VERSION ""

NS_ :

BS_:

BU_: ETH

BO_ 1480 EPBL_alertLog: 8 Vector__XXX
 SG_ EPBL_alertID M : 0|9@1+ (1,0) [0|0] "" Vector__XXX
 SG_ EPBL_alertState : 15|1@1+ (1,0) [0|0] "" Vector__XXX
 SG_ EPBL_a000_alertDataW0 m0 : 16|16@1+ (1,0) [0|0] "" Vector__XXX
 SG_ EPBL_a001_InternalWatchdog m1 : 16|1@1+ (1,0) [0|0] "" Vector__XXX
 SG_ EPBL_a002_CPUUndervoltage m2 : 16|1@1+ (1,0) [0|0] "" Vector__XXX
 SG_ EPBL_a003_AssertID m3 : 16|16@1+ (1,0) [0|0] "" Vector__XXX
 SG_ EPBL_a005_busID0 m5 : 16|4@1+ (1,0) [0|0] "" Vector__XXX
 SG_ EPBL_a006_busID m6 : 16|4@1+ (1,0) [0|0] "" Vector__XXX
 SG_ EPBL_a012_ClockError m12 : 16|1@1+ (1,0) [0|0] "" Vector__XXX
 SG_ EPBL_a013_LogQueueFull m13 : 16|1@1+ (1,0) [0|0] "" Vector__XXX
 SG_ EPBL_a015_NVMMMemOverflow m15 : 16|1@1+ (1,0) [0|0] "" Vector__XXX
 SG_ EPBL_a016_NVMMRecordID m16 : 16|16@1+ (1,0) [0|0] "" Vector__XXX
 SG_ EPBL_a021_Task1msLate m21 : 16|1@1+ (1,0) [0|0] "" Vector__XXX
 SG_ EPBL_a022_TaskInitErrorCount m22 : 16|8@1+ (1,0) [0|0] "" Vector__XXX
 SG_ EPBL_a030_logId m30 : 16|4@1+ (1,0) [0|0] "" Vector__XXX
 SG_ EPBL_a031_uds_bytes_0 m31 : 16|8@1+ (1,0) [0|0] "" Vector__XXX
 SG_ EPBL_a041_CPULoadTotal m41 : 16|8@1+ (1,0) [0|0] "" Vector__XXX
 SG_ EPBL_a042_Usage1msTask m42 : 16|8@1+ (1,0) [0|0] "" Vector__XXX
 SG_ EPBL_a043_CallTrace0 m43 : 16|24@1+ (1,0) [0|0] "" Vector__XXX
 SG_ EPBL_a044_CallTrace0 m44 : 16|24@1+ (1,0) [0|0] "" Vector__XXX
 SG_ EPBL_a045_CallTrace0 m45 : 16|24@1+ (1,0) [0|0] "" Vector__XXX
 SG_ EPBL_a046_CallTrace0 m46 : 16|24@1+ (1,0) [0|0] "" Vector__XXX
 SG_ EPBL_a057_VEH_cpControl m57 : 16|1@1+ (1,0) [0|0] "" Vector__XXX
 SG_ EPBL_a058_voltageDrop m58 : 16|12@1+ (0.005443676098,0) [0|0] "" Vector__XXX
 SG_ EPBL_a059_voltageDrop m59 : 16|12@1+ (0.005443676098,0) [0|0] "" Vector__XXX
 SG_ EPBL_a060_lockoutDisabled m60 : 16|1@1+ (1,0) [0|0] "" Vector__XXX
 SG_ EPBL_a063_switchChannel m63 : 16|8@1+ (1,0) [0|0] "" Vector__XXX
 SG_ EPBL_a064_busBitField m64 : 16|8@1+ (1,0) [0|0] "" Vector__XXX
 SG_ EPBL_a081_VEH_defogInfoMessage m81 : 16|1@1+ (1,0) [0|0] "" Vector__XXX
 SG_ EPBL_a082_RIPC_epbPrivateState m82 : 16|1@1+ (1,0) [0|0] "" Vector__XXX
 SG_ EPBL_a083_LIPC_epbPrivateState m83 : 16|1@1+ (1,0) [0|0] "" Vector__XXX
 SG_ EPBL_a084_CH_StatusC m84 : 16|1@1+ (1,0) [0|0] "" Vector__XXX
 SG_ EPBL_a085_PARTY_buttonStatus m85 : 16|1@1+ (1,0) [0|0] "" Vector__XXX
 SG_ EPBL_a086_VEH_LVBMS_statusHigh m86 : 16|1@1+ (1,0) [0|0] "" Vector__XXX
 SG_ EPBL_a087_VEH_temperature m87 : 16|1@1+ (1,0) [0|0] "" Vector__XXX
 SG_ EPBL_a088_VEH_temperature m88 : 16|1@1+ (1,0) [0|0] "" Vector__XXX
 SG_ EPBL_a089_PARTY_party1 m89 : 16|1@1+ (1,0) [0|0] "" Vector__XXX
 SG_ EPBL_a090_VEH_chNm m90 : 16|1@1+ (1,0) [0|0] "" Vector__XXX
 SG_ EPBL_a091_VEH_faultsAndExtras m91 : 16|1@1+ (1,0) [0|0] "" Vector__XXX
 SG_ EPBL_a092_VEH_restraintStatus m92 : 16|1@1+ (1,0) [0|0] "" Vector__XXX
 SG_ EPBL_a093_VEH_restraintStatus m93 : 16|1@1+ (1,0) [0|0] "" Vector__XXX
 SG_ EPBL_a094_VEH_sysStatus m94 : 16|1@1+ (1,0) [0|0] "" Vector__XXX
 SG_ EPBL_a095_PT_ptNm m95 : 16|1@1+ (1,0) [0|0] "" Vector__XXX
 SG_ EPBL_a096_VEH_status m96 : 16|1@1+ (1,0) [0|0] "" Vector__XXX
 SG_ EPBL_a097_VEH_HVStatus m97 : 16|1@1+ (1,0) [0|0] "" Vector__XXX
 SG_ EPBL_a098_CH_torque m98 : 16|1@1+ (1,0) [0|0] "" Vector__XXX
 SG_ EPBL_a099_VEH_oocStatus m99 : 16|1@1+ (1,0) [0|0] "" Vector__XXX
 SG_ EPBL_a100_VEH m100 : 16|1@1+ (1,0) [0|0] "" Vector__XXX
 SG_ EPBL_a101_VEH_state m101 : 16|1@1+ (1,0) [0|0] "" Vector__XXX
 SG_ EPBL_a102_VEH_faultsAndExtras m102 : 16|1@1+ (1,0) [0|0] "" Vector__XXX
 SG_ EPBL_a103_VEH_hvsNm m103 : 16|1@1+ (1,0) [0|0] "" Vector__XXX
 SG_ EPBL_a104_PARTY_redundantBrakingControl m104 : 16|1@1+ (1,0) [0|0] "" Vector__XXX
 SG_ EPBL_a105_VEH_states m105 : 16|1@1+ (1,0) [0|0] "" Vector__XXX
 SG_ EPBL_a106_VEH_dcdcStatus m106 : 16|1@1+ (1,0) [0|0] "" Vector__XXX
 SG_ EPBL_a107_VEH_hvsNm m107 : 16|1@1+ (1,0) [0|0] "" Vector__XXX
 SG_ EPBL_a108_VEH_hvStatus m108 : 16|1@1+ (1,0) [0|0] "" Vector__XXX
 SG_ EPBL_a109_PARTY_status m109 : 16|1@1+ (1,0) [0|0] "" Vector__XXX
 SG_ EPBL_a110_VEH_powerRequests m110 : 16|1@1+ (1,0) [0|0] "" Vector__XXX
 SG_ EPBL_a111_VEH_internalStatus m111 : 16|1@1+ (1,0) [0|0] "" Vector__XXX
 SG_ EPBL_a112_VEH_internalStatus m112 : 16|1@1+ (1,0) [0|0] "" Vector__XXX
 SG_ EPBL_a113_VEH_ethNm m113 : 16|1@1+ (1,0) [0|0] "" Vector__XXX
 SG_ EPBL_a114_PARTY_status m114 : 16|1@1+ (1,0) [0|0] "" Vector__XXX
 SG_ EPBL_a115_VEH_vehNm m115 : 16|1@1+ (1,0) [0|0] "" Vector__XXX
 SG_ EPBL_a116_LIPC_doorStatus m116 : 16|1@1+ (1,0) [0|0] "" Vector__XXX
 SG_ EPBL_a117_LIPC_doorStatus m117 : 16|1@1+ (1,0) [0|0] "" Vector__XXX
 SG_ EPBL_a118_VEH_vehNm m118 : 16|1@1+ (1,0) [0|0] "" Vector__XXX
 SG_ EPBL_a119_VEH_steerAngle m119 : 16|1@1+ (1,0) [0|0] "" Vector__XXX
 SG_ EPBL_a120_PARTY_chassisCntl m120 : 16|1@1+ (1,0) [0|0] "" Vector__XXX
 SG_ EPBL_a121_caliperState m121 : 16|4@1+ (1,0) [0|0] "" Vector__XXX
 SG_ EPBL_a122_filteredCurrentCal m122 : 16|12@1+ (0.01,0) [0|0] "" Vector__XXX
 SG_ EPBL_a123_filteredCurrentCal m123 : 16|12@1+ (0.01,0) [0|0] "" Vector__XXX
 SG_ EPBL_a124_calOutOfBoundsData m124 : 16|1@1+ (1,0) [0|0] "" Vector__XXX
 SG_ EPBL_a125_pvFilt m125 : 16|12@1+ (0.005443676098,0) [0|0] "" Vector__XXX
 SG_ EPBL_a126_pvFilt m126 : 16|12@1+ (0.005443676098,0) [0|0] "" Vector__XXX
 SG_ EPBL_a127_pvFilt m127 : 16|12@1+ (0.005443676098,0) [0|0] "" Vector__XXX
 SG_ EPBL_a128_pvFilt m128 : 16|12@1+ (0.005443676098,0) [0|0] "" Vector__XXX
 SG_ EPBL_a129_VEH_occupancy m129 : 16|1@1+ (1,0) [0|0] "" Vector__XXX
 SG_ EPBL_a134_pvFilt m134 : 16|12@1+ (0.005443676098,0) [0|0] "" Vector__XXX
 SG_ EPBL_a135_pvFilt m135 : 16|12@1+ (0.005443676098,0) [0|0] "" Vector__XXX
 SG_ EPBL_a136_pvFilt m136 : 16|12@1+ (0.005443676098,0) [0|0] "" Vector__XXX
 SG_ EPBL_a137_pvFilt m137 : 16|12@1+ (0.005443676098,0) [0|0] "" Vector__XXX
 SG_ EPBL_a138_localState m138 : 16|3@1+ (1,0) [0|0] "" Vector__XXX
 SG_ EPBL_a139_localState m139 : 16|3@1+ (1,0) [0|0] "" Vector__XXX
 SG_ EPBL_a140_stateTime m140 : 16|32@1+ (1,0) [0|0] "" Vector__XXX
 SG_ EPBL_a141_fromState m141 : 16|5@1+ (1,0) [0|0] "" Vector__XXX
 SG_ EPBL_a170_pvFilt m170 : 16|12@1+ (0.005443676098,0) [0|0] "" Vector__XXX
 SG_ EPBL_a171_pvFilt m171 : 16|12@1+ (0.005443676098,0) [0|0] "" Vector__XXX
 SG_ EPBL_a173_esmState m173 : 16|5@1+ (1,0) [0|0] "" Vector__XXX
 SG_ EPBL_a174_esmState m174 : 16|5@1+ (1,0) [0|0] "" Vector__XXX
 SG_ EPBL_a175_esmState m175 : 16|5@1+ (1,0) [0|0] "" Vector__XXX
 SG_ EPBL_a176_esmState m176 : 16|5@1+ (1,0) [0|0] "" Vector__XXX
 SG_ EPBL_a177_esmState m177 : 16|5@1+ (1,0) [0|0] "" Vector__XXX
 SG_ EPBL_a178_localCaliperState m178 : 16|3@1+ (1,0) [0|0] "" Vector__XXX
 SG_ EPBL_a179_esmState m179 : 16|5@1+ (1,0) [0|0] "" Vector__XXX
 SG_ EPBL_a180_esmOpTrigger m180 : 16|6@1+ (1,0) [0|0] "" Vector__XXX
 SG_ EPBL_a181_grade m181 : 16|7@1- (1,0) [0|0] "" Vector__XXX
 SG_ EPBL_a182_epbSystemStatus m182 : 16|4@1+ (1,0) [0|0] "" Vector__XXX
 SG_ EPBL_a183_isRetransmit m183 : 16|1@1+ (1,0) [0|0] "" Vector__XXX
 SG_ EPBL_a184_esmOpTrigger m184 : 16|6@1+ (1,0) [0|0] "" Vector__XXX
 SG_ EPBL_a185_summonFaultReason m185 : 16|5@1+ (1,0) [0|0] "" Vector__XXX
 SG_ EPBL_a186_esmOpTrigger m186 : 16|6@1+ (1,0) [0|0] "" Vector__XXX
 SG_ EPBL_a187_esmOpTrigger m187 : 16|6@1+ (1,0) [0|0] "" Vector__XXX
 SG_ EPBL_a188_esmOpTrigger m188 : 16|6@1+ (1,0) [0|0] "" Vector__XXX
 SG_ EPBL_a189_esmOpTrigger m189 : 16|6@1+ (1,0) [0|0] "" Vector__XXX
 SG_ EPBL_a190_esmState m190 : 16|5@1+ (1,0) [0|0] "" Vector__XXX
 SG_ EPBL_a191_esmState m191 : 16|5@1+ (1,0) [0|0] "" Vector__XXX
 SG_ EPBL_a198_voltageAvgDelta m198 : 16|9@1+ (0.043549408784,0) [0|0] "" Vector__XXX
 SG_ EPBL_a202_localEpbConfig m202 : 16|4@1+ (1,0) [0|0] "" Vector__XXX
 SG_ EPBL_a203_gtwConfig m203 : 16|4@1+ (1,0) [0|0] "" Vector__XXX
 SG_ EPBL_a210_driverLeftForScore m210 : 16|1@1+ (1,0) [0|0] "" Vector__XXX
 SG_ EPBL_a216_noData m216 : 16|1@1+ (1,0) [0|0] "" Vector__XXX
 SG_ EPBL_a217_byte4 m217 : 16|8@1+ (1,0) [0|0] "" Vector__XXX
 SG_ EPBL_a225_esmOpTrigger m225 : 16|6@1+ (1,0) [0|0] "" Vector__XXX
 SG_ EPBL_a241_desiredState m241 : 16|1@1+ (1,0) [0|0] "" Vector__XXX
 SG_ EPBL_a242_hvcDesiredState m242 : 16|1@1+ (1,0) [0|0] "" Vector__XXX
 SG_ EPBL_a243_brakeMasterCylPress m243 : 16|1@1+ (1,0) [0|0] "" Vector__XXX
 SG_ EPBL_a244_permissiveMode m244 : 16|1@1+ (1,0) [0|0] "" Vector__XXX
 SG_ EPBL_a246_previousState m246 : 16|5@1+ (1,0) [0|0] "" Vector__XXX
 SG_ EPBL_a247_esmState m247 : 16|5@1+ (1,0) [0|0] "" Vector__XXX
 SG_ EPBL_a248_esmState m248 : 16|5@1+ (1,0) [0|0] "" Vector__XXX
 SG_ EPBL_a249_previousState m249 : 16|5@1+ (1,0) [0|0] "" Vector__XXX
 SG_ EPBL_a250_esmSpeedClass m250 : 16|3@1+ (1,0) [0|0] "" Vector__XXX
 SG_ EPBL_a251_currentVariance m251 : 16|12@1+ (0.01,0) [0|0] "" Vector__XXX
 SG_ EPBL_a253_esmState m253 : 16|5@1+ (1,0) [0|0] "" Vector__XXX
 SG_ EPBL_a256_esmState m256 : 16|5@1+ (1,0) [0|0] "" Vector__XXX
 SG_ EPBL_a262_inputVoltageTooLow m262 : 16|1@1+ (1,0) [0|0] "" Vector__XXX
 SG_ EPBL_a263_esmState m263 : 16|5@1+ (1,0) [0|0] "" Vector__XXX
 SG_ EPBL_a264_uiWinchModeRequestExit m264 : 16|1@1+ (1,0) [0|0] "" Vector__XXX
 SG_ EPBL_a272_expectedState m272 : 16|2@1+ (1,0) [0|0] "" Vector__XXX
 SG_ EPBL_a300_harnessId m300 : 16|8@1+ (1,0) [0|0] "" Vector__XXX
 SG_ EPBL_a301_setSpeed m301 : 16|16@1+ (0.05,0) [0|0] "" Vector__XXX
 SG_ EPBL_a302_pistonPosition m302 : 16|13@1- (9.768009768009769,0) [0|0] "" Vector__XXX
 SG_ EPBL_a303_currentVariance m303 : 16|12@1+ (0.01,0) [0|0] "" Vector__XXX
 SG_ EPBL_a350_ensPeriod m350 : 16|16@1+ (0.0001,0) [0|0] "" Vector__XXX
 SG_ EPBL_a352_pointsAboveThreshold m352 : 16|10@1+ (1,0) [0|0] "" Vector__XXX
 SG_ EPBL_a353_alertPath m353 : 16|2@1+ (1,0) [0|0] "" Vector__XXX
 SG_ EPBL_a355_brakeHwConfig m355 : 16|4@1+ (1,0) [0|0] "" Vector__XXX
 SG_ EPBL_a357_epbSystemStatus m357 : 16|4@1+ (1,0) [0|0] "" Vector__XXX
 SG_ EPBL_a358_epbSystemStatus m358 : 16|4@1+ (1,0) [0|0] "" Vector__XXX
 SG_ EPBL_a362_brakeMasterCylPress m362 : 16|12@1- (0.1,130) [0|0] "" Vector__XXX
 SG_ EPBL_a363_brakeMasterCylPress m363 : 16|12@1- (0.1,130) [0|0] "" Vector__XXX
 SG_ EPBL_a364_masterCylOffsetComp m364 : 16|12@1- (0.05,0) [0|0] "" Vector__XXX
 SG_ EPBL_a365_epbSystemStatus m365 : 16|4@1+ (1,0) [0|0] "" Vector__XXX
 SG_ EPBL_a366_epbSystemStatus m366 : 16|4@1+ (1,0) [0|0] "" Vector__XXX
 SG_ EPBL_a370_messageID m370 : 16|11@1+ (1,0) [0|0] "" Vector__XXX
 SG_ EPBL_a002_PowerOnReset m2 : 17|1@1+ (1,0) [0|0] "" Vector__XXX
 SG_ EPBL_a012_FlashError m12 : 17|1@1+ (1,0) [0|0] "" Vector__XXX
 SG_ EPBL_a013_ClearQueueFull m13 : 17|1@1+ (1,0) [0|0] "" Vector__XXX
 SG_ EPBL_a015_NVMMFilesystemError m15 : 17|1@1+ (1,0) [0|0] "" Vector__XXX
 SG_ EPBL_a021_Task1msStarved m21 : 17|1@1+ (1,0) [0|0] "" Vector__XXX
 SG_ EPBL_a060_resetUnlocked m60 : 17|1@1+ (1,0) [0|0] "" Vector__XXX
 SG_ EPBL_a082_RIPC_remoteHSD m82 : 17|1@1+ (1,0) [0|0] "" Vector__XXX
 SG_ EPBL_a083_LIPC_remoteHSD m83 : 17|1@1+ (1,0) [0|0] "" Vector__XXX
 SG_ EPBL_a086_VEH_LVBMS_statusLow m86 : 17|1@1+ (1,0) [0|0] "" Vector__XXX
 SG_ EPBL_a087_VEH_thermalControl m87 : 17|1@1+ (1,0) [0|0] "" Vector__XXX
 SG_ EPBL_a088_VEH_thermalControl m88 : 17|1@1+ (1,0) [0|0] "" Vector__XXX
 SG_ EPBL_a089_PARTY_status m89 : 17|1@1+ (1,0) [0|0] "" Vector__XXX
 SG_ EPBL_a090_VEH_state m90 : 17|1@1+ (1,0) [0|0] "" Vector__XXX
 SG_ EPBL_a091_VEH_info m91 : 17|1@1+ (1,0) [0|0] "" Vector__XXX
 SG_ EPBL_a092_VEH_switchStatus m92 : 17|1@1+ (1,0) [0|0] "" Vector__XXX
 SG_ EPBL_a093_VEH_switchStatus m93 : 17|1@1+ (1,0) [0|0] "" Vector__XXX
 SG_ EPBL_a094_PARTY_sysStatus m94 : 17|1@1+ (1,0) [0|0] "" Vector__XXX
 SG_ EPBL_a095_PT_status m95 : 17|1@1+ (1,0) [0|0] "" Vector__XXX
 SG_ EPBL_a096_CH_status m96 : 17|1@1+ (1,0) [0|0] "" Vector__XXX
 SG_ EPBL_a097_VEH_state m97 : 17|1@1+ (1,0) [0|0] "" Vector__XXX
 SG_ EPBL_a098_VEH_hvStatus m98 : 17|1@1+ (1,0) [0|0] "" Vector__XXX
 SG_ EPBL_a100_PARTY m100 : 17|1@1+ (1,0) [0|0] "" Vector__XXX
 SG_ EPBL_a101_PARTY_locState m101 : 17|1@1+ (1,0) [0|0] "" Vector__XXX
 SG_ EPBL_a102_VEH_feedbackStatus m102 : 17|1@1+ (1,0) [0|0] "" Vector__XXX
 SG_ EPBL_a103_VEH_vehNm m103 : 17|1@1+ (1,0) [0|0] "" Vector__XXX
 SG_ EPBL_a104_CH_redundantBrakingControl m104 : 17|1@1+ (1,0) [0|0] "" Vector__XXX
 SG_ EPBL_a105_VEH_chNm m105 : 17|1@1+ (1,0) [0|0] "" Vector__XXX
 SG_ EPBL_a106_VEH_thermalControl m106 : 17|1@1+ (1,0) [0|0] "" Vector__XXX
 SG_ EPBL_a107_VEH_vehNm m107 : 17|1@1+ (1,0) [0|0] "" Vector__XXX
 SG_ EPBL_a108_VEH_temperature m108 : 17|1@1+ (1,0) [0|0] "" Vector__XXX
 SG_ EPBL_a109_PARTY_inertial2 m109 : 17|1@1+ (1,0) [0|0] "" Vector__XXX
 SG_ EPBL_a110_VEH_carState m110 : 17|1@1+ (1,0) [0|0] "" Vector__XXX
 SG_ EPBL_a111_VEH_status m111 : 17|1@1+ (1,0) [0|0] "" Vector__XXX
 SG_ EPBL_a112_VEH_status m112 : 17|1@1+ (1,0) [0|0] "" Vector__XXX
 SG_ EPBL_a113_VEH_hvacRequest m113 : 17|1@1+ (1,0) [0|0] "" Vector__XXX
 SG_ EPBL_a114_PARTY_wheelSpeeds m114 : 17|1@1+ (1,0) [0|0] "" Vector__XXX
 SG_ EPBL_a115_VEH_authentication m115 : 17|1@1+ (1,0) [0|0] "" Vector__XXX
 SG_ EPBL_a116_RIPC_doorStatus m116 : 17|1@1+ (1,0) [0|0] "" Vector__XXX
 SG_ EPBL_a117_RIPC_doorStatus m117 : 17|1@1+ (1,0) [0|0] "" Vector__XXX
 SG_ EPBL_a118_VEH_lighting m118 : 17|1@1+ (1,0) [0|0] "" Vector__XXX
 SG_ EPBL_a119_VEH_leftStalk m119 : 17|1@1+ (1,0) [0|0] "" Vector__XXX
 SG_ EPBL_a120_VEH_systemStatus m120 : 17|1@1+ (1,0) [0|0] "" Vector__XXX
 SG_ EPBL_a183_localCdpState m183 : 17|2@1+ (1,0) [0|0] "" Vector__XXX
 SG_ EPBL_a210_driverLeftForAllSensors m210 : 17|1@1+ (1,0) [0|0] "" Vector__XXX
 SG_ EPBL_a216_spiFault m216 : 17|1@1+ (1,0) [0|0] "" Vector__XXX
 SG_ EPBL_a241_currentState m241 : 17|1@1+ (1,0) [0|0] "" Vector__XXX
 SG_ EPBL_a242_hvcCurrentState m242 : 17|1@1+ (1,0) [0|0] "" Vector__XXX
 SG_ EPBL_a243_brakeMasterCylPressQF m243 : 17|1@1+ (1,0) [0|0] "" Vector__XXX
 SG_ EPBL_a262_notStopped m262 : 17|1@1+ (1,0) [0|0] "" Vector__XXX
 SG_ EPBL_a264_uiGearStripParkPressed m264 : 17|1@1+ (1,0) [0|0] "" Vector__XXX
 SG_ EPBL_a012_SoftwareReset m12 : 18|1@1+ (1,0) [0|0] "" Vector__XXX
 SG_ EPBL_a015_NVMMRecordIDError m15 : 18|1@1+ (1,0) [0|0] "" Vector__XXX
 SG_ EPBL_a021_Task1msMissed m21 : 18|1@1+ (1,0) [0|0] "" Vector__XXX
 SG_ EPBL_a082_RIPC_railStatus m82 : 18|1@1+ (1,0) [0|0] "" Vector__XXX
 SG_ EPBL_a083_LIPC_railStatus m83 : 18|1@1+ (1,0) [0|0] "" Vector__XXX
 SG_ EPBL_a086_VEH_status m86 : 18|1@1+ (1,0) [0|0] "" Vector__XXX
 SG_ EPBL_a087_VEH_torque m87 : 18|1@1+ (1,0) [0|0] "" Vector__XXX
 SG_ EPBL_a088_VEH_torque m88 : 18|1@1+ (1,0) [0|0] "" Vector__XXX
 SG_ EPBL_a089_VEH_status m89 : 18|1@1+ (1,0) [0|0] "" Vector__XXX
 SG_ EPBL_a090_PARTY_eacMonitor m90 : 18|1@1+ (1,0) [0|0] "" Vector__XXX
 SG_ EPBL_a091_VEH_state m91 : 18|1@1+ (1,0) [0|0] "" Vector__XXX
 SG_ EPBL_a092_VEH_seatStatus2 m92 : 18|1@1+ (1,0) [0|0] "" Vector__XXX
 SG_ EPBL_a093_VEH_seatStatus2 m93 : 18|1@1+ (1,0) [0|0] "" Vector__XXX
 SG_ EPBL_a098_VEH_status m98 : 18|1@1+ (1,0) [0|0] "" Vector__XXX
 SG_ EPBL_a100_PT m100 : 18|1@1+ (1,0) [0|0] "" Vector__XXX
 SG_ EPBL_a101_LIPC_externalWatchdogHeartBeat m101 : 18|1@1+ (1,0) [0|0] "" Vector__XXX
 SG_ EPBL_a102_VEH_sensorStatus m102 : 18|1@1+ (1,0) [0|0] "" Vector__XXX
 SG_ EPBL_a103_VEH_status m103 : 18|1@1+ (1,0) [0|0] "" Vector__XXX
 SG_ EPBL_a104_LIPC_status m104 : 18|1@1+ (1,0) [0|0] "" Vector__XXX
 SG_ EPBL_a105_VEH_dampingStates m105 : 18|1@1+ (1,0) [0|0] "" Vector__XXX
 SG_ EPBL_a106_VEH_dcdcRailStatus m106 : 18|1@1+ (1,0) [0|0] "" Vector__XXX
 SG_ EPBL_a107_VEH_status m107 : 18|1@1+ (1,0) [0|0] "" Vector__XXX
 SG_ EPBL_a108_VEH_thermalControl m108 : 18|1@1+ (1,0) [0|0] "" Vector__XXX
 SG_ EPBL_a109_PARTY_nearDeploy m109 : 18|1@1+ (1,0) [0|0] "" Vector__XXX
 SG_ EPBL_a110_VEH_carConfig m110 : 18|1@1+ (1,0) [0|0] "" Vector__XXX
 SG_ EPBL_a111_VEH_vehNm m111 : 18|1@1+ (1,0) [0|0] "" Vector__XXX
 SG_ EPBL_a112_VEH_vehNm m112 : 18|1@1+ (1,0) [0|0] "" Vector__XXX
 SG_ EPBL_a113_VEH_chargeRequest m113 : 18|1@1+ (1,0) [0|0] "" Vector__XXX
 SG_ EPBL_a114_VEH_wheelSpeeds m114 : 18|1@1+ (1,0) [0|0] "" Vector__XXX
 SG_ EPBL_a115_VEH_BLEResetRequest m115 : 18|1@1+ (1,0) [0|0] "" Vector__XXX
 SG_ EPBL_a116_RIPC_epbManagement m116 : 18|1@1+ (1,0) [0|0] "" Vector__XXX
 SG_ EPBL_a117_BDY_epbmStatus m117 : 18|1@1+ (1,0) [0|0] "" Vector__XXX
 SG_ EPBL_a118_VEH_sensors m118 : 18|1@1+ (1,0) [0|0] "" Vector__XXX
 SG_ EPBL_a119_VEH_rightStalk m119 : 18|1@1+ (1,0) [0|0] "" Vector__XXX
 SG_ EPBL_a120_CH_chassisCntl m120 : 18|1@1+ (1,0) [0|0] "" Vector__XXX
 SG_ EPBL_a210_driverLeftForDoorOpen m210 : 18|1@1+ (1,0) [0|0] "" Vector__XXX
 SG_ EPBL_a216_CRC_error m216 : 18|1@1+ (1,0) [0|0] "" Vector__XXX
 SG_ EPBL_a241_diKeepAlive m241 : 18|1@1+ (1,0) [0|0] "" Vector__XXX
 SG_ EPBL_a242_contDesiredState m242 : 18|1@1+ (1,0) [0|0] "" Vector__XXX
 SG_ EPBL_a243_drivetrainType m243 : 18|1@1+ (1,0) [0|0] "" Vector__XXX
 SG_ EPBL_a262_notSecure m262 : 18|1@1+ (1,0) [0|0] "" Vector__XXX
 SG_ EPBL_a264_uiControlsParkingBrakeRequest m264 : 18|1@1+ (1,0) [0|0] "" Vector__XXX
 SG_ EPBL_a272_actualState m272 : 18|2@1+ (1,0) [0|0] "" Vector__XXX
 SG_ EPBL_a353_gtwMia m353 : 18|1@1+ (1,0) [0|0] "" Vector__XXX
 SG_ EPBL_a012_CheckstopReset m12 : 19|1@1+ (1,0) [0|0] "" Vector__XXX
 SG_ EPBL_a021_Task10msLate m21 : 19|1@1+ (1,0) [0|0] "" Vector__XXX
 SG_ EPBL_a082_RIPC_remoteMux m82 : 19|1@1+ (1,0) [0|0] "" Vector__XXX
 SG_ EPBL_a083_LIPC_HSDFaults m83 : 19|1@1+ (1,0) [0|0] "" Vector__XXX
 SG_ EPBL_a086_VEH_12VBatteryStatus m86 : 19|1@1+ (1,0) [0|0] "" Vector__XXX
 SG_ EPBL_a087_VEH_status m87 : 19|1@1+ (1,0) [0|0] "" Vector__XXX
 SG_ EPBL_a088_VEH_status m88 : 19|1@1+ (1,0) [0|0] "" Vector__XXX
 SG_ EPBL_a089_BDY_party1 m89 : 19|1@1+ (1,0) [0|0] "" Vector__XXX
 SG_ EPBL_a090_CH_eacMonitor m90 : 19|1@1+ (1,0) [0|0] "" Vector__XXX
 SG_ EPBL_a092_VEH_vehNm m92 : 19|1@1+ (1,0) [0|0] "" Vector__XXX
 SG_ EPBL_a093_VEH_vehNm m93 : 19|1@1+ (1,0) [0|0] "" Vector__XXX
 SG_ EPBL_a098_VEH_thermalControl m98 : 19|1@1+ (1,0) [0|0] "" Vector__XXX
 SG_ EPBL_a100_CH m100 : 19|1@1+ (1,0) [0|0] "" Vector__XXX
 SG_ EPBL_a101_VEH_locState m101 : 19|1@1+ (1,0) [0|0] "" Vector__XXX
 SG_ EPBL_a102_VEH_rods m102 : 19|1@1+ (1,0) [0|0] "" Vector__XXX
 SG_ EPBL_a103_PT_ptNm m103 : 19|1@1+ (1,0) [0|0] "" Vector__XXX
 SG_ EPBL_a104_VEH_chNm m104 : 19|1@1+ (1,0) [0|0] "" Vector__XXX
 SG_ EPBL_a106_CH_dcdcRailStatus m106 : 19|1@1+ (1,0) [0|0] "" Vector__XXX
 SG_ EPBL_a107_VEH_thermalStatus m107 : 19|1@1+ (1,0) [0|0] "" Vector__XXX
 SG_ EPBL_a108_VEH_torque m108 : 19|1@1+ (1,0) [0|0] "" Vector__XXX
 SG_ EPBL_a109_PARTY_collision m109 : 19|1@1+ (1,0) [0|0] "" Vector__XXX
 SG_ EPBL_a110_VEH_time m110 : 19|1@1+ (1,0) [0|0] "" Vector__XXX
 SG_ EPBL_a111_RIPC_LVPowerState m111 : 19|1@1+ (1,0) [0|0] "" Vector__XXX
 SG_ EPBL_a112_LIPC_LVPowerState m112 : 19|1@1+ (1,0) [0|0] "" Vector__XXX
 SG_ EPBL_a113_VEH_vehicleControl m113 : 19|1@1+ (1,0) [0|0] "" Vector__XXX
 SG_ EPBL_a114_CH_wheelSpeeds m114 : 19|1@1+ (1,0) [0|0] "" Vector__XXX
 SG_ EPBL_a115_VEH_requests m115 : 19|1@1+ (1,0) [0|0] "" Vector__XXX
 SG_ EPBL_a116_PARTY_epbmStatus m116 : 19|1@1+ (1,0) [0|0] "" Vector__XXX
 SG_ EPBL_a117_BDY_restraintStatus m117 : 19|1@1+ (1,0) [0|0] "" Vector__XXX
 SG_ EPBL_a118_VEH_status m118 : 19|1@1+ (1,0) [0|0] "" Vector__XXX
 SG_ EPBL_a119_PARTY_rightStalk m119 : 19|1@1+ (1,0) [0|0] "" Vector__XXX
 SG_ EPBL_a120_PARTY_systemStatus m120 : 19|1@1+ (1,0) [0|0] "" Vector__XXX
 SG_ EPBL_a138_monitorState m138 : 19|3@1+ (1,0) [0|0] "" Vector__XXX
 SG_ EPBL_a139_monitorState m139 : 19|3@1+ (1,0) [0|0] "" Vector__XXX
 SG_ EPBL_a178_monitorCaliperState m178 : 19|3@1+ (1,0) [0|0] "" Vector__XXX
 SG_ EPBL_a183_remoteCdpState m183 : 19|2@1+ (1,0) [0|0] "" Vector__XXX
 SG_ EPBL_a210_driverLeftForUnbuckled m210 : 19|1@1+ (1,0) [0|0] "" Vector__XXX
 SG_ EPBL_a216_monitor_MIA m216 : 19|1@1+ (1,0) [0|0] "" Vector__XXX
 SG_ EPBL_a241_epbSysStatus m241 : 19|4@1+ (1,0) [0|0] "" Vector__XXX
 SG_ EPBL_a242_contCurrentState m242 : 19|1@1+ (1,0) [0|0] "" Vector__XXX
 SG_ EPBL_a243_DIR1torqueActual m243 : 19|1@1+ (1,0) [0|0] "" Vector__XXX
 SG_ EPBL_a262_chargeCableDefinitelyAttached m262 : 19|1@1+ (1,0) [0|0] "" Vector__XXX
 SG_ EPBL_a264_stalkParkPressed m264 : 19|1@1+ (1,0) [0|0] "" Vector__XXX
 SG_ EPBL_a353_uiMia m353 : 19|1@1+ (1,0) [0|0] "" Vector__XXX
 SG_ EPBL_a005_faults0 m5 : 20|12@1+ (1,0) [0|0] "" Vector__XXX
 SG_ EPBL_a006_fault m6 : 20|4@1+ (1,0) [0|0] "" Vector__XXX
 SG_ EPBL_a012_DebugReset m12 : 20|1@1+ (1,0) [0|0] "" Vector__XXX
 SG_ EPBL_a021_Task10msStarved m21 : 20|1@1+ (1,0) [0|0] "" Vector__XXX
 SG_ EPBL_a086_VEH_LVPowerState m86 : 20|1@1+ (1,0) [0|0] "" Vector__XXX
 SG_ EPBL_a087_PARTY_torque m87 : 20|1@1+ (1,0) [0|0] "" Vector__XXX
 SG_ EPBL_a088_PARTY_torque m88 : 20|1@1+ (1,0) [0|0] "" Vector__XXX
 SG_ EPBL_a089_BDY_status m89 : 20|1@1+ (1,0) [0|0] "" Vector__XXX
 SG_ EPBL_a098_VEH_temperature m98 : 20|1@1+ (1,0) [0|0] "" Vector__XXX
 SG_ EPBL_a100_OBD m100 : 20|1@1+ (1,0) [0|0] "" Vector__XXX
 SG_ EPBL_a101_BDY_locState m101 : 20|1@1+ (1,0) [0|0] "" Vector__XXX
 SG_ EPBL_a103_PT_status m103 : 20|1@1+ (1,0) [0|0] "" Vector__XXX
 SG_ EPBL_a104_VEH_bodyControls m104 : 20|1@1+ (1,0) [0|0] "" Vector__XXX
 SG_ EPBL_a106_CH_alertMatrix m106 : 20|1@1+ (1,0) [0|0] "" Vector__XXX
 SG_ EPBL_a107_VEH_bmbMinMax m107 : 20|1@1+ (1,0) [0|0] "" Vector__XXX
 SG_ EPBL_a108_VEH_status m108 : 20|1@1+ (1,0) [0|0] "" Vector__XXX
 SG_ EPBL_a109_VEH_status m109 : 20|1@1+ (1,0) [0|0] "" Vector__XXX
 SG_ EPBL_a110_VEH_updateStatus m110 : 20|1@1+ (1,0) [0|0] "" Vector__XXX
 SG_ EPBL_a111_RIPC_epbPrivateState m111 : 20|1@1+ (1,0) [0|0] "" Vector__XXX
 SG_ EPBL_a112_LIPC_epbPrivateState m112 : 20|1@1+ (1,0) [0|0] "" Vector__XXX
 SG_ EPBL_a113_VEH_vehicleControl2 m113 : 20|1@1+ (1,0) [0|0] "" Vector__XXX
 SG_ EPBL_a114_PARTY_party3 m114 : 20|1@1+ (1,0) [0|0] "" Vector__XXX
 SG_ EPBL_a115_VEH_requests2 m115 : 20|1@1+ (1,0) [0|0] "" Vector__XXX
 SG_ EPBL_a116_VEH_vehNm m116 : 20|1@1+ (1,0) [0|0] "" Vector__XXX
 SG_ EPBL_a117_VEH_prndStatus m117 : 20|1@1+ (1,0) [0|0] "" Vector__XXX
 SG_ EPBL_a118_VEH_okToUseHighPwr m118 : 20|1@1+ (1,0) [0|0] "" Vector__XXX
 SG_ EPBL_a119_CH_steerAngle m119 : 20|1@1+ (1,0) [0|0] "" Vector__XXX
 SG_ EPBL_a120_PARTY_torque m120 : 20|1@1+ (1,0) [0|0] "" Vector__XXX
 SG_ EPBL_a202_remoteEpbConfig m202 : 20|4@1+ (1,0) [0|0] "" Vector__XXX
 SG_ EPBL_a203_epbConfig m203 : 20|4@1+ (1,0) [0|0] "" Vector__XXX
 SG_ EPBL_a210_driverLeftForInactivity m210 : 20|1@1+ (1,0) [0|0] "" Vector__XXX
 SG_ EPBL_a242_hvState m242 : 20|3@1+ (1,0) [0|0] "" Vector__XXX
 SG_ EPBL_a243_DIR2torqueActual m243 : 20|1@1+ (1,0) [0|0] "" Vector__XXX
 SG_ EPBL_a262_chargeCablePotentiallyAttached m262 : 20|1@1+ (1,0) [0|0] "" Vector__XXX
 SG_ EPBL_a264_backupPrndParkPressed m264 : 20|1@1+ (1,0) [0|0] "" Vector__XXX
 SG_ EPBL_a355_epbHwConfig m355 : 20|4@1+ (1,0) [0|0] "" Vector__XXX
 SG_ EPBL_a012_ExternalReset m12 : 21|1@1+ (1,0) [0|0] "" Vector__XXX
 SG_ EPBL_a021_Task10msMissed m21 : 21|1@1+ (1,0) [0|0] "" Vector__XXX
 SG_ EPBL_a086_VEH_lightStatus m86 : 21|1@1+ (1,0) [0|0] "" Vector__XXX
 SG_ EPBL_a087_PARTY_status m87 : 21|1@1+ (1,0) [0|0] "" Vector__XXX
 SG_ EPBL_a088_PARTY_status m88 : 21|1@1+ (1,0) [0|0] "" Vector__XXX
 SG_ EPBL_a089_CH_status m89 : 21|1@1+ (1,0) [0|0] "" Vector__XXX
 SG_ EPBL_a098_VEH_torque m98 : 21|1@1+ (1,0) [0|0] "" Vector__XXX
 SG_ EPBL_a103_VEH_evseStatus m103 : 21|1@1+ (1,0) [0|0] "" Vector__XXX
 SG_ EPBL_a104_VEH_bodyControls3 m104 : 21|1@1+ (1,0) [0|0] "" Vector__XXX
 SG_ EPBL_a107_VEH_powerAvailable m107 : 21|1@1+ (1,0) [0|0] "" Vector__XXX
 SG_ EPBL_a108_PARTY_torque m108 : 21|1@1+ (1,0) [0|0] "" Vector__XXX
 SG_ EPBL_a109_VEH_imuOffsets m109 : 21|1@1+ (1,0) [0|0] "" Vector__XXX
 SG_ EPBL_a110_VEH_vehNm m110 : 21|1@1+ (1,0) [0|0] "" Vector__XXX
 SG_ EPBL_a111_RIPC_railStatus m111 : 21|1@1+ (1,0) [0|0] "" Vector__XXX
 SG_ EPBL_a112_LIPC_railStatus m112 : 21|1@1+ (1,0) [0|0] "" Vector__XXX
 SG_ EPBL_a113_VEH_peripheralPowerRequests m113 : 21|1@1+ (1,0) [0|0] "" Vector__XXX
 SG_ EPBL_a114_VEH_party3 m114 : 21|1@1+ (1,0) [0|0] "" Vector__XXX
 SG_ EPBL_a115_REM_authentication m115 : 21|1@1+ (1,0) [0|0] "" Vector__XXX
 SG_ EPBL_a116_VEH_hvacRequest m116 : 21|1@1+ (1,0) [0|0] "" Vector__XXX
 SG_ EPBL_a117_PARTY_epbmStatus m117 : 21|1@1+ (1,0) [0|0] "" Vector__XXX
 SG_ EPBL_a118_VEH_LVPowerState m118 : 21|1@1+ (1,0) [0|0] "" Vector__XXX
 SG_ EPBL_a119_PARTY_steerAngle m119 : 21|1@1+ (1,0) [0|0] "" Vector__XXX
 SG_ EPBL_a120_VEH_torque m120 : 21|1@1+ (1,0) [0|0] "" Vector__XXX
 SG_ EPBL_a183_espCdpStatus m183 : 21|2@1+ (1,0) [0|0] "" Vector__XXX
 SG_ EPBL_a210_driverIsLeavingSpeedClass m210 : 21|3@1+ (1,0) [0|0] "" Vector__XXX
 SG_ EPBL_a243_DIFtorqueActual m243 : 21|1@1+ (1,0) [0|0] "" Vector__XXX
 SG_ EPBL_a262_userConfirmedChargeCableNotAttached m262 : 21|1@1+ (1,0) [0|0] "" Vector__XXX
 SG_ EPBL_a264_inputVoltageTooLow m264 : 21|1@1+ (1,0) [0|0] "" Vector__XXX
 SG_ EPBL_a021_Task100msLate m21 : 22|1@1+ (1,0) [0|0] "" Vector__XXX
 SG_ EPBL_a086_VEH_systemStatus m86 : 22|1@1+ (1,0) [0|0] "" Vector__XXX
 SG_ EPBL_a087_PARTY_temperature m87 : 22|1@1+ (1,0) [0|0] "" Vector__XXX
 SG_ EPBL_a088_PARTY_temperature m88 : 22|1@1+ (1,0) [0|0] "" Vector__XXX
 SG_ EPBL_a089_CH_party1 m89 : 22|1@1+ (1,0) [0|0] "" Vector__XXX
 SG_ EPBL_a098_PARTY_status m98 : 22|1@1+ (1,0) [0|0] "" Vector__XXX
 SG_ EPBL_a104_BDY_bodyControls3 m104 : 22|1@1+ (1,0) [0|0] "" Vector__XXX
 SG_ EPBL_a107_PT_ptNm m107 : 22|1@1+ (1,0) [0|0] "" Vector__XXX
 SG_ EPBL_a108_PARTY_status m108 : 22|1@1+ (1,0) [0|0] "" Vector__XXX
 SG_ EPBL_a109_PARTY_inertial1 m109 : 22|1@1+ (1,0) [0|0] "" Vector__XXX
 SG_ EPBL_a110_VEH_mismatchFault m110 : 22|1@1+ (1,0) [0|0] "" Vector__XXX
 SG_ EPBL_a111_RIPC_remoteADC m111 : 22|1@1+ (1,0) [0|0] "" Vector__XXX
 SG_ EPBL_a112_LIPC_remoteADC m112 : 22|1@1+ (1,0) [0|0] "" Vector__XXX
 SG_ EPBL_a113_VEH_corianderVehicleControl m113 : 22|1@1+ (1,0) [0|0] "" Vector__XXX
 SG_ EPBL_a114_VEH_status m114 : 22|1@1+ (1,0) [0|0] "" Vector__XXX
 SG_ EPBL_a115_UI_corianderVehicleControl m115 : 22|1@1+ (1,0) [0|0] "" Vector__XXX
 SG_ EPBL_a116_VEH_hvacStatus m116 : 22|1@1+ (1,0) [0|0] "" Vector__XXX
 SG_ EPBL_a117_VEH_vehNm m117 : 22|1@1+ (1,0) [0|0] "" Vector__XXX
 SG_ EPBL_a118_VEH_coolant m118 : 22|1@1+ (1,0) [0|0] "" Vector__XXX
 SG_ EPBL_a120_PARTY_locStatus m120 : 22|1@1+ (1,0) [0|0] "" Vector__XXX
 SG_ EPBL_a243_vehicleSpeed m243 : 22|1@1+ (1,0) [0|0] "" Vector__XXX
 SG_ EPBL_a262_brakeNotConfirmedPressed m262 : 22|1@1+ (1,0) [0|0] "" Vector__XXX
 SG_ EPBL_a264_chargeCablePotentiallyAttached m264 : 22|1@1+ (1,0) [0|0] "" Vector__XXX
 SG_ EPBL_a021_Task100msStarved m21 : 23|1@1+ (1,0) [0|0] "" Vector__XXX
 SG_ EPBL_a086_VEH_thermalStatus m86 : 23|1@1+ (1,0) [0|0] "" Vector__XXX
 SG_ EPBL_a087_PARTY_thermalControl m87 : 23|1@1+ (1,0) [0|0] "" Vector__XXX
 SG_ EPBL_a088_PARTY_thermalControl m88 : 23|1@1+ (1,0) [0|0] "" Vector__XXX
 SG_ EPBL_a089_CH_party3 m89 : 23|1@1+ (1,0) [0|0] "" Vector__XXX
 SG_ EPBL_a098_PARTY_temperature m98 : 23|1@1+ (1,0) [0|0] "" Vector__XXX
 SG_ EPBL_a104_VEH_thermalStatus m104 : 23|1@1+ (1,0) [0|0] "" Vector__XXX
 SG_ EPBL_a107_PT_status m107 : 23|1@1+ (1,0) [0|0] "" Vector__XXX
 SG_ EPBL_a108_PARTY_temperature m108 : 23|1@1+ (1,0) [0|0] "" Vector__XXX
 SG_ EPBL_a109_BDY_imuOffsets m109 : 23|1@1+ (1,0) [0|0] "" Vector__XXX
 SG_ EPBL_a110_VEH_vin m110 : 23|1@1+ (1,0) [0|0] "" Vector__XXX
 SG_ EPBL_a111_RIPC_switchStatus m111 : 23|1@1+ (1,0) [0|0] "" Vector__XXX
 SG_ EPBL_a112_LIPC_switchStatus m112 : 23|1@1+ (1,0) [0|0] "" Vector__XXX
 SG_ EPBL_a113_VEH_solarData m113 : 23|1@1+ (1,0) [0|0] "" Vector__XXX
 SG_ EPBL_a114_PARTY_wheelRotation m114 : 23|1@1+ (1,0) [0|0] "" Vector__XXX
 SG_ EPBL_a115_CH_TPMSDisplay m115 : 23|1@1+ (1,0) [0|0] "" Vector__XXX
 SG_ EPBL_a116_VEH_LVPowerState m116 : 23|1@1+ (1,0) [0|0] "" Vector__XXX
 SG_ EPBL_a117_VEH_hvacBlowerFdb m117 : 23|1@1+ (1,0) [0|0] "" Vector__XXX
 SG_ EPBL_a118_VEH_vehicleStatus m118 : 23|1@1+ (1,0) [0|0] "" Vector__XXX
 SG_ EPBL_a120_PARTY_speed m120 : 23|1@1+ (1,0) [0|0] "" Vector__XXX
 SG_ EPBL_a181_vcTrailerDetected m181 : 23|1@1+ (1,0) [0|0] "" Vector__XXX
 SG_ EPBL_a243_tempAmbient m243 : 23|1@1+ (1,0) [0|0] "" Vector__XXX
 SG_ EPBL_a262_vcfrontMIA m262 : 23|1@1+ (1,0) [0|0] "" Vector__XXX
 SG_ EPBL_a264_userConfirmedChargeCableNotAttached m264 : 23|1@1+ (1,0) [0|0] "" Vector__XXX
 SG_ EPBL_a006_mailboxID m6 : 24|8@1+ (1,0) [0|0] "" Vector__XXX
 SG_ EPBL_a021_Task100msMissed m21 : 24|1@1+ (1,0) [0|0] "" Vector__XXX
 SG_ EPBL_a022_TaskInitError0 m22 : 24|8@1+ (1,0) [0|0] "" Vector__XXX
 SG_ EPBL_a031_uds_bytes_1 m31 : 24|8@1+ (1,0) [0|0] "" Vector__XXX
 SG_ EPBL_a041_CPULoad1msTask m41 : 24|8@1+ (1,0) [0|0] "" Vector__XXX
 SG_ EPBL_a042_Usage10msTask m42 : 24|8@1+ (1,0) [0|0] "" Vector__XXX
 SG_ EPBL_a063_switchType m63 : 24|8@1+ (1,0) [0|0] "" Vector__XXX
 SG_ EPBL_a086_VEH_vehNm m86 : 24|1@1+ (1,0) [0|0] "" Vector__XXX
 SG_ EPBL_a087_VEH_motorStatus m87 : 24|1@1+ (1,0) [0|0] "" Vector__XXX
 SG_ EPBL_a088_VEH_motorStatus m88 : 24|1@1+ (1,0) [0|0] "" Vector__XXX
 SG_ EPBL_a089_VEH_party1 m89 : 24|1@1+ (1,0) [0|0] "" Vector__XXX
 SG_ EPBL_a098_PARTY_thermalControl m98 : 24|1@1+ (1,0) [0|0] "" Vector__XXX
 SG_ EPBL_a104_CH_control m104 : 24|1@1+ (1,0) [0|0] "" Vector__XXX
 SG_ EPBL_a107_PT_thermalStatus m107 : 24|1@1+ (1,0) [0|0] "" Vector__XXX
 SG_ EPBL_a108_PARTY_thermalControl m108 : 24|1@1+ (1,0) [0|0] "" Vector__XXX
 SG_ EPBL_a109_BDY_inertial1 m109 : 24|1@1+ (1,0) [0|0] "" Vector__XXX
 SG_ EPBL_a110_VEH_bmpDebug m110 : 24|1@1+ (1,0) [0|0] "" Vector__XXX
 SG_ EPBL_a111_VEH_LVPowerState m111 : 24|1@1+ (1,0) [0|0] "" Vector__XXX
 SG_ EPBL_a112_VEH_LVPowerState m112 : 24|1@1+ (1,0) [0|0] "" Vector__XXX
 SG_ EPBL_a113_VEH_ventCntlReq m113 : 24|1@1+ (1,0) [0|0] "" Vector__XXX
 SG_ EPBL_a114_CH_wheelRotation m114 : 24|1@1+ (1,0) [0|0] "" Vector__XXX
 SG_ EPBL_a116_VEH_lightStatus m116 : 24|1@1+ (1,0) [0|0] "" Vector__XXX
 SG_ EPBL_a117_VEH_LVPowerState m117 : 24|1@1+ (1,0) [0|0] "" Vector__XXX
 SG_ EPBL_a118_VEH_12VBatteryStatus m118 : 24|1@1+ (1,0) [0|0] "" Vector__XXX
 SG_ EPBL_a120_VEH_speed m120 : 24|1@1+ (1,0) [0|0] "" Vector__XXX
 SG_ EPBL_a141_toState m141 : 24|5@1+ (1,0) [0|0] "" Vector__XXX
 SG_ EPBL_a173_esmStateRequest m173 : 24|5@1+ (1,0) [0|0] "" Vector__XXX
 SG_ EPBL_a174_esmStateRequest m174 : 24|5@1+ (1,0) [0|0] "" Vector__XXX
 SG_ EPBL_a175_esmStateRequest m175 : 24|5@1+ (1,0) [0|0] "" Vector__XXX
 SG_ EPBL_a176_esmStateRequest m176 : 24|5@1+ (1,0) [0|0] "" Vector__XXX
 SG_ EPBL_a177_esmStateRequest m177 : 24|5@1+ (1,0) [0|0] "" Vector__XXX
 SG_ EPBL_a179_esmStateRequest m179 : 24|5@1+ (1,0) [0|0] "" Vector__XXX
 SG_ EPBL_a180_previousState m180 : 24|5@1+ (1,0) [0|0] "" Vector__XXX
 SG_ EPBL_a181_uiTrailerDetected m181 : 24|1@1+ (1,0) [0|0] "" Vector__XXX
 SG_ EPBL_a182_grade m182 : 24|7@1- (1,0) [0|0] "" Vector__XXX
 SG_ EPBL_a183_esmState m183 : 24|5@1+ (1,0) [0|0] "" Vector__XXX
 SG_ EPBL_a184_previousState m184 : 24|5@1+ (1,0) [0|0] "" Vector__XXX
 SG_ EPBL_a186_previousState m186 : 24|5@1+ (1,0) [0|0] "" Vector__XXX
 SG_ EPBL_a187_previousState m187 : 24|5@1+ (1,0) [0|0] "" Vector__XXX
 SG_ EPBL_a188_previousState m188 : 24|5@1+ (1,0) [0|0] "" Vector__XXX
 SG_ EPBL_a189_previousState m189 : 24|5@1+ (1,0) [0|0] "" Vector__XXX
 SG_ EPBL_a190_esmStateRequest m190 : 24|5@1+ (1,0) [0|0] "" Vector__XXX
 SG_ EPBL_a191_esmStateRequest m191 : 24|5@1+ (1,0) [0|0] "" Vector__XXX
 SG_ EPBL_a210_localDriverIsLeaving m210 : 24|1@1+ (1,0) [0|0] "" Vector__XXX
 SG_ EPBL_a216_byte0 m216 : 24|8@1+ (1,0) [0|0] "" Vector__XXX
 SG_ EPBL_a217_byte5 m217 : 24|8@1+ (1,0) [0|0] "" Vector__XXX
 SG_ EPBL_a225_previousState m225 : 24|5@1+ (1,0) [0|0] "" Vector__XXX
 SG_ EPBL_a241_vehiclePowerState m241 : 24|2@1+ (1,0) [0|0] "" Vector__XXX
 SG_ EPBL_a242_vehiclePowerState m242 : 24|2@1+ (1,0) [0|0] "" Vector__XXX
 SG_ EPBL_a243_thermistorTMin m243 : 24|1@1+ (1,0) [0|0] "" Vector__XXX
 SG_ EPBL_a246_nextState m246 : 24|5@1+ (1,0) [0|0] "" Vector__XXX
 SG_ EPBL_a247_esmStateRequest m247 : 24|5@1+ (1,0) [0|0] "" Vector__XXX
 SG_ EPBL_a248_esmStateRequest m248 : 24|5@1+ (1,0) [0|0] "" Vector__XXX
 SG_ EPBL_a249_nextState m249 : 24|5@1+ (1,0) [0|0] "" Vector__XXX
 SG_ EPBL_a250_esmOperationTrigger m250 : 24|6@1+ (1,0) [0|0] "" Vector__XXX
 SG_ EPBL_a253_esmStateRequest m253 : 24|5@1+ (1,0) [0|0] "" Vector__XXX
 SG_ EPBL_a256_esmStateRequest m256 : 24|5@1+ (1,0) [0|0] "" Vector__XXX
 SG_ EPBL_a262_showroomModeActive m262 : 24|1@1+ (1,0) [0|0] "" Vector__XXX
 SG_ EPBL_a263_esmStateRequest m263 : 24|5@1+ (1,0) [0|0] "" Vector__XXX
 SG_ EPBL_a264_chargeCableDefinitelyAttached m264 : 24|1@1+ (1,0) [0|0] "" Vector__XXX
 SG_ EPBL_a300_subUsageId m300 : 24|8@1+ (1,0) [0|0] "" Vector__XXX
 SG_ EPBL_a357_grade m357 : 24|7@1- (1,0) [0|0] "" Vector__XXX
 SG_ EPBL_a358_grade m358 : 24|7@1- (1,0) [0|0] "" Vector__XXX
 SG_ EPBL_a365_grade m365 : 24|7@1- (1,0) [0|0] "" Vector__XXX
 SG_ EPBL_a366_grade m366 : 24|7@1- (1,0) [0|0] "" Vector__XXX
 SG_ EPBL_a021_Task1000msLate m21 : 25|1@1+ (1,0) [0|0] "" Vector__XXX
 SG_ EPBL_a089_VEH_party3 m89 : 25|1@1+ (1,0) [0|0] "" Vector__XXX
 SG_ EPBL_a098_PARTY_torque m98 : 25|1@1+ (1,0) [0|0] "" Vector__XXX
 SG_ EPBL_a104_PARTY_control m104 : 25|1@1+ (1,0) [0|0] "" Vector__XXX
 SG_ EPBL_a107_PT_socStatus m107 : 25|1@1+ (1,0) [0|0] "" Vector__XXX
 SG_ EPBL_a108_PT_temperature m108 : 25|1@1+ (1,0) [0|0] "" Vector__XXX
 SG_ EPBL_a109_BDY_inertial2 m109 : 25|1@1+ (1,0) [0|0] "" Vector__XXX
 SG_ EPBL_a110_VEH_gearControl m110 : 25|1@1+ (1,0) [0|0] "" Vector__XXX
 SG_ EPBL_a111_VEH_seatStatus m111 : 25|1@1+ (1,0) [0|0] "" Vector__XXX
 SG_ EPBL_a112_PARTY_status m112 : 25|1@1+ (1,0) [0|0] "" Vector__XXX
 SG_ EPBL_a113_VEH_chassisControl m113 : 25|1@1+ (1,0) [0|0] "" Vector__XXX
 SG_ EPBL_a114_VEH_wheelRotation m114 : 25|1@1+ (1,0) [0|0] "" Vector__XXX
 SG_ EPBL_a116_VEH_seatStatus m116 : 25|1@1+ (1,0) [0|0] "" Vector__XXX
 SG_ EPBL_a117_VEH_restraintStatus m117 : 25|1@1+ (1,0) [0|0] "" Vector__XXX
 SG_ EPBL_a118_VEH_systemStatus m118 : 25|1@1+ (1,0) [0|0] "" Vector__XXX
 SG_ EPBL_a120_PARTY_status m120 : 25|1@1+ (1,0) [0|0] "" Vector__XXX
 SG_ EPBL_a181_trailerDetected m181 : 25|1@1+ (1,0) [0|0] "" Vector__XXX
 SG_ EPBL_a198_currentAvg m198 : 25|12@1+ (0.01,0) [0|0] "" Vector__XXX
 SG_ EPBL_a210_localDriverIsLeavingAnySpeed m210 : 25|1@1+ (1,0) [0|0] "" Vector__XXX
 SG_ EPBL_a243_wiperSpeed m243 : 25|1@1+ (1,0) [0|0] "" Vector__XXX
 SG_ EPBL_a262_lvBatteryBlocking m262 : 25|1@1+ (1,0) [0|0] "" Vector__XXX
 SG_ EPBL_a264_lvBatteryBlocking m264 : 25|1@1+ (1,0) [0|0] "" Vector__XXX
 SG_ EPBL_a021_Task1000msStarved m21 : 26|1@1+ (1,0) [0|0] "" Vector__XXX
 SG_ EPBL_a098_PT_thermalControl m98 : 26|1@1+ (1,0) [0|0] "" Vector__XXX
 SG_ EPBL_a104_PARTY_bodyControls m104 : 26|1@1+ (1,0) [0|0] "" Vector__XXX
 SG_ EPBL_a107_VEH_socStatus m107 : 26|1@1+ (1,0) [0|0] "" Vector__XXX
 SG_ EPBL_a108_PT_thermalControl m108 : 26|1@1+ (1,0) [0|0] "" Vector__XXX
 SG_ EPBL_a109_BDY_status m109 : 26|1@1+ (1,0) [0|0] "" Vector__XXX
 SG_ EPBL_a110_VEH_canLogAvailability m110 : 26|1@1+ (1,0) [0|0] "" Vector__XXX
 SG_ EPBL_a111_PARTY_status m111 : 26|1@1+ (1,0) [0|0] "" Vector__XXX
 SG_ EPBL_a112_CH_status m112 : 26|1@1+ (1,0) [0|0] "" Vector__XXX
 SG_ EPBL_a113_VEH_trackModeSettings m113 : 26|1@1+ (1,0) [0|0] "" Vector__XXX
 SG_ EPBL_a114_PARTY_brakeTorque m114 : 26|1@1+ (1,0) [0|0] "" Vector__XXX
 SG_ EPBL_a116_VEH_thsStatus m116 : 26|1@1+ (1,0) [0|0] "" Vector__XXX
 SG_ EPBL_a117_VEH_lightStatus m117 : 26|1@1+ (1,0) [0|0] "" Vector__XXX
 SG_ EPBL_a118_PARTY_LVPowerState m118 : 26|1@1+ (1,0) [0|0] "" Vector__XXX
 SG_ EPBL_a120_PT_speed m120 : 26|1@1+ (1,0) [0|0] "" Vector__XXX
 SG_ EPBL_a210_remoteDriverIsLeaving m210 : 26|1@1+ (1,0) [0|0] "" Vector__XXX
 SG_ EPBL_a241_highCurrent m241 : 26|1@1+ (1,0) [0|0] "" Vector__XXX
 SG_ EPBL_a242_highCurrent m242 : 26|1@1+ (1,0) [0|0] "" Vector__XXX
 SG_ EPBL_a243_vehiclePowerState m243 : 26|1@1+ (1,0) [0|0] "" Vector__XXX
 SG_ EPBL_a262_chargeCableStateUnknown m262 : 26|1@1+ (1,0) [0|0] "" Vector__XXX
 SG_ EPBL_a264_vehicleSpeedTooFast m264 : 26|1@1+ (1,0) [0|0] "" Vector__XXX
 SG_ EPBL_a352_maxCurrent m352 : 26|8@1+ (0.1,0) [0|0] "" Vector__XXX
 SG_ EPBL_a021_Task1000msMissed m21 : 27|1@1+ (1,0) [0|0] "" Vector__XXX
 SG_ EPBL_a098_PT_temperature m98 : 27|1@1+ (1,0) [0|0] "" Vector__XXX
 SG_ EPBL_a104_PARTY_gpsAccuracies m104 : 27|1@1+ (1,0) [0|0] "" Vector__XXX
 SG_ EPBL_a107_VEH_packConfig m107 : 27|1@1+ (1,0) [0|0] "" Vector__XXX
 SG_ EPBL_a108_PARTY_motorStatus m108 : 27|1@1+ (1,0) [0|0] "" Vector__XXX
 SG_ EPBL_a109_VEH_inertial1 m109 : 27|1@1+ (1,0) [0|0] "" Vector__XXX
 SG_ EPBL_a110_CH_airbagCutoffStatus m110 : 27|1@1+ (1,0) [0|0] "" Vector__XXX
 SG_ EPBL_a111_CH_status m111 : 27|1@1+ (1,0) [0|0] "" Vector__XXX
 SG_ EPBL_a113_VEH_powertrainControl m113 : 27|1@1+ (1,0) [0|0] "" Vector__XXX
 SG_ EPBL_a114_PARTY_offsets m114 : 27|1@1+ (1,0) [0|0] "" Vector__XXX
 SG_ EPBL_a116_VEH_doorStatus m116 : 27|1@1+ (1,0) [0|0] "" Vector__XXX
 SG_ EPBL_a117_VEH_seatStatus m117 : 27|1@1+ (1,0) [0|0] "" Vector__XXX
 SG_ EPBL_a118_PARTY_outputPowerStatus m118 : 27|1@1+ (1,0) [0|0] "" Vector__XXX
 SG_ EPBL_a120_PT_systemStatus m120 : 27|1@1+ (1,0) [0|0] "" Vector__XXX
 SG_ EPBL_a210_remoteDriverIsLeavingAnySpeed m210 : 27|1@1+ (1,0) [0|0] "" Vector__XXX
 SG_ EPBL_a241_monitorDataGood m241 : 27|1@1+ (1,0) [0|0] "" Vector__XXX
 SG_ EPBL_a242_monitorDataGood m242 : 27|1@1+ (1,0) [0|0] "" Vector__XXX
 SG_ EPBL_a243_brakeDiscWipingActive m243 : 27|1@1+ (1,0) [0|0] "" Vector__XXX
 SG_ EPBL_a262_lvBatteryCanSupportVehicle m262 : 27|1@1+ (1,0) [0|0] "" Vector__XXX
 SG_ EPBL_a264_vehicleSpeedUnknown m264 : 27|1@1+ (1,0) [0|0] "" Vector__XXX
 SG_ EPBL_a058_current m58 : 28|11@1+ (0.1,0) [0|0] "" Vector__XXX
 SG_ EPBL_a059_resistanceEstimate m59 : 28|12@1+ (0.00244,0) [0|0] "" Vector__XXX
 SG_ EPBL_a098_PARTY_motorStatus m98 : 28|1@1+ (1,0) [0|0] "" Vector__XXX
 SG_ EPBL_a104_CH_status m104 : 28|1@1+ (1,0) [0|0] "" Vector__XXX
 SG_ EPBL_a107_VEH_energyStatus m107 : 28|1@1+ (1,0) [0|0] "" Vector__XXX
 SG_ EPBL_a108_VEH_motorStatus m108 : 28|1@1+ (1,0) [0|0] "" Vector__XXX
 SG_ EPBL_a109_VEH_inertial2 m109 : 28|1@1+ (1,0) [0|0] "" Vector__XXX
 SG_ EPBL_a110_CH_carConfig m110 : 28|1@1+ (1,0) [0|0] "" Vector__XXX
 SG_ EPBL_a113_VEH_vehicleModes m113 : 28|1@1+ (1,0) [0|0] "" Vector__XXX
 SG_ EPBL_a114_BDY_offsets m114 : 28|1@1+ (1,0) [0|0] "" Vector__XXX
 SG_ EPBL_a116_VEH_seatHeatStatus m116 : 28|1@1+ (1,0) [0|0] "" Vector__XXX
 SG_ EPBL_a117_BDY_falconSwitchStatus m117 : 28|1@1+ (1,0) [0|0] "" Vector__XXX
 SG_ EPBL_a118_PARTY_vehicleTime m118 : 28|1@1+ (1,0) [0|0] "" Vector__XXX
 SG_ EPBL_a120_PARTY_vehicleEstimates m120 : 28|1@1+ (1,0) [0|0] "" Vector__XXX
 SG_ EPBL_a125_nvFilt m125 : 28|12@1+ (0.005443676098,0) [0|0] "" Vector__XXX
 SG_ EPBL_a126_nvFilt m126 : 28|12@1+ (0.005443676098,0) [0|0] "" Vector__XXX
 SG_ EPBL_a127_nvFilt m127 : 28|12@1+ (0.005443676098,0) [0|0] "" Vector__XXX
 SG_ EPBL_a128_nvFilt m128 : 28|12@1+ (0.005443676098,0) [0|0] "" Vector__XXX
 SG_ EPBL_a134_nvFilt m134 : 28|12@1+ (0.005443676098,0) [0|0] "" Vector__XXX
 SG_ EPBL_a135_nvFilt m135 : 28|12@1+ (0.005443676098,0) [0|0] "" Vector__XXX
 SG_ EPBL_a136_nvFilt m136 : 28|12@1+ (0.005443676098,0) [0|0] "" Vector__XXX
 SG_ EPBL_a137_nvFilt m137 : 28|12@1+ (0.005443676098,0) [0|0] "" Vector__XXX
 SG_ EPBL_a170_nvFilt m170 : 28|12@1+ (0.005443676098,0) [0|0] "" Vector__XXX
 SG_ EPBL_a171_nvFilt m171 : 28|12@1+ (0.005443676098,0) [0|0] "" Vector__XXX
 SG_ EPBL_a210_primaryDriverDoorClosed m210 : 28|2@1+ (1,0) [0|0] "" Vector__XXX
 SG_ EPBL_a241_hasLockoutRequest m241 : 28|1@1+ (1,0) [0|0] "" Vector__XXX
 SG_ EPBL_a242_hasLockoutRequest m242 : 28|1@1+ (1,0) [0|0] "" Vector__XXX
 SG_ EPBL_a262_ignoreLvBatteryCanSupportVehicle m262 : 28|1@1+ (1,0) [0|0] "" Vector__XXX
 SG_ EPBL_a264_jumpPostConfirmedTripped m264 : 28|1@1+ (1,0) [0|0] "" Vector__XXX
 SG_ EPBL_a362_outputRodDriver m362 : 28|10@1+ (0.1,-10) [0|0] "" Vector__XXX
 SG_ EPBL_a363_outputRodDriver m363 : 28|10@1+ (0.1,-10) [0|0] "" Vector__XXX
 SG_ EPBL_a098_VEH_motorStatus m98 : 29|1@1+ (1,0) [0|0] "" Vector__XXX
 SG_ EPBL_a104_PARTY_status m104 : 29|1@1+ (1,0) [0|0] "" Vector__XXX
 SG_ EPBL_a107_VEH_chargeInfo m107 : 29|1@1+ (1,0) [0|0] "" Vector__XXX
 SG_ EPBL_a108_CH_torque m108 : 29|1@1+ (1,0) [0|0] "" Vector__XXX
 SG_ EPBL_a109_CH_inertial1 m109 : 29|1@1+ (1,0) [0|0] "" Vector__XXX
 SG_ EPBL_a110_CH_carState m110 : 29|1@1+ (1,0) [0|0] "" Vector__XXX
 SG_ EPBL_a113_VEH_driverProfileRecall m113 : 29|1@1+ (1,0) [0|0] "" Vector__XXX
 SG_ EPBL_a114_BDY_party3 m114 : 29|1@1+ (1,0) [0|0] "" Vector__XXX
 SG_ EPBL_a116_VEH_restraintStatus m116 : 29|1@1+ (1,0) [0|0] "" Vector__XXX
 SG_ EPBL_a117_VEH_doorStatus m117 : 29|1@1+ (1,0) [0|0] "" Vector__XXX
 SG_ EPBL_a118_VEH_thermalCommand m118 : 29|1@1+ (1,0) [0|0] "" Vector__XXX
 SG_ EPBL_a120_VEH_aggregatedAxleSpeed m120 : 29|1@1+ (1,0) [0|0] "" Vector__XXX
 SG_ EPBL_a174_faultStatus m174 : 29|2@1+ (1,0) [0|0] "" Vector__XXX
 SG_ EPBL_a175_faultStatus m175 : 29|2@1+ (1,0) [0|0] "" Vector__XXX
 SG_ EPBL_a176_faultStatus m176 : 29|2@1+ (1,0) [0|0] "" Vector__XXX
 SG_ EPBL_a177_faultStatus m177 : 29|2@1+ (1,0) [0|0] "" Vector__XXX
 SG_ EPBL_a179_faultStatus m179 : 29|2@1+ (1,0) [0|0] "" Vector__XXX
 SG_ EPBL_a190_faultStatus m190 : 29|2@1+ (1,0) [0|0] "" Vector__XXX
 SG_ EPBL_a191_faultStatus m191 : 29|2@1+ (1,0) [0|0] "" Vector__XXX
 SG_ EPBL_a247_faultStatus m247 : 29|2@1+ (1,0) [0|0] "" Vector__XXX
 SG_ EPBL_a248_faultStatus m248 : 29|2@1+ (1,0) [0|0] "" Vector__XXX
 SG_ EPBL_a253_lvStatusReadyforDrive m253 : 29|2@1+ (1,0) [0|0] "" Vector__XXX
 SG_ EPBL_a256_lvStatusReadyforDrive m256 : 29|2@1+ (1,0) [0|0] "" Vector__XXX
 SG_ EPBL_a262_uiServiceMode m262 : 29|1@1+ (1,0) [0|0] "" Vector__XXX
 SG_ EPBL_a263_esmSpeedClass m263 : 29|3@1+ (1,0) [0|0] "" Vector__XXX
 SG_ EPBL_a264_vehiclePowerStateDrive m264 : 29|1@1+ (1,0) [0|0] "" Vector__XXX
 SG_ EPBL_a104_PARTY_steeringControl m104 : 30|1@1+ (1,0) [0|0] "" Vector__XXX
 SG_ EPBL_a109_CH_inertial2 m109 : 30|1@1+ (1,0) [0|0] "" Vector__XXX
 SG_ EPBL_a110_CH_vin m110 : 30|1@1+ (1,0) [0|0] "" Vector__XXX
 SG_ EPBL_a113_VEH_driverProfileRecall2 m113 : 30|1@1+ (1,0) [0|0] "" Vector__XXX
 SG_ EPBL_a114_BDY_status m114 : 30|1@1+ (1,0) [0|0] "" Vector__XXX
 SG_ EPBL_a116_VEH_switchStatus m116 : 30|1@1+ (1,0) [0|0] "" Vector__XXX
 SG_ EPBL_a117_VEH_doorStatus2 m117 : 30|1@1+ (1,0) [0|0] "" Vector__XXX
 SG_ EPBL_a118_CH_LVPowerState m118 : 30|1@1+ (1,0) [0|0] "" Vector__XXX
 SG_ EPBL_a120_PARTY_aggregatedAxleSpeed m120 : 30|1@1+ (1,0) [0|0] "" Vector__XXX
 SG_ EPBL_a210_secondaryDriverDoorClosed m210 : 30|2@1+ (1,0) [0|0] "" Vector__XXX
 SG_ EPBL_a250_isJumpPostTripped m250 : 30|1@1+ (1,0) [0|0] "" Vector__XXX
 SG_ EPBL_a262_uiServiceModePlus m262 : 30|1@1+ (1,0) [0|0] "" Vector__XXX
 SG_ EPBL_a264_diDriveMode m264 : 30|1@1+ (1,0) [0|0] "" Vector__XXX
 SG_ EPBL_a104_CH_steeringControl m104 : 31|1@1+ (1,0) [0|0] "" Vector__XXX
 SG_ EPBL_a109_CH_status m109 : 31|1@1+ (1,0) [0|0] "" Vector__XXX
 SG_ EPBL_a110_CH_chNm m110 : 31|1@1+ (1,0) [0|0] "" Vector__XXX
 SG_ EPBL_a113_VEH_ventCntlReg m113 : 31|1@1+ (1,0) [0|0] "" Vector__XXX
 SG_ EPBL_a114_BDY_wheelRotation m114 : 31|1@1+ (1,0) [0|0] "" Vector__XXX
 SG_ EPBL_a116_VEH_logging1Hz m116 : 31|1@1+ (1,0) [0|0] "" Vector__XXX
 SG_ EPBL_a117_VEH_windowStatus m117 : 31|1@1+ (1,0) [0|0] "" Vector__XXX
 SG_ EPBL_a118_PARTY_sensors m118 : 31|1@1+ (1,0) [0|0] "" Vector__XXX
 SG_ EPBL_a120_VEH_systemPower m120 : 31|1@1+ (1,0) [0|0] "" Vector__XXX
 SG_ EPBL_a253_passiveApplyRequested m253 : 31|1@1+ (1,0) [0|0] "" Vector__XXX
 SG_ EPBL_a256_vehiclePowerState m256 : 31|1@1+ (1,0) [0|0] "" Vector__XXX
 SG_ EPBL_a262_hvUp m262 : 31|1@1+ (1,0) [0|0] "" Vector__XXX
 SG_ EPBL_a264_chargeCableStateUnknown m264 : 31|1@1+ (1,0) [0|0] "" Vector__XXX
 SG_ EPBL_a000_alertDataW1 m0 : 32|16@1+ (1,0) [0|0] "" Vector__XXX
 SG_ EPBL_a003_LineNumber m3 : 32|16@1+ (1,0) [0|0] "" Vector__XXX
 SG_ EPBL_a005_busID1 m5 : 32|4@1+ (1,0) [0|0] "" Vector__XXX
 SG_ EPBL_a006_messageID m6 : 32|29@1+ (1,0) [0|0] "" Vector__XXX
 SG_ EPBL_a016_NVMMRecordNotFound m16 : 32|1@1+ (1,0) [0|0] "" Vector__XXX
 SG_ EPBL_a022_TaskInitError1 m22 : 32|8@1+ (1,0) [0|0] "" Vector__XXX
 SG_ EPBL_a031_uds_bytes_2 m31 : 32|8@1+ (1,0) [0|0] "" Vector__XXX
 SG_ EPBL_a041_CPULoad10msTask m41 : 32|8@1+ (1,0) [0|0] "" Vector__XXX
 SG_ EPBL_a042_Usage100msTask m42 : 32|8@1+ (1,0) [0|0] "" Vector__XXX
 SG_ EPBL_a063_ADCVoltage m63 : 32|8@1+ (0.025,0) [0|0] "" Vector__XXX
 SG_ EPBL_a104_VEH_steeringControl m104 : 32|1@1+ (1,0) [0|0] "" Vector__XXX
 SG_ EPBL_a110_CH_epochTimeGtw m110 : 32|1@1+ (1,0) [0|0] "" Vector__XXX
 SG_ EPBL_a113_VEH_debugECU m113 : 32|1@1+ (1,0) [0|0] "" Vector__XXX
 SG_ EPBL_a114_BDY_wheelSpeeds m114 : 32|1@1+ (1,0) [0|0] "" Vector__XXX
 SG_ EPBL_a116_VEH_seatStatus2 m116 : 32|1@1+ (1,0) [0|0] "" Vector__XXX
 SG_ EPBL_a117_VEH_switchStatus m117 : 32|1@1+ (1,0) [0|0] "" Vector__XXX
 SG_ EPBL_a118_CH_sensors m118 : 32|1@1+ (1,0) [0|0] "" Vector__XXX
 SG_ EPBL_a120_PARTY_autonomyHealth m120 : 32|1@1+ (1,0) [0|0] "" Vector__XXX
 SG_ EPBL_a173_csmState m173 : 32|4@1+ (1,0) [0|0] "" Vector__XXX
 SG_ EPBL_a174_monitorUnitStatus m174 : 32|5@1+ (1,0) [0|0] "" Vector__XXX
 SG_ EPBL_a175_monitorUnitStatus m175 : 32|5@1+ (1,0) [0|0] "" Vector__XXX
 SG_ EPBL_a176_monitorUnitStatus m176 : 32|5@1+ (1,0) [0|0] "" Vector__XXX
 SG_ EPBL_a177_monitorUnitStatus m177 : 32|5@1+ (1,0) [0|0] "" Vector__XXX
 SG_ EPBL_a179_monitorUnitStatus m179 : 32|5@1+ (1,0) [0|0] "" Vector__XXX
 SG_ EPBL_a180_nextState m180 : 32|5@1+ (1,0) [0|0] "" Vector__XXX
 SG_ EPBL_a182_temperature m182 : 32|8@1+ (0.5,-40) [0|0] "" Vector__XXX
 SG_ EPBL_a183_esmStateRequest m183 : 32|5@1+ (1,0) [0|0] "" Vector__XXX
 SG_ EPBL_a184_nextState m184 : 32|5@1+ (1,0) [0|0] "" Vector__XXX
 SG_ EPBL_a186_nextState m186 : 32|5@1+ (1,0) [0|0] "" Vector__XXX
 SG_ EPBL_a187_nextState m187 : 32|5@1+ (1,0) [0|0] "" Vector__XXX
 SG_ EPBL_a188_nextState m188 : 32|5@1+ (1,0) [0|0] "" Vector__XXX
 SG_ EPBL_a189_nextState m189 : 32|5@1+ (1,0) [0|0] "" Vector__XXX
 SG_ EPBL_a190_monitorUnitStatus m190 : 32|5@1+ (1,0) [0|0] "" Vector__XXX
 SG_ EPBL_a191_monitorUnitStatus m191 : 32|5@1+ (1,0) [0|0] "" Vector__XXX
 SG_ EPBL_a210_driverBuckled m210 : 32|2@1+ (1,0) [0|0] "" Vector__XXX
 SG_ EPBL_a216_byte1 m216 : 32|8@1+ (1,0) [0|0] "" Vector__XXX
 SG_ EPBL_a217_byte6 m217 : 32|8@1+ (1,0) [0|0] "" Vector__XXX
 SG_ EPBL_a225_nextState m225 : 32|5@1+ (1,0) [0|0] "" Vector__XXX
 SG_ EPBL_a246_esmStateRequest m246 : 32|5@1+ (1,0) [0|0] "" Vector__XXX
 SG_ EPBL_a247_monitorUnitStatus m247 : 32|5@1+ (1,0) [0|0] "" Vector__XXX
 SG_ EPBL_a248_monitorUnitStatus m248 : 32|5@1+ (1,0) [0|0] "" Vector__XXX
 SG_ EPBL_a249_esmStateRequest m249 : 32|5@1+ (1,0) [0|0] "" Vector__XXX
 SG_ EPBL_a251_pistonPosition m251 : 32|13@1- (9.768009768009769,0) [0|0] "" Vector__XXX
 SG_ EPBL_a253_diStandStillApply m253 : 32|1@1+ (1,0) [0|0] "" Vector__XXX
 SG_ EPBL_a256_passiveApplyRequested m256 : 32|1@1+ (1,0) [0|0] "" Vector__XXX
 SG_ EPBL_a262_wasHVUpSinceLastWake m262 : 32|1@1+ (1,0) [0|0] "" Vector__XXX
 SG_ EPBL_a263_isPowerStateParkRequested m263 : 32|1@1+ (1,0) [0|0] "" Vector__XXX
 SG_ EPBL_a264_lvBatteryCanSupportVehicle m264 : 32|1@1+ (1,0) [0|0] "" Vector__XXX
 SG_ EPBL_a301_oocConfidence m301 : 32|12@1+ (1,0) [0|0] "" Vector__XXX
 SG_ EPBL_a302_deltaCurrent m302 : 32|15@1+ (0.01,0) [0|0] "" Vector__XXX
 SG_ EPBL_a303_pistonPosition m303 : 32|13@1- (9.768009768009769,0) [0|0] "" Vector__XXX
 SG_ EPBL_a350_ensDuty m350 : 32|10@1+ (0.00098,0) [0|0] "" Vector__XXX
 SG_ EPBL_a357_ambientTemp m357 : 32|8@1+ (0.5,-40) [0|0] "" Vector__XXX
 SG_ EPBL_a358_ambientTemp m358 : 32|8@1+ (0.5,-40) [0|0] "" Vector__XXX
 SG_ EPBL_a365_ambientTemp m365 : 32|8@1+ (0.5,-40) [0|0] "" Vector__XXX
 SG_ EPBL_a366_ambientTemp m366 : 32|8@1+ (0.5,-40) [0|0] "" Vector__XXX
 SG_ EPBL_a370_count m370 : 32|16@1+ (1,0) [0|0] "" Vector__XXX
 SG_ EPBL_a016_NVMMCRCMismatch m16 : 33|1@1+ (1,0) [0|0] "" Vector__XXX
 SG_ EPBL_a104_PARTY_integratedSafetyFront m104 : 33|1@1+ (1,0) [0|0] "" Vector__XXX
 SG_ EPBL_a110_PARTY_carConfig m110 : 33|1@1+ (1,0) [0|0] "" Vector__XXX
 SG_ EPBL_a113_VEH_status m113 : 33|1@1+ (1,0) [0|0] "" Vector__XXX
 SG_ EPBL_a114_CH_party1 m114 : 33|1@1+ (1,0) [0|0] "" Vector__XXX
 SG_ EPBL_a116_VEH_status m116 : 33|1@1+ (1,0) [0|0] "" Vector__XXX
 SG_ EPBL_a117_VEH_intrusionSensorStatus m117 : 33|1@1+ (1,0) [0|0] "" Vector__XXX
 SG_ EPBL_a118_VEH_interNodeResistance m118 : 33|1@1+ (1,0) [0|0] "" Vector__XXX
 SG_ EPBL_a120_VEH_autonomyHealth m120 : 33|1@1+ (1,0) [0|0] "" Vector__XXX
 SG_ EPBL_a253_isDriverLeaving m253 : 33|1@1+ (1,0) [0|0] "" Vector__XXX
 SG_ EPBL_a256_diStandStillApply m256 : 33|1@1+ (1,0) [0|0] "" Vector__XXX
 SG_ EPBL_a262_hvDownForMoreThanTwoMinutes m262 : 33|1@1+ (1,0) [0|0] "" Vector__XXX
 SG_ EPBL_a263_isJumpPostTripped m263 : 33|1@1+ (1,0) [0|0] "" Vector__XXX
 SG_ EPBL_a264_ignoreLvBatteryCanSupportVehicle m264 : 33|1@1+ (1,0) [0|0] "" Vector__XXX
 SG_ EPBL_a016_NVMMVersionMismatch m16 : 34|1@1+ (1,0) [0|0] "" Vector__XXX
 SG_ EPBL_a104_PARTY_matrixBendAngleRequest m104 : 34|1@1+ (1,0) [0|0] "" Vector__XXX
 SG_ EPBL_a113_VEH_elevationStatus m113 : 34|1@1+ (1,0) [0|0] "" Vector__XXX
 SG_ EPBL_a114_CH_party3 m114 : 34|1@1+ (1,0) [0|0] "" Vector__XXX
 SG_ EPBL_a116_VEH_thermalCommand m116 : 34|1@1+ (1,0) [0|0] "" Vector__XXX
 SG_ EPBL_a117_VEH_liftgateStatus m117 : 34|1@1+ (1,0) [0|0] "" Vector__XXX
 SG_ EPBL_a118_CH_lighting m118 : 34|1@1+ (1,0) [0|0] "" Vector__XXX
 SG_ EPBL_a120_PT_systemPower m120 : 34|1@1+ (1,0) [0|0] "" Vector__XXX
 SG_ EPBL_a210_driverSeated m210 : 34|2@1+ (1,0) [0|0] "" Vector__XXX
 SG_ EPBL_a253_driverParkRequest m253 : 34|1@1+ (1,0) [0|0] "" Vector__XXX
 SG_ EPBL_a256_activeDecelRequest m256 : 34|1@1+ (1,0) [0|0] "" Vector__XXX
 SG_ EPBL_a262_dirLVOn m262 : 34|1@1+ (1,0) [0|0] "" Vector__XXX
 SG_ EPBL_a264_hvDownForMoreThanTwoMinutes m264 : 34|1@1+ (1,0) [0|0] "" Vector__XXX
 SG_ EPBL_a352_prevFilteredCurrent m352 : 34|8@1+ (0.1,0) [0|0] "" Vector__XXX
 SG_ EPBL_a016_NVMMRecordUpgraded m16 : 35|1@1+ (1,0) [0|0] "" Vector__XXX
 SG_ EPBL_a104_VEH_matrixHighBeamRequest m104 : 35|1@1+ (1,0) [0|0] "" Vector__XXX
 SG_ EPBL_a113_VEH_LVControl m113 : 35|1@1+ (1,0) [0|0] "" Vector__XXX
 SG_ EPBL_a114_CH_status m114 : 35|1@1+ (1,0) [0|0] "" Vector__XXX
 SG_ EPBL_a116_VEH_windowStatus m116 : 35|1@1+ (1,0) [0|0] "" Vector__XXX
 SG_ EPBL_a117_VEH_seatStatus2 m117 : 35|1@1+ (1,0) [0|0] "" Vector__XXX
 SG_ EPBL_a118_VEH_lightStatus m118 : 35|1@1+ (1,0) [0|0] "" Vector__XXX
 SG_ EPBL_a120_PARTY_stalklessInterfaces m120 : 35|1@1+ (1,0) [0|0] "" Vector__XXX
 SG_ EPBL_a253_driverDynamicRequest m253 : 35|1@1+ (1,0) [0|0] "" Vector__XXX
 SG_ EPBL_a256_lvDriveStatusBlock m256 : 35|1@1+ (1,0) [0|0] "" Vector__XXX
 SG_ EPBL_a264_uiServiceMode m264 : 35|1@1+ (1,0) [0|0] "" Vector__XXX
 SG_ EPBL_a005_faults1 m5 : 36|12@1+ (1,0) [0|0] "" Vector__XXX
 SG_ EPBL_a016_NVMMMemOverflow m16 : 36|1@1+ (1,0) [0|0] "" Vector__XXX
 SG_ EPBL_a104_VEH_summonCommand m104 : 36|1@1+ (1,0) [0|0] "" Vector__XXX
 SG_ EPBL_a113_CH_chassisControl m113 : 36|1@1+ (1,0) [0|0] "" Vector__XXX
 SG_ EPBL_a116_PARTY_restraintStatus m116 : 36|1@1+ (1,0) [0|0] "" Vector__XXX
 SG_ EPBL_a117_PARTY_restraintStatus m117 : 36|1@1+ (1,0) [0|0] "" Vector__XXX
 SG_ EPBL_a118_PARTY_vehNm m118 : 36|1@1+ (1,0) [0|0] "" Vector__XXX
 SG_ EPBL_a120_CH_speed m120 : 36|1@1+ (1,0) [0|0] "" Vector__XXX
 SG_ EPBL_a253_summonState m253 : 36|3@1+ (1,0) [0|0] "" Vector__XXX
 SG_ EPBL_a256_steeringDriveStatusBlock m256 : 36|1@1+ (1,0) [0|0] "" Vector__XXX
 SG_ EPBL_a264_uiServiceModePlus m264 : 36|1@1+ (1,0) [0|0] "" Vector__XXX
 SG_ EPBL_a016_NVMMWriteFailed m16 : 37|1@1+ (1,0) [0|0] "" Vector__XXX
 SG_ EPBL_a104_VEH_status m104 : 37|1@1+ (1,0) [0|0] "" Vector__XXX
 SG_ EPBL_a113_CH_powertrainControl m113 : 37|1@1+ (1,0) [0|0] "" Vector__XXX
 SG_ EPBL_a116_PARTY_doorStatus m116 : 37|1@1+ (1,0) [0|0] "" Vector__XXX
 SG_ EPBL_a117_VEH_thermalStatus m117 : 37|1@1+ (1,0) [0|0] "" Vector__XXX
 SG_ EPBL_a118_CH_12VBatteryStatus m118 : 37|1@1+ (1,0) [0|0] "" Vector__XXX
 SG_ EPBL_a120_VEH_estimatedBrakeTemp m120 : 37|1@1+ (1,0) [0|0] "" Vector__XXX
 SG_ EPBL_a174_monitorFaultStatus m174 : 37|2@1+ (1,0) [0|0] "" Vector__XXX
 SG_ EPBL_a175_monitorFaultStatus m175 : 37|2@1+ (1,0) [0|0] "" Vector__XXX
 SG_ EPBL_a176_monitorFaultStatus m176 : 37|2@1+ (1,0) [0|0] "" Vector__XXX
 SG_ EPBL_a177_monitorFaultStatus m177 : 37|2@1+ (1,0) [0|0] "" Vector__XXX
 SG_ EPBL_a179_monitorFaultStatus m179 : 37|2@1+ (1,0) [0|0] "" Vector__XXX
 SG_ EPBL_a180_panicModeLatched m180 : 37|1@1+ (1,0) [0|0] "" Vector__XXX
 SG_ EPBL_a184_panicModeLatched m184 : 37|1@1+ (1,0) [0|0] "" Vector__XXX
 SG_ EPBL_a186_panicModeLatched m186 : 37|1@1+ (1,0) [0|0] "" Vector__XXX
 SG_ EPBL_a187_panicModeLatched m187 : 37|1@1+ (1,0) [0|0] "" Vector__XXX
 SG_ EPBL_a188_panicModeLatched m188 : 37|1@1+ (1,0) [0|0] "" Vector__XXX
 SG_ EPBL_a189_panicModeLatched m189 : 37|1@1+ (1,0) [0|0] "" Vector__XXX
 SG_ EPBL_a190_monitorFaultStatus m190 : 37|2@1+ (1,0) [0|0] "" Vector__XXX
 SG_ EPBL_a191_monitorFaultStatus m191 : 37|2@1+ (1,0) [0|0] "" Vector__XXX
 SG_ EPBL_a198_resistanceCalc m198 : 37|12@1+ (0.005,0) [0|0] "" Vector__XXX
 SG_ EPBL_a225_panicModeLatched m225 : 37|1@1+ (1,0) [0|0] "" Vector__XXX
 SG_ EPBL_a246_faultStatus m246 : 37|2@1+ (1,0) [0|0] "" Vector__XXX
 SG_ EPBL_a247_monitorFaultStatus m247 : 37|2@1+ (1,0) [0|0] "" Vector__XXX
 SG_ EPBL_a248_monitorFaultStatus m248 : 37|2@1+ (1,0) [0|0] "" Vector__XXX
 SG_ EPBL_a249_faultStatus m249 : 37|2@1+ (1,0) [0|0] "" Vector__XXX
 SG_ EPBL_a264_frunkOpen m264 : 37|1@1+ (1,0) [0|0] "" Vector__XXX
 SG_ EPBL_a104_CH_pscControl m104 : 38|1@1+ (1,0) [0|0] "" Vector__XXX
 SG_ EPBL_a113_VEH_tripPlanning m113 : 38|1@1+ (1,0) [0|0] "" Vector__XXX
 SG_ EPBL_a116_BDY_epbmStatus m116 : 38|1@1+ (1,0) [0|0] "" Vector__XXX
 SG_ EPBL_a117_PARTY_doorStatus m117 : 38|1@1+ (1,0) [0|0] "" Vector__XXX
 SG_ EPBL_a118_CH_LVBMS_statusHigh m118 : 38|1@1+ (1,0) [0|0] "" Vector__XXX
 SG_ EPBL_a120_PARTY_prndControl m120 : 38|1@1+ (1,0) [0|0] "" Vector__XXX
 SG_ EPBL_a180_activeDecelRequest m180 : 38|1@1+ (1,0) [0|0] "" Vector__XXX
 SG_ EPBL_a184_activeDecelRequest m184 : 38|1@1+ (1,0) [0|0] "" Vector__XXX
 SG_ EPBL_a186_activeDecelRequest m186 : 38|1@1+ (1,0) [0|0] "" Vector__XXX
 SG_ EPBL_a187_activeDecelRequest m187 : 38|1@1+ (1,0) [0|0] "" Vector__XXX
 SG_ EPBL_a188_activeDecelRequest m188 : 38|1@1+ (1,0) [0|0] "" Vector__XXX
 SG_ EPBL_a189_activeDecelRequest m189 : 38|1@1+ (1,0) [0|0] "" Vector__XXX
 SG_ EPBL_a225_activeDecelRequest m225 : 38|1@1+ (1,0) [0|0] "" Vector__XXX
 SG_ EPBL_a362_inputRodDriver m362 : 38|10@1+ (0.1,-10) [0|0] "" Vector__XXX
 SG_ EPBL_a363_inputRodDriver m363 : 38|10@1+ (0.1,-10) [0|0] "" Vector__XXX
 SG_ EPBL_a058_prevREstimate m58 : 39|12@1+ (0.00061,0) [0|0] "" Vector__XXX
 SG_ EPBL_a104_BDY_gpsAccuracies m104 : 39|1@1+ (1,0) [0|0] "" Vector__XXX
 SG_ EPBL_a113_VEH_vehicleControl3 m113 : 39|1@1+ (1,0) [0|0] "" Vector__XXX
 SG_ EPBL_a116_BDY_restraintStatus m116 : 39|1@1+ (1,0) [0|0] "" Vector__XXX
 SG_ EPBL_a117_VEH_status m117 : 39|1@1+ (1,0) [0|0] "" Vector__XXX
 SG_ EPBL_a118_CH_alertMatrix m118 : 39|1@1+ (1,0) [0|0] "" Vector__XXX
 SG_ EPBL_a120_PARTY_locStatus2 m120 : 39|1@1+ (1,0) [0|0] "" Vector__XXX
 SG_ EPBL_a253_lvDriveStatusBlock m253 : 39|1@1+ (1,0) [0|0] "" Vector__XXX
 SG_ EPBL_a022_TaskInitError2 m22 : 40|8@1+ (1,0) [0|0] "" Vector__XXX
 SG_ EPBL_a031_uds_bytes_3 m31 : 40|8@1+ (1,0) [0|0] "" Vector__XXX
 SG_ EPBL_a041_CPULoad100msTask m41 : 40|8@1+ (1,0) [0|0] "" Vector__XXX
 SG_ EPBL_a042_Usage1000msTask m42 : 40|8@1+ (1,0) [0|0] "" Vector__XXX
 SG_ EPBL_a043_CallTrace1 m43 : 40|24@1+ (1,0) [0|0] "" Vector__XXX
 SG_ EPBL_a044_CallTrace1 m44 : 40|24@1+ (1,0) [0|0] "" Vector__XXX
 SG_ EPBL_a045_CallTrace1 m45 : 40|24@1+ (1,0) [0|0] "" Vector__XXX
 SG_ EPBL_a046_CallTrace1 m46 : 40|24@1+ (1,0) [0|0] "" Vector__XXX
 SG_ EPBL_a059_current m59 : 40|12@1+ (0.05,0) [0|0] "" Vector__XXX
 SG_ EPBL_a063_disconnected m63 : 40|1@1+ (1,0) [0|0] "" Vector__XXX
 SG_ EPBL_a104_BDY_control m104 : 40|1@1+ (1,0) [0|0] "" Vector__XXX
 SG_ EPBL_a113_VEH_vehicleControlThermal m113 : 40|1@1+ (1,0) [0|0] "" Vector__XXX
 SG_ EPBL_a116_BDY_switchStatus m116 : 40|1@1+ (1,0) [0|0] "" Vector__XXX
 SG_ EPBL_a117_PARTY_prndStatus m117 : 40|1@1+ (1,0) [0|0] "" Vector__XXX
 SG_ EPBL_a118_BDY_outputPowerStatus m118 : 40|1@1+ (1,0) [0|0] "" Vector__XXX
 SG_ EPBL_a120_VEH_chassisCntl m120 : 40|1@1+ (1,0) [0|0] "" Vector__XXX
 SG_ EPBL_a125_12vFilt m125 : 40|12@1+ (0.005443676098,0) [0|0] "" Vector__XXX
 SG_ EPBL_a126_12vFilt m126 : 40|12@1+ (0.005443676098,0) [0|0] "" Vector__XXX
 SG_ EPBL_a127_12vFilt m127 : 40|12@1+ (0.005443676098,0) [0|0] "" Vector__XXX
 SG_ EPBL_a128_12vFilt m128 : 40|12@1+ (0.005443676098,0) [0|0] "" Vector__XXX
 SG_ EPBL_a134_12vFilt m134 : 40|12@1+ (0.005443676098,0) [0|0] "" Vector__XXX
 SG_ EPBL_a135_12vFilt m135 : 40|12@1+ (0.005443676098,0) [0|0] "" Vector__XXX
 SG_ EPBL_a136_12vFilt m136 : 40|12@1+ (0.005443676098,0) [0|0] "" Vector__XXX
 SG_ EPBL_a137_12vFilt m137 : 40|12@1+ (0.005443676098,0) [0|0] "" Vector__XXX
 SG_ EPBL_a170_12vFilt m170 : 40|12@1+ (0.005443676098,0) [0|0] "" Vector__XXX
 SG_ EPBL_a171_12vFilt m171 : 40|12@1+ (0.005443676098,0) [0|0] "" Vector__XXX
 SG_ EPBL_a174_csmFaultReason m174 : 40|5@1+ (1,0) [0|0] "" Vector__XXX
 SG_ EPBL_a175_csmFaultReason m175 : 40|5@1+ (1,0) [0|0] "" Vector__XXX
 SG_ EPBL_a176_csmFaultReason m176 : 40|5@1+ (1,0) [0|0] "" Vector__XXX
 SG_ EPBL_a177_csmFaultReason m177 : 40|5@1+ (1,0) [0|0] "" Vector__XXX
 SG_ EPBL_a179_csmFaultReason m179 : 40|5@1+ (1,0) [0|0] "" Vector__XXX
 SG_ EPBL_a182_vcTrailerDetected m182 : 40|1@1+ (1,0) [0|0] "" Vector__XXX
 SG_ EPBL_a183_esmOperationTrigger m183 : 40|6@1+ (1,0) [0|0] "" Vector__XXX
 SG_ EPBL_a190_csmFaultReason m190 : 40|5@1+ (1,0) [0|0] "" Vector__XXX
 SG_ EPBL_a191_csmFaultReason m191 : 40|5@1+ (1,0) [0|0] "" Vector__XXX
 SG_ EPBL_a216_byte2 m216 : 40|8@1+ (1,0) [0|0] "" Vector__XXX
 SG_ EPBL_a217_byte7 m217 : 40|8@1+ (1,0) [0|0] "" Vector__XXX
 SG_ EPBL_a246_esmOpTrigger m246 : 40|6@1+ (1,0) [0|0] "" Vector__XXX
 SG_ EPBL_a247_csmFaultReason m247 : 40|5@1+ (1,0) [0|0] "" Vector__XXX
 SG_ EPBL_a248_csmFaultReason m248 : 40|5@1+ (1,0) [0|0] "" Vector__XXX
 SG_ EPBL_a249_esmOpTrigger m249 : 40|6@1+ (1,0) [0|0] "" Vector__XXX
 SG_ EPBL_a253_steeringDriveStatusBlock m253 : 40|1@1+ (1,0) [0|0] "" Vector__XXX
 SG_ EPBL_a357_brakeTemp m357 : 40|11@1+ (1,-40) [0|0] "" Vector__XXX
 SG_ EPBL_a358_brakeTemp m358 : 40|11@1+ (1,-40) [0|0] "" Vector__XXX
 SG_ EPBL_a365_vcTrailerDetected m365 : 40|1@1+ (1,0) [0|0] "" Vector__XXX
 SG_ EPBL_a366_vcTrailerDetected m366 : 40|1@1+ (1,0) [0|0] "" Vector__XXX
 SG_ EPBL_a063_indeterminate m63 : 41|1@1+ (1,0) [0|0] "" Vector__XXX
 SG_ EPBL_a104_BDY_status m104 : 41|1@1+ (1,0) [0|0] "" Vector__XXX
 SG_ EPBL_a113_CH_odo m113 : 41|1@1+ (1,0) [0|0] "" Vector__XXX
 SG_ EPBL_a117_PARTY_lightingSecondary m117 : 41|1@1+ (1,0) [0|0] "" Vector__XXX
 SG_ EPBL_a118_BDY_vehicleTime m118 : 41|1@1+ (1,0) [0|0] "" Vector__XXX
 SG_ EPBL_a120_CH_locStatus2 m120 : 41|1@1+ (1,0) [0|0] "" Vector__XXX
 SG_ EPBL_a182_uiTrailerDetected m182 : 41|1@1+ (1,0) [0|0] "" Vector__XXX
 SG_ EPBL_a365_uiTrailerDetected m365 : 41|1@1+ (1,0) [0|0] "" Vector__XXX
 SG_ EPBL_a366_uiTrailerDetected m366 : 41|1@1+ (1,0) [0|0] "" Vector__XXX
 SG_ EPBL_a063_stuckActive m63 : 42|1@1+ (1,0) [0|0] "" Vector__XXX
 SG_ EPBL_a104_PARTY_autonomyControl m104 : 42|1@1+ (1,0) [0|0] "" Vector__XXX
 SG_ EPBL_a113_VEH_locationStatus m113 : 42|1@1+ (1,0) [0|0] "" Vector__XXX
 SG_ EPBL_a118_PARTY_AP_vehicleState1HzMuxed m118 : 42|1@1+ (1,0) [0|0] "" Vector__XXX
 SG_ EPBL_a120_VEH_locStatus m120 : 42|1@1+ (1,0) [0|0] "" Vector__XXX
 SG_ EPBL_a182_trailerDetected m182 : 42|1@1+ (1,0) [0|0] "" Vector__XXX
 SG_ EPBL_a350_ensTimedOut m350 : 42|1@1+ (1,0) [0|0] "" Vector__XXX
 SG_ EPBL_a352_startTime m352 : 42|10@1+ (10,0) [0|0] "" Vector__XXX
 SG_ EPBL_a365_trailerDetected m365 : 42|1@1+ (1,0) [0|0] "" Vector__XXX
 SG_ EPBL_a366_trailerDetected m366 : 42|1@1+ (1,0) [0|0] "" Vector__XXX
 SG_ EPBL_a063_faulted m63 : 43|1@1+ (1,0) [0|0] "" Vector__XXX
 SG_ EPBL_a104_VEH_autonomyControl m104 : 43|1@1+ (1,0) [0|0] "" Vector__XXX
 SG_ EPBL_a113_VEH_gpsTime m113 : 43|1@1+ (1,0) [0|0] "" Vector__XXX
 SG_ EPBL_a118_BDY_AP_vehicleState1HzMuxed m118 : 43|1@1+ (1,0) [0|0] "" Vector__XXX
 SG_ EPBL_a120_VEH_locStatus2 m120 : 43|1@1+ (1,0) [0|0] "" Vector__XXX
 SG_ EPBL_a104_CH_autonomyControl m104 : 44|1@1+ (1,0) [0|0] "" Vector__XXX
 SG_ EPBL_a113_VEH_gpsVehicleSpeed m113 : 44|1@1+ (1,0) [0|0] "" Vector__XXX
 SG_ EPBL_a118_PARTY_VCFRONT_cameraCleaningStatus m118 : 44|1@1+ (1,0) [0|0] "" Vector__XXX
 SG_ EPBL_a120_VEH_prndControl m120 : 44|1@1+ (1,0) [0|0] "" Vector__XXX
 SG_ EPBL_a104_BDY_autonomyControl m104 : 45|1@1+ (1,0) [0|0] "" Vector__XXX
 SG_ EPBL_a113_VEH_status2 m113 : 45|1@1+ (1,0) [0|0] "" Vector__XXX
 SG_ EPBL_a120_VEH_vehicleEstimates m120 : 45|1@1+ (1,0) [0|0] "" Vector__XXX
 SG_ EPBL_a251_temperature m251 : 45|9@1- (0.5,-40) [0|0] "" Vector__XXX
 SG_ EPBL_a303_temperature m303 : 45|9@1- (0.5,-40) [0|0] "" Vector__XXX
 SG_ EPBL_a104_VEH_wirelessChargingStatus m104 : 46|1@1+ (1,0) [0|0] "" Vector__XXX
 SG_ EPBL_a113_VEH_autopilotControl m113 : 46|1@1+ (1,0) [0|0] "" Vector__XXX
 SG_ EPBL_a120_PARTY_motorStatus m120 : 46|1@1+ (1,0) [0|0] "" Vector__XXX
 SG_ EPBL_a183_cdpNotStopping m183 : 46|1@1+ (1,0) [0|0] "" Vector__XXX
 SG_ EPBL_a104_VEH_control m104 : 47|1@1+ (1,0) [0|0] "" Vector__XXX
 SG_ EPBL_a113_VEH_ambientLightingCtrls m113 : 47|1@1+ (1,0) [0|0] "" Vector__XXX
 SG_ EPBL_a120_VEH_motorStatus m120 : 47|1@1+ (1,0) [0|0] "" Vector__XXX
 SG_ EPBL_a183_cdpNotStarting m183 : 47|1@1+ (1,0) [0|0] "" Vector__XXX
 SG_ EPBL_a000_alertDataW2 m0 : 48|16@1+ (1,0) [0|0] "" Vector__XXX
 SG_ EPBL_a003_Data m3 : 48|16@1+ (1,0) [0|0] "" Vector__XXX
 SG_ EPBL_a022_TaskInitError3 m22 : 48|8@1+ (1,0) [0|0] "" Vector__XXX
 SG_ EPBL_a031_uds_bytes_4 m31 : 48|8@1+ (1,0) [0|0] "" Vector__XXX
 SG_ EPBL_a041_CPULoad1000msTask m41 : 48|8@1+ (1,0) [0|0] "" Vector__XXX
 SG_ EPBL_a042_UsageUDSTask m42 : 48|8@1+ (1,0) [0|0] "" Vector__XXX
 SG_ EPBL_a104_VEH_redundantBrakingControl m104 : 48|1@1+ (1,0) [0|0] "" Vector__XXX
 SG_ EPBL_a113_VEH_driverAssistMapData m113 : 48|1@1+ (1,0) [0|0] "" Vector__XXX
 SG_ EPBL_a120_BDY_speed m120 : 48|1@1+ (1,0) [0|0] "" Vector__XXX
 SG_ EPBL_a140_localState m140 : 48|3@1+ (1,0) [0|0] "" Vector__XXX
 SG_ EPBL_a174_esmOpTrigger m174 : 48|6@1+ (1,0) [0|0] "" Vector__XXX
 SG_ EPBL_a175_esmOpTrigger m175 : 48|6@1+ (1,0) [0|0] "" Vector__XXX
 SG_ EPBL_a176_esmOpTrigger m176 : 48|6@1+ (1,0) [0|0] "" Vector__XXX
 SG_ EPBL_a177_esmOpTrigger m177 : 48|6@1+ (1,0) [0|0] "" Vector__XXX
 SG_ EPBL_a179_esmOpTrigger m179 : 48|6@1+ (1,0) [0|0] "" Vector__XXX
 SG_ EPBL_a183_remoteEpbDynamic m183 : 48|1@1+ (1,0) [0|0] "" Vector__XXX
 SG_ EPBL_a190_esmOpTrigger m190 : 48|6@1+ (1,0) [0|0] "" Vector__XXX
 SG_ EPBL_a191_esmOpTrigger m191 : 48|6@1+ (1,0) [0|0] "" Vector__XXX
 SG_ EPBL_a216_byte3 m216 : 48|8@1+ (1,0) [0|0] "" Vector__XXX
 SG_ EPBL_a247_esmOpTrigger m247 : 48|6@1+ (1,0) [0|0] "" Vector__XXX
 SG_ EPBL_a248_esmOpTrigger m248 : 48|6@1+ (1,0) [0|0] "" Vector__XXX
 SG_ EPBL_a301_oocDistanceFiltered m301 : 48|16@1+ (0.01,0) [0|0] "" Vector__XXX
 SG_ EPBL_a363_outputRodAct m363 : 48|10@1+ (0.1,-10) [0|0] "" Vector__XXX
 SG_ EPBL_a370_messageBitmask m370 : 48|16@1+ (1,0) [0|0] "" Vector__XXX
 SG_ EPBL_a104_BDY_bodyControls m104 : 49|1@1+ (1,0) [0|0] "" Vector__XXX
 SG_ EPBL_a113_CH_vehicleControl2 m113 : 49|1@1+ (1,0) [0|0] "" Vector__XXX
 SG_ EPBL_a183_localEpbDynamic m183 : 49|1@1+ (1,0) [0|0] "" Vector__XXX
 SG_ EPBL_a198_learnedEpbConfig m198 : 49|4@1+ (1,0) [0|0] "" Vector__XXX
 SG_ EPBL_a113_VEH_odo m113 : 50|1@1+ (1,0) [0|0] "" Vector__XXX
 SG_ EPBL_a183_epbmInvalidated m183 : 50|1@1+ (1,0) [0|0] "" Vector__XXX
 SG_ EPBL_a058_newREstimate m58 : 51|12@1+ (0.00061,0) [0|0] "" Vector__XXX
 SG_ EPBL_a140_monitorState m140 : 51|3@1+ (1,0) [0|0] "" Vector__XXX
 SG_ EPBL_a183_espConfirmedInvalid m183 : 51|1@1+ (1,0) [0|0] "" Vector__XXX
 SG_ EPBL_a357_vcTrailerDetected m357 : 51|1@1+ (1,0) [0|0] "" Vector__XXX
 SG_ EPBL_a358_vcTrailerDetected m358 : 51|1@1+ (1,0) [0|0] "" Vector__XXX
 SG_ EPBL_a183_brakeFluidConfirmedLow m183 : 52|1@1+ (1,0) [0|0] "" Vector__XXX
 SG_ EPBL_a352_duration m352 : 52|10@1+ (1,0) [0|0] "" Vector__XXX
 SG_ EPBL_a357_uiTrailerDetected m357 : 52|1@1+ (1,0) [0|0] "" Vector__XXX
 SG_ EPBL_a358_uiTrailerDetected m358 : 52|1@1+ (1,0) [0|0] "" Vector__XXX
 SG_ EPBL_a183_lastRemoteEpbDynamic m183 : 53|1@1+ (1,0) [0|0] "" Vector__XXX
 SG_ EPBL_a198_ambientTemp m198 : 53|8@1+ (0.5,-40) [0|0] "" Vector__XXX
 SG_ EPBL_a357_trailerDetected m357 : 53|1@1+ (1,0) [0|0] "" Vector__XXX
 SG_ EPBL_a358_trailerDetected m358 : 53|1@1+ (1,0) [0|0] "" Vector__XXX
 SG_ EPBL_a183_lastLocalEpbDynamic m183 : 54|1@1+ (1,0) [0|0] "" Vector__XXX
 SG_ EPBL_a183_cdpCannotBeCommanded m183 : 55|1@1+ (1,0) [0|0] "" Vector__XXX
 SG_ EPBL_a022_TaskInitError4 m22 : 56|8@1+ (1,0) [0|0] "" Vector__XXX
 SG_ EPBL_a031_uds_bytes_5 m31 : 56|8@1+ (1,0) [0|0] "" Vector__XXX
 SG_ EPBL_a041_CPULoadNVMMTask m41 : 56|8@1+ (1,0) [0|0] "" Vector__XXX
 SG_ EPBL_a042_UsageNVMMTask m42 : 56|8@1+ (1,0) [0|0] "" Vector__XXX
 SG_ EPBL_a174_nonterminalReason m174 : 56|5@1+ (1,0) [0|0] "" Vector__XXX
 SG_ EPBL_a175_nonterminalReason m175 : 56|5@1+ (1,0) [0|0] "" Vector__XXX
 SG_ EPBL_a176_nonterminalReason m176 : 56|5@1+ (1,0) [0|0] "" Vector__XXX
 SG_ EPBL_a177_nonterminalReason m177 : 56|5@1+ (1,0) [0|0] "" Vector__XXX
 SG_ EPBL_a179_nonterminalReason m179 : 56|5@1+ (1,0) [0|0] "" Vector__XXX
 SG_ EPBL_a183_remoteEpbStatusUnsure m183 : 56|1@1+ (1,0) [0|0] "" Vector__XXX
 SG_ EPBL_a190_nonterminalReason m190 : 56|5@1+ (1,0) [0|0] "" Vector__XXX
 SG_ EPBL_a191_nonterminalReason m191 : 56|5@1+ (1,0) [0|0] "" Vector__XXX
 SG_ EPBL_a247_nonterminalReason m247 : 56|5@1+ (1,0) [0|0] "" Vector__XXX
 SG_ EPBL_a248_nonterminalReason m248 : 56|5@1+ (1,0) [0|0] "" Vector__XXX
 SG_ EPBL_a183_lastLowBrakeFluid m183 : 57|1@1+ (1,0) [0|0] "" Vector__XXX
 SG_ EPBL_a183_espInvalidOrUnsure m183 : 58|1@1+ (1,0) [0|0] "" Vector__XXX
 SG_ EPBL_a183_lastFactoryMode m183 : 59|1@1+ (1,0) [0|0] "" Vector__XXX
 SG_ EPBL_a183_redundantBrakingEnabled m183 : 60|1@1+ (1,0) [0|0] "" Vector__XXX
 SG_ EPBL_a198_version m198 : 61|3@1+ (1,0) [0|0] "" Vector__XXX
 SG_ EPBL_a086_VEH_LVHealth m86 : 62|1@1+ (1,0) [0|0] "" Vector__XXX
 SG_ EPBL_a058_faultReason m58 : 63|1@1+ (1,0) [0|0] "" Vector__XXX
 SG_ EPBL_a086_VEH_pcsInterface m86 : 63|1@1+ (1,0) [0|0] "" Vector__XXX

BO_ 1487 APS_vbatVoltage: 8 Vector__XXX
 SG_ APS_A_vbatVoltage : 0|12@1+ (0.005689,0) [0|0] "" Vector__XXX
 SG_ APS_B_vbatVoltage : 12|12@1+ (0.005689,0) [0|0] "" Vector__XXX

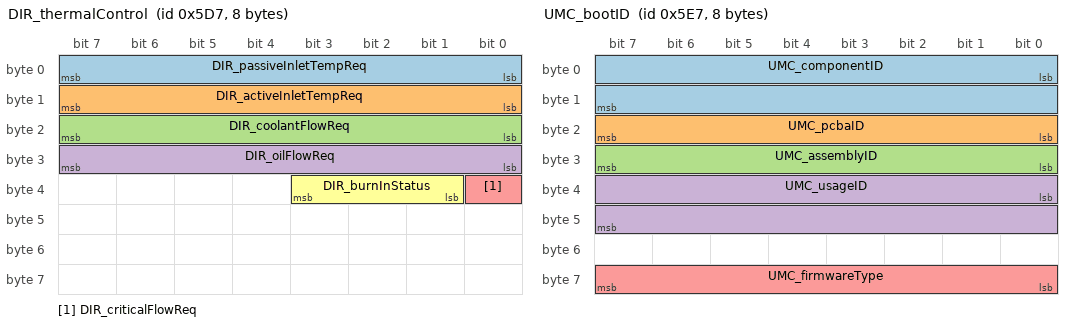
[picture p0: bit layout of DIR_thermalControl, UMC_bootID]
BO_ 1495 DIR_thermalControl: 8 Vector__XXX
 SG_ DIR_passiveInletTempReq : 0|8@1+ (1,-40) [0|0] "" Vector__XXX
 SG_ DIR_activeInletTempReq : 8|8@1+ (1,-40) [0|0] "" Vector__XXX
 SG_ DIR_coolantFlowReq : 16|8@1+ (0.2,0) [0|0] "" Vector__XXX
 SG_ DIR_oilFlowReq : 24|8@1+ (0.1,0) [0|0] "" Vector__XXX
 SG_ DIR_criticalFlowReq : 32|1@1+ (1,0) [0|0] "" Vector__XXX
 SG_ DIR_burnInStatus : 33|3@1+ (1,0) [0|0] "" Vector__XXX

BO_ 1508 PMF_bootID: 12 Vector__XXX
 SG_ PMF_componentID : 7|16@0+ (1,0) [0|0] "" Vector__XXX
 SG_ PMF_pcbaID : 23|8@0+ (1,0) [0|0] "" Vector__XXX
 SG_ PMF_assemblyID : 31|8@0+ (1,0) [0|0] "" Vector__XXX
 SG_ PMF_usageID : 39|16@0+ (1,0) [0|0] "" Vector__XXX
 SG_ PMF_firmwareType : 63|8@0+ (1,0) [0|0] "" Vector__XXX

BO_ 1511 UMC_bootID: 8 Vector__XXX
 SG_ UMC_componentID : 0|16@1+ (1,0) [0|0] "" Vector__XXX
 SG_ UMC_pcbaID : 16|8@1+ (1,0) [0|0] "" Vector__XXX
 SG_ UMC_assemblyID : 24|8@1+ (1,0) [0|0] "" Vector__XXX
 SG_ UMC_usageID : 32|16@1+ (1,0) [0|0] "" Vector__XXX
 SG_ UMC_firmwareType : 56|8@1+ (1,0) [0|0] "" Vector__XXX

BO_ 1522 BMS_bootID: 12 Vector__XXX
 SG_ BMS_bootComponentId : 7|16@0+ (1,0) [0|0] "" Vector__XXX
 SG_ BMS_bootPcbaId : 23|8@0+ (1,0) [0|0] "" Vector__XXX
 SG_ BMS_bootAssemblyId : 31|8@0+ (1,0) [0|0] "" Vector__XXX
 SG_ BMS_bootUsageId : 39|16@0+ (1,0) [0|0] "" Vector__XXX
 SG_ BMS_bootFirmwareType : 63|8@0+ (1,0) [0|0] "" Vector__XXX

BO_ 1523 UI_odo: 8 Vector__XXX
 SG_ UI_odometer : 0|24@1+ (0.1,0) [0|0] "" Vector__XXX

BO_ 1524 PMR_bootID: 12 Vector__XXX
 SG_ PMR_componentID : 7|16@0+ (1,0) [0|0] "" Vector__XXX
 SG_ PMR_pcbaID : 23|8@0+ (1,0) [0|0] "" Vector__XXX
 SG_ PMR_assemblyID : 31|8@0+ (1,0) [0|0] "" Vector__XXX
 SG_ PMR_usageID : 39|16@0+ (1,0) [0|0] "" Vector__XXX
 SG_ PMR_firmwareType : 63|8@0+ (1,0) [0|0] "" Vector__XXX

BO_ 1525 DIF_bootID: 12 Vector__XXX
 SG_ DIF_componentID : 7|16@0+ (1,0) [0|0] "" Vector__XXX
 SG_ DIF_pcbaID : 23|8@0+ (1,0) [0|0] "" Vector__XXX
 SG_ DIF_assemblyID : 31|8@0+ (1,0) [0|0] "" Vector__XXX
 SG_ DIF_usageID : 39|16@0+ (1,0) [0|0] "" Vector__XXX
 SG_ DIF_firmwareType : 63|8@0+ (1,0) [0|0] "" Vector__XXX

BO_ 1526 DIR_bootID: 12 Vector__XXX
 SG_ DIR_componentID : 7|16@0+ (1,0) [0|0] "" Vector__XXX
 SG_ DIR_pcbaID : 23|8@0+ (1,0) [0|0] "" Vector__XXX
 SG_ DIR_assemblyID : 31|8@0+ (1,0) [0|0] "" Vector__XXX
 SG_ DIR_usageID : 39|16@0+ (1,0) [0|0] "" Vector__XXX
 SG_ DIR_firmwareType : 63|8@0+ (1,0) [0|0] "" Vector__XXX

BO_ 1531 SDCR_alertLog: 8 Vector__XXX
 SG_ SDCR_alertID M : 0|6@1+ (1,0) [0|0] "" Vector__XXX
 SG_ SDCR_alertState : 15|1@1+ (1,0) [0|0] "" Vector__XXX
 SG_ SDCR_a000_alertDataW0 m0 : 16|16@1+ (1,0) [0|0] "" Vector__XXX
 SG_ SDCR_a001_pyroSenseV m1 : 16|8@1+ (0.02,0) [0|0] "" Vector__XXX
 SG_ SDCR_a002_skippedReason_unreliableDiPst m2 : 16|1@1+ (1,0) [0|0] "" Vector__XXX
 SG_ SDCR_a003_pmRunningPin m3 : 16|1@1+ (1,0) [0|0] "" Vector__XXX
 SG_ SDCR_a004_HVBackupSupplyV m4 : 16|8@1+ (0.15,0) [0|0] "" Vector__XXX
 SG_ SDCR_a006_pyroArmed m6 : 16|1@1+ (1,0) [0|0] "" Vector__XXX
 SG_ SDCR_a007_faultReason_faultCurrentsAtSpeed m7 : 16|1@1+ (1,0) [0|0] "" Vector__XXX
 SG_ SDCR_a008_dcLinkInfo m8 : 16|1@1+ (1,0) [0|0] "" Vector__XXX
 SG_ SDCR_a009_diVersion m9 : 16|2@1+ (1,0) [0|0] "" Vector__XXX
 SG_ SDCR_a010_pgood m10 : 16|1@1+ (1,0) [0|0] "" Vector__XXX
 SG_ SDCR_a011_IaAvg m11 : 16|16@1- (0.1,0) [0|0] "" Vector__XXX
 SG_ SDCR_a012_boostRailV m12 : 16|8@1+ (0.15,0) [0|0] "" Vector__XXX
 SG_ SDCR_a013_boostRailV m13 : 16|8@1+ (0.15,0) [0|0] "" Vector__XXX
 SG_ SDCR_a014_reason_vBusShortedLow m14 : 16|1@1+ (1,0) [0|0] "" Vector__XXX
 SG_ SDCR_a015_reason_vPhaseShortedLow m15 : 16|1@1+ (1,0) [0|0] "" Vector__XXX
 SG_ SDCR_a016_lowVoltageDetect m16 : 16|1@1+ (1,0) [0|0] "" Vector__XXX
 SG_ SDCR_a017_expectedConfigWord m17 : 16|16@1+ (1,0) [0|0] "" Vector__XXX
 SG_ SDCR_a018_pyroArmed m18 : 16|1@1+ (1,0) [0|0] "" Vector__XXX
 SG_ SDCR_a019_faultReason_faultCurrentsAtSpeed m19 : 16|1@1+ (1,0) [0|0] "" Vector__XXX
 SG_ SDCR_a020_errorCode m20 : 16|8@1+ (1,0) [0|0] "" Vector__XXX
 SG_ SDCR_a021_busBarTempC m21 : 16|8@1+ (1,-40) [0|0] "" Vector__XXX
 SG_ SDCR_a022_TaskInitErrorCount m22 : 16|8@1+ (1,0) [0|0] "" Vector__XXX
 SG_ SDCR_a023_logId m23 : 16|4@1+ (1,0) [0|0] "" Vector__XXX
 SG_ SDCR_a024_time m24 : 16|1@1+ (1,0) [0|0] "" Vector__XXX
 SG_ SDCR_a025_diSwitchingFromUart m25 : 16|1@1+ (1,0) [0|0] "" Vector__XXX
 SG_ SDCR_a027_power m27 : 16|1@1+ (1,0) [0|0] "" Vector__XXX
 SG_ SDCR_a028_LVPowerState m28 : 16|1@1+ (1,0) [0|0] "" Vector__XXX
 SG_ SDCR_a029_uartCommsMissing m29 : 16|1@1+ (1,0) [0|0] "" Vector__XXX
 SG_ SDCR_a034_Ia m34 : 16|16@1- (0.1,0) [0|0] "" Vector__XXX
 SG_ SDCR_a002_skippedReason_diSwitching m2 : 17|1@1+ (1,0) [0|0] "" Vector__XXX
 SG_ SDCR_a003_lvState m3 : 17|2@1+ (1,0) [0|0] "" Vector__XXX
 SG_ SDCR_a006_triggerReason_faultCurrents m6 : 17|1@1+ (1,0) [0|0] "" Vector__XXX
 SG_ SDCR_a007_faultReason_unmitigatedUCR m7 : 17|1@1+ (1,0) [0|0] "" Vector__XXX
 SG_ SDCR_a014_reason_vBusShortedHigh m14 : 17|1@1+ (1,0) [0|0] "" Vector__XXX
 SG_ SDCR_a015_reason_vPhaseShortedHigh m15 : 17|1@1+ (1,0) [0|0] "" Vector__XXX
 SG_ SDCR_a016_lossOfClock m16 : 17|1@1+ (1,0) [0|0] "" Vector__XXX
 SG_ SDCR_a018_triggerReason_faultCurrents m18 : 17|1@1+ (1,0) [0|0] "" Vector__XXX
 SG_ SDCR_a019_faultReason_unmitigatedUCR m19 : 17|1@1+ (1,0) [0|0] "" Vector__XXX
 SG_ SDCR_a025_diSwitchingPin m25 : 17|1@1+ (1,0) [0|0] "" Vector__XXX
 SG_ SDCR_a027_lvState m27 : 17|2@1+ (1,0) [0|0] "" Vector__XXX
 SG_ SDCR_a029_canCommsMissing m29 : 17|1@1+ (1,0) [0|0] "" Vector__XXX
 SG_ SDCR_a002_skippedReason_powerNotGood m2 : 18|1@1+ (1,0) [0|0] "" Vector__XXX
 SG_ SDCR_a006_triggerReason_hvBadAtSpeed m6 : 18|1@1+ (1,0) [0|0] "" Vector__XXX
 SG_ SDCR_a007_faultReason_propagating3PS m7 : 18|1@1+ (1,0) [0|0] "" Vector__XXX
 SG_ SDCR_a009_sdcVersion m9 : 18|2@1+ (1,0) [0|0] "" Vector__XXX
 SG_ SDCR_a015_diSwitchingPin m15 : 18|1@1+ (1,0) [0|0] "" Vector__XXX
 SG_ SDCR_a016_wdog m16 : 18|1@1+ (1,0) [0|0] "" Vector__XXX
 SG_ SDCR_a018_triggerReason_hvBadAtSpeed m18 : 18|1@1+ (1,0) [0|0] "" Vector__XXX
 SG_ SDCR_a019_faultReason_propagating3PS m19 : 18|1@1+ (1,0) [0|0] "" Vector__XXX
 SG_ SDCR_a025_pmRunningPin m25 : 18|1@1+ (1,0) [0|0] "" Vector__XXX
 SG_ SDCR_a029_lvState m29 : 18|2@1+ (1,0) [0|0] "" Vector__XXX
 SG_ SDCR_a002_skippedReason_motorCurrentsPresent m2 : 19|1@1+ (1,0) [0|0] "" Vector__XXX
 SG_ SDCR_a003_timeout m3 : 19|1@1+ (1,0) [0|0] "" Vector__XXX
 SG_ SDCR_a006_triggerReason_highBackEMF m6 : 19|1@1+ (1,0) [0|0] "" Vector__XXX
 SG_ SDCR_a007_speedWasValid m7 : 19|1@1+ (1,0) [0|0] "" Vector__XXX
 SG_ SDCR_a015_vBat m15 : 19|10@1+ (2,0) [0|0] "" Vector__XXX
 SG_ SDCR_a016_externalResetPin m16 : 19|1@1+ (1,0) [0|0] "" Vector__XXX
 SG_ SDCR_a018_triggerReason_highBackEMF m18 : 19|1@1+ (1,0) [0|0] "" Vector__XXX
 SG_ SDCR_a019_speedWasValid m19 : 19|1@1+ (1,0) [0|0] "" Vector__XXX
 SG_ SDCR_a025_diUartMIA m25 : 19|1@1+ (1,0) [0|0] "" Vector__XXX
 SG_ SDCR_a027_timeout m27 : 19|1@1+ (1,0) [0|0] "" Vector__XXX
 SG_ SDCR_a002_pmRunningPin m2 : 20|1@1+ (1,0) [0|0] "" Vector__XXX
 SG_ SDCR_a006_faultCurrentsDetected m6 : 20|1@1+ (1,0) [0|0] "" Vector__XXX
 SG_ SDCR_a007_imbalanceSeen m7 : 20|1@1+ (1,0) [0|0] "" Vector__XXX
 SG_ SDCR_a016_powerOnReset m16 : 20|1@1+ (1,0) [0|0] "" Vector__XXX
 SG_ SDCR_a018_faultCurrentsDetected m18 : 20|1@1+ (1,0) [0|0] "" Vector__XXX
 SG_ SDCR_a019_imbalanceSeen m19 : 20|1@1+ (1,0) [0|0] "" Vector__XXX
 SG_ SDCR_a002_diSwitchingPin m2 : 21|1@1+ (1,0) [0|0] "" Vector__XXX
 SG_ SDCR_a006_diUartMIA m6 : 21|1@1+ (1,0) [0|0] "" Vector__XXX
 SG_ SDCR_a007_ucrSeen m7 : 21|1@1+ (1,0) [0|0] "" Vector__XXX
 SG_ SDCR_a016_lockup m16 : 21|1@1+ (1,0) [0|0] "" Vector__XXX
 SG_ SDCR_a018_diUartMIA m18 : 21|1@1+ (1,0) [0|0] "" Vector__XXX
 SG_ SDCR_a019_ucrSeen m19 : 21|1@1+ (1,0) [0|0] "" Vector__XXX
 SG_ SDCR_a002_diUartMIA m2 : 22|1@1+ (1,0) [0|0] "" Vector__XXX
 SG_ SDCR_a006_pmRunningPin m6 : 22|1@1+ (1,0) [0|0] "" Vector__XXX
 SG_ SDCR_a007_phaseVoltagePresent m7 : 22|1@1+ (1,0) [0|0] "" Vector__XXX
 SG_ SDCR_a016_software m16 : 22|1@1+ (1,0) [0|0] "" Vector__XXX
 SG_ SDCR_a018_pmRunningPin m18 : 22|1@1+ (1,0) [0|0] "" Vector__XXX
 SG_ SDCR_a019_phaseVoltagePresent m19 : 22|1@1+ (1,0) [0|0] "" Vector__XXX
 SG_ SDCR_a002_timeout m2 : 23|1@1+ (1,0) [0|0] "" Vector__XXX
 SG_ SDCR_a006_hvPowerGood m6 : 23|1@1+ (1,0) [0|0] "" Vector__XXX
 SG_ SDCR_a007_speedFromVoltage m7 : 23|1@1+ (1,0) [0|0] "" Vector__XXX
 SG_ SDCR_a016_mdmap m16 : 23|1@1+ (1,0) [0|0] "" Vector__XXX
 SG_ SDCR_a018_hvPowerGood m18 : 23|1@1+ (1,0) [0|0] "" Vector__XXX
 SG_ SDCR_a019_speedFromVoltage m19 : 23|1@1+ (1,0) [0|0] "" Vector__XXX
 SG_ SDCR_a001_HVBackupSupplyV m1 : 24|8@1+ (0.15,0) [0|0] "" Vector__XXX
 SG_ SDCR_a002_boostRailV m2 : 24|8@1+ (0.15,0) [0|0] "" Vector__XXX
 SG_ SDCR_a004_boostRailV m4 : 24|8@1+ (0.15,0) [0|0] "" Vector__XXX
 SG_ SDCR_a006_hvbkupPGoodPin m6 : 24|1@1+ (1,0) [0|0] "" Vector__XXX
 SG_ SDCR_a007_transientHandling m7 : 24|2@1+ (1,0) [0|0] "" Vector__XXX
 SG_ SDCR_a010_boostRailV m10 : 24|8@1+ (0.15,0) [0|0] "" Vector__XXX
 SG_ SDCR_a012_HVBackupSupplyV m12 : 24|8@1+ (0.15,0) [0|0] "" Vector__XXX
 SG_ SDCR_a013_HVBackupSupplyV m13 : 24|8@1+ (0.15,0) [0|0] "" Vector__XXX
 SG_ SDCR_a014_boostRailV m14 : 24|8@1+ (0.15,0) [0|0] "" Vector__XXX
 SG_ SDCR_a016_stopModeAcknowledge m16 : 24|1@1+ (1,0) [0|0] "" Vector__XXX
 SG_ SDCR_a018_hvbkupPGoodPin m18 : 24|1@1+ (1,0) [0|0] "" Vector__XXX
 SG_ SDCR_a019_transientHandling m19 : 24|2@1+ (1,0) [0|0] "" Vector__XXX
 SG_ SDCR_a020_rxData0 m20 : 24|8@1+ (1,0) [0|0] "" Vector__XXX
 SG_ SDCR_a021_busBarTempA m21 : 24|8@1+ (1,-40) [0|0] "" Vector__XXX
 SG_ SDCR_a022_TaskInitError0 m22 : 24|8@1+ (1,0) [0|0] "" Vector__XXX
 SG_ SDCR_a025_HVBackupSupplyV m25 : 24|8@1+ (0.15,0) [0|0] "" Vector__XXX
 SG_ SDCR_a006_hvPowerNotGoodQualified m6 : 25|1@1+ (1,0) [0|0] "" Vector__XXX
 SG_ SDCR_a018_hvPowerNotGoodQualified m18 : 25|1@1+ (1,0) [0|0] "" Vector__XXX
 SG_ SDCR_a006_speedValid m6 : 26|1@1+ (1,0) [0|0] "" Vector__XXX
 SG_ SDCR_a007_maxAbsElcSpeed m7 : 26|9@1+ (4,0) [0|0] "" Vector__XXX
 SG_ SDCR_a018_speedValid m18 : 26|1@1+ (1,0) [0|0] "" Vector__XXX
 SG_ SDCR_a019_maxAbsElcSpeed m19 : 26|9@1+ (4,0) [0|0] "" Vector__XXX
 SG_ SDCR_a006_speedFromVoltage m6 : 27|1@1+ (1,0) [0|0] "" Vector__XXX
 SG_ SDCR_a018_speedFromVoltage m18 : 27|1@1+ (1,0) [0|0] "" Vector__XXX
 SG_ SDCR_a006_HVBackupSupplyV m6 : 28|7@1+ (0.3,0) [0|0] "" Vector__XXX
 SG_ SDCR_a018_HVBackupSupplyV m18 : 28|7@1+ (0.3,0) [0|0] "" Vector__XXX
 SG_ SDCR_a015_va m15 : 29|10@1+ (2,0) [0|0] "" Vector__XXX
 SG_ SDCR_a000_alertDataW1 m0 : 32|16@1+ (1,0) [0|0] "" Vector__XXX
 SG_ SDCR_a001_boostRailV m1 : 32|8@1+ (0.15,0) [0|0] "" Vector__XXX
 SG_ SDCR_a002_HVBackupSupplyV m2 : 32|8@1+ (0.15,0) [0|0] "" Vector__XXX
 SG_ SDCR_a004_diPresent m4 : 32|1@1+ (1,0) [0|0] "" Vector__XXX
 SG_ SDCR_a010_Vref m10 : 32|8@1+ (0.02,0) [0|0] "" Vector__XXX
 SG_ SDCR_a011_IbAvg m11 : 32|16@1- (0.1,0) [0|0] "" Vector__XXX
 SG_ SDCR_a012_vBat m12 : 32|10@1+ (2,0) [0|0] "" Vector__XXX
 SG_ SDCR_a013_vBat m13 : 32|10@1+ (2,0) [0|0] "" Vector__XXX
 SG_ SDCR_a014_HVBackupSupplyV m14 : 32|8@1+ (0.15,0) [0|0] "" Vector__XXX
 SG_ SDCR_a017_receivedConfigWord m17 : 32|16@1+ (1,0) [0|0] "" Vector__XXX
 SG_ SDCR_a020_rxData1 m20 : 32|8@1+ (1,0) [0|0] "" Vector__XXX
 SG_ SDCR_a021_tempCVoltage m21 : 32|8@1+ (0.02,0) [0|0] "" Vector__XXX
 SG_ SDCR_a022_TaskInitError1 m22 : 32|8@1+ (1,0) [0|0] "" Vector__XXX
 SG_ SDCR_a025_boostRailV m25 : 32|8@1+ (0.15,0) [0|0] "" Vector__XXX
 SG_ SDCR_a034_Ib m34 : 32|16@1- (0.1,0) [0|0] "" Vector__XXX
 SG_ SDCR_a004_pmRunningPin m4 : 33|1@1+ (1,0) [0|0] "" Vector__XXX
 SG_ SDCR_a006_boostRailV m6 : 35|7@1+ (0.3,0) [0|0] "" Vector__XXX
 SG_ SDCR_a007_avgIa m7 : 35|10@1- (4,0) [0|0] "" Vector__XXX
 SG_ SDCR_a018_boostRailV m18 : 35|7@1+ (0.3,0) [0|0] "" Vector__XXX
 SG_ SDCR_a019_avgIa m19 : 35|10@1- (4,0) [0|0] "" Vector__XXX
 SG_ SDCR_a001_expectedPyroV_max m1 : 40|8@1+ (0.02,0) [0|0] "" Vector__XXX
 SG_ SDCR_a002_magI2 m2 : 40|16@1+ (34.33279926756695,0) [0|0] "" Vector__XXX
 SG_ SDCR_a014_vBat m14 : 40|10@1+ (2,0) [0|0] "" Vector__XXX
 SG_ SDCR_a015_vb m15 : 40|10@1+ (2,0) [0|0] "" Vector__XXX
 SG_ SDCR_a020_rxData2 m20 : 40|8@1+ (1,0) [0|0] "" Vector__XXX
 SG_ SDCR_a021_tempAVoltage m21 : 40|8@1+ (0.02,0) [0|0] "" Vector__XXX
 SG_ SDCR_a022_TaskInitError2 m22 : 40|8@1+ (1,0) [0|0] "" Vector__XXX
 SG_ SDCR_a006_maxAbsSpeed m6 : 42|12@1- (1,0) [0|0] "" Vector__XXX
 SG_ SDCR_a012_vbkupGoodFdbk m12 : 42|1@1+ (1,0) [0|0] "" Vector__XXX
 SG_ SDCR_a013_vbkupGoodFdbk m13 : 42|1@1+ (1,0) [0|0] "" Vector__XXX
 SG_ SDCR_a018_maxAbsSpeed m18 : 42|12@1- (1,0) [0|0] "" Vector__XXX
 SG_ SDCR_a007_avgIb m7 : 45|10@1- (4,0) [0|0] "" Vector__XXX
 SG_ SDCR_a019_avgIb m19 : 45|10@1- (4,0) [0|0] "" Vector__XXX
 SG_ SDCR_a000_alertDataW2 m0 : 48|16@1+ (1,0) [0|0] "" Vector__XXX
 SG_ SDCR_a001_expectedPyroV_min m1 : 48|8@1+ (0.02,0) [0|0] "" Vector__XXX
 SG_ SDCR_a017_configMismatch m17 : 48|1@1+ (1,0) [0|0] "" Vector__XXX
 SG_ SDCR_a020_rxData3 m20 : 48|8@1+ (1,0) [0|0] "" Vector__XXX
 SG_ SDCR_a022_TaskInitError3 m22 : 48|8@1+ (1,0) [0|0] "" Vector__XXX
 SG_ SDCR_a017_convStartTimeout m17 : 49|1@1+ (1,0) [0|0] "" Vector__XXX
 SG_ SDCR_a014_vbkupGoodFdbk m14 : 50|1@1+ (1,0) [0|0] "" Vector__XXX
 SG_ SDCR_a015_vc m15 : 50|10@1+ (2,0) [0|0] "" Vector__XXX
 SG_ SDCR_a017_convCompleteTimeout m17 : 50|1@1+ (1,0) [0|0] "" Vector__XXX
 SG_ SDCR_a017_dmaSpiTxTransferError m17 : 51|1@1+ (1,0) [0|0] "" Vector__XXX
 SG_ SDCR_a017_dmaSpiRxTransferError m17 : 52|1@1+ (1,0) [0|0] "" Vector__XXX
 SG_ SDCR_a017_dmaSpiTimerEnabled m17 : 53|1@1+ (1,0) [0|0] "" Vector__XXX
 SG_ SDCR_a006_vBat m6 : 54|7@1+ (8,0) [0|0] "" Vector__XXX
 SG_ SDCR_a018_vBat m18 : 54|7@1+ (8,0) [0|0] "" Vector__XXX
 SG_ SDCR_a007_maxAbsCurrents m7 : 55|9@1+ (4,0) [0|0] "" Vector__XXX
 SG_ SDCR_a019_maxAbsCurrents m19 : 55|9@1+ (4,0) [0|0] "" Vector__XXX
 SG_ SDCR_a001_fromState m1 : 56|3@1+ (1,0) [0|0] "" Vector__XXX
 SG_ SDCR_a020_rxData4 m20 : 56|8@1+ (1,0) [0|0] "" Vector__XXX
 SG_ SDCR_a022_TaskInitError4 m22 : 56|8@1+ (1,0) [0|0] "" Vector__XXX

BO_ 1533 UMC_alertLog: 8 Vector__XXX
 SG_ UMC_alertID M : 0|15@1+ (1,0) [0|0] "" Vector__XXX
 SG_ UMC_alertType : 15|1@1+ (1,0) [0|0] "" Vector__XXX
 SG_ UMC_a002_ccidRmsCurrent m2 : 16|12@1+ (0.001,0) [0|0] "" Vector__XXX
 SG_ UMC_a003_faultType m3 : 16|8@1+ (1,0) [0|0] "" Vector__XXX
 SG_ UMC_a004_lineVoltage m4 : 16|16@1+ (1,0) [0|0] "" Vector__XXX
 SG_ UMC_a005_lineVoltage m5 : 16|16@1+ (1,0) [0|0] "" Vector__XXX
 SG_ UMC_a006_outputVoltage m6 : 16|16@1+ (1,0) [0|0] "" Vector__XXX
 SG_ UMC_a007_pcbaTemp m7 : 16|16@1+ (1,0) [0|0] "" Vector__XXX
 SG_ UMC_a008_wallPlugTemp m8 : 16|16@1+ (1,0) [0|0] "" Vector__XXX
 SG_ UMC_a009_vehConnTemp m9 : 16|16@1+ (1,0) [0|0] "" Vector__XXX
 SG_ UMC_a010_inputTerminalsTemp m10 : 16|16@1+ (1,0) [0|0] "" Vector__XXX
 SG_ UMC_a012_pilotHigh m12 : 16|12@1- (0.01,0) [0|0] "" Vector__XXX
 SG_ UMC_a013_SA_region m13 : 16|4@1+ (1,0) [0|0] "" Vector__XXX
 SG_ UMC_a015_SA_region m15 : 16|4@1+ (1,0) [0|0] "" Vector__XXX
 SG_ UMC_a016_pcbaTemp m16 : 16|16@1+ (1,0) [0|0] "" Vector__XXX
 SG_ UMC_a017_wallPlugTemp m17 : 16|16@1+ (1,0) [0|0] "" Vector__XXX
 SG_ UMC_a018_vehConnTemp m18 : 16|16@1+ (1,0) [0|0] "" Vector__XXX
 SG_ UMC_a019_inputTerminalsTemp m19 : 16|16@1+ (1,0) [0|0] "" Vector__XXX
 SG_ UMC_a025_outputVoltage m25 : 16|16@1+ (1,0) [0|0] "" Vector__XXX
 SG_ UMC_a026_nominalVoltage m26 : 16|9@1+ (0.01,0) [0|0] "" Vector__XXX
 SG_ UMC_a027_failureCause m27 : 16|8@1+ (1,0) [0|0] "" Vector__XXX
 SG_ UMC_a028_resetCause m28 : 16|4@1+ (1,0) [0|0] "" Vector__XXX
 SG_ UMC_a031_relayCoilVoltage m31 : 16|8@1+ (0.14,0) [0|0] "" Vector__XXX
 SG_ UMC_a032_chcVRFailureReason m32 : 16|4@1+ (1,0) [0|0] "" Vector__XXX
 SG_ UMC_a033_chcUFReason m33 : 16|6@1+ (1,0) [0|0] "" Vector__XXX
 SG_ UMC_a034_v2lSAUnsupportedReason m34 : 16|4@1+ (1,0) [0|0] "" Vector__XXX
 SG_ UMC_a037_gfciCalibrationOffset m37 : 16|16@1+ (1,0) [0|0] "" Vector__XXX
 SG_ UMC_a039_currentNominal m39 : 16|16@1+ (1,0) [0|0] "" Vector__XXX
 SG_ UMC_a041_irrationalReason m41 : 16|4@1+ (1,0) [0|0] "" Vector__XXX
 SG_ UMC_a032_chcVRExpectedCrc m32 : 20|32@1+ (1,0) [0|0] "" Vector__XXX
 SG_ UMC_a033_chcUFUpdateAttempt m33 : 22|32@1+ (1,0) [0|0] "" Vector__XXX
 SG_ UMC_a003_ccidSelfTestDuty m3 : 24|16@1+ (0.0001,50) [0|0] "" Vector__XXX
 SG_ UMC_a013_SA_current m13 : 24|8@1+ (1,0) [0|0] "" Vector__XXX
 SG_ UMC_a015_SA_current m15 : 24|8@1+ (1,0) [0|0] "" Vector__XXX
 SG_ UMC_a027_watchdogTask m27 : 24|8@1+ (1,0) [0|0] "" Vector__XXX
 SG_ UMC_a031_processorTemperature m31 : 24|9@1+ (1,88) [0|0] "" Vector__XXX
 SG_ UMC_a026_measuredVoltage m26 : 25|9@1+ (0.01,0) [0|0] "" Vector__XXX
 SG_ UMC_a002_ccidRmsCurrentAvg m2 : 28|12@1+ (0.001,0) [0|0] "" Vector__XXX
 SG_ UMC_a012_pilotLow m12 : 28|12@1- (0.01,0) [0|0] "" Vector__XXX
 SG_ UMC_a001_groundImpedance m1 : 32|32@1+ (1,0) [0|0] "" Vector__XXX
 SG_ UMC_a004_inputVoltage m4 : 32|16@1+ (0.01,0) [0|0] "" Vector__XXX
 SG_ UMC_a005_inputVoltage m5 : 32|16@1+ (0.01,0) [0|0] "" Vector__XXX
 SG_ UMC_a006_faultType m6 : 32|4@1+ (1,0) [0|0] "" Vector__XXX
 SG_ UMC_a008_SA_region m8 : 32|4@1+ (1,0) [0|0] "" Vector__XXX
 SG_ UMC_a017_SA_region m17 : 32|4@1+ (1,0) [0|0] "" Vector__XXX
 SG_ UMC_a024_groundImpedance m24 : 32|32@1+ (1,0) [0|0] "" Vector__XXX
 SG_ UMC_a025_umcReceptacleVoltage m25 : 32|12@1+ (0.1,0) [0|0] "" Vector__XXX
 SG_ UMC_a027_expiredWatchdogAppCRC m27 : 32|32@1+ (1,0) [0|0] "" Vector__XXX
 SG_ UMC_a037_gfciFactoryOffset m37 : 32|16@1+ (1,0) [0|0] "" Vector__XXX
 SG_ UMC_a039_currentThreshold m39 : 32|16@1+ (1,0) [0|0] "" Vector__XXX
 SG_ UMC_a040_groundImpedance m40 : 32|32@1+ (1,0) [0|0] "" Vector__XXX
 SG_ UMC_a006_umcReceptacleVoltage m6 : 36|12@1+ (0.1,0) [0|0] "" Vector__XXX
 SG_ UMC_a002_ccidDCGfciCurrent m2 : 40|10@1- (0.001,0) [0|0] "" Vector__XXX
 SG_ UMC_a003_ccidSelfTestCurrent m3 : 40|16@1+ (0.0001,0) [0|0] "" Vector__XXX
 SG_ UMC_a008_SA_current m8 : 40|8@1+ (1,0) [0|0] "" Vector__XXX
 SG_ UMC_a017_SA_current m17 : 40|8@1+ (1,0) [0|0] "" Vector__XXX
 SG_ UMC_a025_handleVoltage m25 : 44|12@1+ (0.1,0) [0|0] "" Vector__XXX
 SG_ UMC_a004_inputNeutralVoltage m4 : 48|16@1+ (0.01,0) [0|0] "" Vector__XXX
 SG_ UMC_a005_inputNeutralVoltage m5 : 48|16@1+ (0.01,0) [0|0] "" Vector__XXX
 SG_ UMC_a006_handleVoltage m6 : 48|12@1+ (0.1,0) [0|0] "" Vector__XXX
 SG_ UMC_a037_gfciFactoryScaling m37 : 48|13@1+ (1,0) [0|0] "" Vector__XXX
 SG_ UMC_a039_currentMeasured m39 : 48|16@1+ (1,0) [0|0] "" Vector__XXX
 SG_ UMC_a002_ccidFaultReason m2 : 50|4@1+ (1,0) [0|0] "" Vector__XXX
 SG_ UMC_a002_ccidFaultBucket m2 : 54|4@1+ (1,0) [0|0] "" Vector__XXX
 SG_ UMC_a025_line1StuckOpen m25 : 56|1@1+ (1,0) [0|0] "" Vector__XXX
 SG_ UMC_a025_line2StuckOpen m25 : 57|1@1+ (1,0) [0|0] "" Vector__XXX
 SG_ UMC_a006_line1StuckClosed m6 : 60|1@1+ (1,0) [0|0] "" Vector__XXX
 SG_ UMC_a006_line2StuckClosed m6 : 61|1@1+ (1,0) [0|0] "" Vector__XXX
 SG_ UMC_a037_gfciFactoryCalPresent m37 : 61|1@1+ (1,0) [0|0] "" Vector__XXX

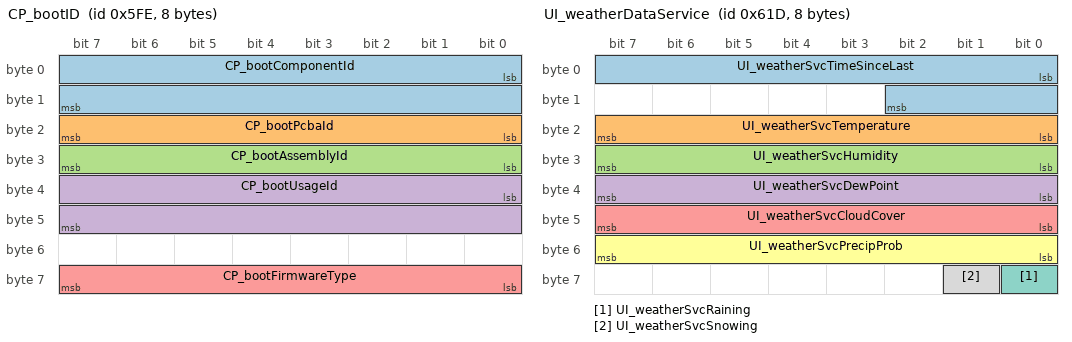
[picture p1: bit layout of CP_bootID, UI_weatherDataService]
BO_ 1534 CP_bootID: 8 Vector__XXX
 SG_ CP_bootComponentId : 0|16@1+ (1,0) [0|0] "" Vector__XXX
 SG_ CP_bootPcbaId : 16|8@1+ (1,0) [0|0] "" Vector__XXX
 SG_ CP_bootAssemblyId : 24|8@1+ (1,0) [0|0] "" Vector__XXX
 SG_ CP_bootUsageId : 32|16@1+ (1,0) [0|0] "" Vector__XXX
 SG_ CP_bootFirmwareType : 56|8@1+ (1,0) [0|0] "" Vector__XXX

BO_ 1536 UDS_vcfrontRequest: 12 Vector__XXX
 SG_ UDS_vcfrontRequestData : 7|64@0+ (1,0) [0|0] "" Vector__XXX

BO_ 1537 VCFRONT_udsResponse: 12 Vector__XXX
 SG_ VCFRONT_udsResponseData : 7|64@0+ (1,0) [0|0] "" Vector__XXX

BO_ 1538 UDS_bmsRequest: 12 Vector__XXX
 SG_ UDS_bmsRequestData : 7|64@0+ (1,0) [0|0] "" Vector__XXX

BO_ 1539 UDS_cmpRequest: 12 Vector__XXX
 SG_ UDS_cmpRequestData : 7|64@0+ (1,0) [0|0] "" Vector__XXX

BO_ 1540 UDS_pmrRequest: 12 Vector__XXX
 SG_ UDS_pmrRequestData : 7|64@0+ (1,0) [0|0] "" Vector__XXX

BO_ 1541 UDS_difRequest: 12 Vector__XXX
 SG_ UDS_difRequestData : 7|64@0+ (1,0) [0|0] "" Vector__XXX

BO_ 1542 UDS_dirRequest: 12 Vector__XXX
 SG_ UDS_dirRequestData : 7|64@0+ (1,0) [0|0] "" Vector__XXX

BO_ 1543 UDS_cmpdRequest: 12 Vector__XXX
 SG_ UDS_cmpdRequestData : 7|64@0+ (1,0) [0|0] "" Vector__XXX

BO_ 1544 UDS_vcrightRequest: 12 Vector__XXX
 SG_ UDS_vcrightRequestData_H : 7|32@0+ (1,0) [0|0] "" Vector__XXX
 SG_ UDS_vcrightRequestData_L : 39|32@0+ (1,0) [0|0] "" Vector__XXX

BO_ 1545 VCRIGHT_udsResponse: 12 Vector__XXX
 SG_ VCRIGHT_udsResponseData_H : 7|32@0+ (1,0) [0|0] "" Vector__XXX
 SG_ VCRIGHT_udsResponseData_L : 39|32@0+ (1,0) [0|0] "" Vector__XXX

BO_ 1546 UDS_vcsecRequest: 12 Vector__XXX
 SG_ UDS_vcsecRequestData : 7|64@0+ (1,0) [0|0] "" Vector__XXX

BO_ 1547 VCSEC_udsResponse: 12 Vector__XXX
 SG_ VCSEC_udsResponseData : 7|64@0+ (1,0) [0|0] "" Vector__XXX

BO_ 1548 UDS_vcbatt1Request: 12 Vector__XXX
 SG_ UDS_vcbatt1RequestData : 7|64@0+ (1,0) [0|0] "" Vector__XXX

BO_ 1549 VCBATT1_udsResponse: 12 Vector__XXX
 SG_ VCBATT1_udsResponseData : 7|64@0+ (1,0) [0|0] "" Vector__XXX

BO_ 1550 UDS_cpRequest: 12 Vector__XXX
 SG_ UDS_cpRequestData : 7|64@0+ (1,0) [0|0] "" Vector__XXX

BO_ 1551 PM_info: 8 Vector__XXX
 SG_ PM_infoIndex M : 0|8@1+ (1,0) [0|0] "" Vector__XXX
 SG_ PM_appGitHash m17 : 8|56@1+ (1,0) [0|0] "" Vector__XXX
 SG_ PM_bootGitHash m18 : 8|56@1+ (1,0) [0|0] "" Vector__XXX
 SG_ PM_buildType m10 : 8|8@1+ (1,0) [0|0] "" Vector__XXX
 SG_ PM_diNodeBuildType m21 : 8|8@1+ (1,0) [0|0] "" Vector__XXX
 SG_ PM_platformTyp m19 : 8|8@1+ (1,0) [0|0] "" Vector__XXX
 SG_ PM_udsProtocolVersion m20 : 8|8@1+ (1,0) [0|0] "" Vector__XXX
 SG_ PM_buildConfigurationId m10 : 16|16@1+ (1,0) [0|0] "" Vector__XXX
 SG_ PM_diNodeBuildConfigurationId m21 : 16|16@1+ (1,0) [0|0] "" Vector__XXX
 SG_ PM_pcbaId m11 : 16|8@1+ (1,0) [0|0] "" Vector__XXX
 SG_ PM_assemblyId m11 : 24|8@1+ (1,0) [0|0] "" Vector__XXX
 SG_ PM_applicationCrc m13 : 32|32@1+ (1,0) [0|0] "" Vector__XXX
 SG_ PM_bootloaderCrc m20 : 32|32@1+ (1,0) [0|0] "" Vector__XXX
 SG_ PM_diNodeApplicationCrc m21 : 32|32@1+ (1,0) [0|0] "" Vector__XXX
 SG_ PM_hardwareId m10 : 32|8@1+ (1,0) [0|0] "" Vector__XXX
 SG_ PM_usageId m11 : 32|16@1+ (1,0) [0|0] "" Vector__XXX
 SG_ PM_componentId m10 : 48|16@1+ (1,0) [0|0] "" Vector__XXX
 SG_ PM_subUsageId m11 : 48|16@1+ (1,0) [0|0] "" Vector__XXX

BO_ 1552 UDS_hvpRequest: 12 Vector__XXX
 SG_ UDS_hvpRequestData : 7|64@0+ (1,0) [0|0] "" Vector__XXX

BO_ 1553 HVP_udsResponse: 12 Vector__XXX
 SG_ HVP_udsResponseData : 7|64@0+ (1,0) [0|0] "" Vector__XXX

BO_ 1554 BMS_udsResponse: 12 Vector__XXX
 SG_ BMS_udsResponseData : 7|64@0+ (1,0) [0|0] "" Vector__XXX

BO_ 1555 CMP_udsResponse: 12 Vector__XXX
 SG_ CMP_udsResponseData : 7|64@0+ (1,0) [0|0] "" Vector__XXX

BO_ 1556 PMR_udsResponse: 12 Vector__XXX
 SG_ PMR_udsResponseData : 7|64@0+ (1,0) [0|0] "" Vector__XXX

BO_ 1557 DIF_udsResponse: 12 Vector__XXX
 SG_ DIF_udsResponseData : 7|64@0+ (1,0) [0|0] "" Vector__XXX

BO_ 1558 DIR_udsResponse: 12 Vector__XXX
 SG_ DIR_udsResponseData : 7|64@0+ (1,0) [0|0] "" Vector__XXX

BO_ 1559 CMPD_udsResponse: 12 Vector__XXX
 SG_ CMPD_udsResponseData : 7|64@0+ (1,0) [0|0] "" Vector__XXX

BO_ 1560 UDS_icrRequest: 12 Vector__XXX
 SG_ UDS_icrRequestData : 7|64@0+ (1,0) [0|0] "" Vector__XXX

BO_ 1562 UDS_vcbatt2Request: 12 Vector__XXX
 SG_ UDS_vcbatt2RequestData : 7|64@0+ (1,0) [0|0] "" Vector__XXX

BO_ 1563 VCBATT2_udsResponse: 12 Vector__XXX
 SG_ VCBATT2_udsResponseData : 7|64@0+ (1,0) [0|0] "" Vector__XXX

BO_ 1565 UI_weatherDataService: 8 Vector__XXX
 SG_ UI_weatherSvcTimeSinceLast : 0|11@1+ (1,0) [0|0] "" Vector__XXX
 SG_ UI_weatherSvcTemperature : 16|8@1- (0.5,0) [0|0] "" Vector__XXX
 SG_ UI_weatherSvcHumidity : 24|8@1+ (0.5,0) [0|0] "" Vector__XXX
 SG_ UI_weatherSvcDewPoint : 32|8@1+ (0.5,0) [0|0] "" Vector__XXX
 SG_ UI_weatherSvcCloudCover : 40|8@1+ (0.5,0) [0|0] "" Vector__XXX
 SG_ UI_weatherSvcPrecipProb : 48|8@1+ (0.5,0) [0|0] "" Vector__XXX
 SG_ UI_weatherSvcRaining : 56|1@1+ (1,0) [0|0] "" Vector__XXX
 SG_ UI_weatherSvcSnowing : 57|1@1+ (1,0) [0|0] "" Vector__XXX

BO_ 1566 CP_udsResponse: 12 Vector__XXX
 SG_ CP_udsResponseData : 7|64@0+ (1,0) [0|0] "" Vector__XXX

BO_ 1568 UDS_pmRequest: 12 Vector__XXX
 SG_ UDS_pmRequestData : 7|64@0+ (1,0) [0|0] "" Vector__XXX

BO_ 1569 VCBATT_udsResponse: 12 Vector__XXX
 SG_ VCBATT_udsResponseData : 7|64@0+ (1,0) [0|0] "" Vector__XXX

BO_ 1570 UDS_vcleftRequest: 12 Vector__XXX
 SG_ UDS_vcleftRequestData_H : 7|32@0+ (1,0) [0|0] "" Vector__XXX
 SG_ UDS_vcleftRequestData_L : 39|32@0+ (1,0) [0|0] "" Vector__XXX

BO_ 1571 VCLEFT_udsResponse: 12 Vector__XXX
 SG_ VCLEFT_udsResponseData_H : 7|32@0+ (1,0) [0|0] "" Vector__XXX
 SG_ VCLEFT_udsResponseData_L : 39|32@0+ (1,0) [0|0] "" Vector__XXX

BO_ 1572 UDS_epblRequest: 12 Vector__XXX
 SG_ UDS_epblRequestData_H : 7|32@0+ (1,0) [0|0] "" Vector__XXX
 SG_ UDS_epblRequestData_L : 39|32@0+ (1,0) [0|0] "" Vector__XXX

BO_ 1573 EPBL_udsResponse: 12 Vector__XXX
 SG_ EPBL_udsResponseData_H : 7|32@0+ (1,0) [0|0] "" Vector__XXX
 SG_ EPBL_udsResponseData_L : 39|32@0+ (1,0) [0|0] "" Vector__XXX

BO_ 1574 UDS_epbrRequest: 12 Vector__XXX
 SG_ UDS_epbrRequestData_H : 7|32@0+ (1,0) [0|0] "" Vector__XXX
 SG_ UDS_epbrRequestData_L : 39|32@0+ (1,0) [0|0] "" Vector__XXX

BO_ 1575 EPBR_udsResponse: 12 Vector__XXX
 SG_ EPBR_udsResponseData_H : 7|32@0+ (1,0) [0|0] "" Vector__XXX
 SG_ EPBR_udsResponseData_L : 39|32@0+ (1,0) [0|0] "" Vector__XXX

BO_ 1576 UDS_pcsRequest: 12 Vector__XXX
 SG_ UDS_pcsRequestData : 7|64@0+ (1,0) [0|0] "" Vector__XXX

BO_ 1577 PCS_udsResponse: 12 Vector__XXX
 SG_ PCS_udsResponseData : 7|64@0+ (1,0) [0|0] "" Vector__XXX

BO_ 1579 UDS_ccRequest: 12 Vector__XXX
 SG_ UDS_ccRequestData : 7|64@0+ (1,0) [0|0] "" Vector__XXX

BO_ 1580 UDS_vcfront1Request: 12 Vector__XXX
 SG_ UDS_vcfront1RequestData : 7|64@0+ (1,0) [0|0] "" Vector__XXX

BO_ 1581 VCFRONT1_udsResponse: 12 Vector__XXX
 SG_ VCFRONT1_udsResponseData : 7|64@0+ (1,0) [0|0] "" Vector__XXX

BO_ 1582 UDS_vcfront2Request: 12 Vector__XXX
 SG_ UDS_vcfront2RequestData : 7|64@0+ (1,0) [0|0] "" Vector__XXX

BO_ 1583 VCFRONT2_udsResponse: 12 Vector__XXX
 SG_ VCFRONT2_udsResponseData : 7|64@0+ (1,0) [0|0] "" Vector__XXX

BO_ 1587 CMP_bootID: 12 Vector__XXX
 SG_ CMP_bootComponentId : 7|16@0+ (1,0) [0|0] "" Vector__XXX
 SG_ CMP_bootPcbaId : 23|8@0+ (1,0) [0|0] "" Vector__XXX
 SG_ CMP_bootAssemblyId : 31|8@0+ (1,0) [0|0] "" Vector__XXX
 SG_ CMP_bootUsageId : 39|16@0+ (1,0) [0|0] "" Vector__XXX
 SG_ CMP_bootFirmwareType : 63|8@0+ (1,0) [0|0] "" Vector__XXX

BO_ 1588 CMPD_bootID: 12 Vector__XXX
 SG_ CMPD_bootComponentId : 7|16@0+ (1,0) [0|0] "" Vector__XXX
 SG_ CMPD_bootPcbaId : 23|8@0+ (1,0) [0|0] "" Vector__XXX
 SG_ CMPD_bootAssemblyId : 31|8@0+ (1,0) [0|0] "" Vector__XXX
 SG_ CMPD_bootUsageId : 39|16@0+ (1,0) [0|0] "" Vector__XXX
 SG_ CMPD_bootFirmwareType : 63|8@0+ (1,0) [0|0] "" Vector__XXX

BO_ 1589 UDS_diRequest: 12 Vector__XXX
 SG_ UDS_diRequestData : 7|64@0+ (1,0) [0|0] "" Vector__XXX

BO_ 1590 DI_udsResponse: 12 Vector__XXX
 SG_ DI_udsResponseData : 7|64@0+ (1,0) [0|0] "" Vector__XXX

BO_ 1595 CC_udsResponse: 12 Vector__XXX
 SG_ CC_udsResponseData : 7|64@0+ (1,0) [0|0] "" Vector__XXX

BO_ 1597 SDCR_info: 12 Vector__XXX
 SG_ SDCR_infoIndex M : 0|8@1+ (1,0) [0|0] "" Vector__XXX
 SG_ SDCR_infoAppGitHash m17 : 8|56@1+ (1,0) [0|0] "" Vector__XXX
 SG_ SDCR_infoBootGitHash m18 : 8|56@1+ (1,0) [0|0] "" Vector__XXX
 SG_ SDCR_infoBootUdsProtoVersion m20 : 8|16@1+ (1,0) [0|0] "" Vector__XXX
 SG_ SDCR_infoPlatformType m19 : 8|8@1+ (1,0) [0|0] "" Vector__XXX
 SG_ SDCR_infoAppCrc m13 : 15|32@0+ (1,0) [0|0] "" Vector__XXX
 SG_ SDCR_infoBuildType m10 : 15|3@0+ (1,0) [0|0] "" Vector__XXX
 SG_ SDCR_infoPcbaId m11 : 15|8@0+ (1,0) [0|0] "" Vector__XXX
 SG_ SDCR_infoBuildConfigId m10 : 16|16@1+ (1,0) [0|0] "" Vector__XXX
 SG_ SDCR_infoAssemblyId m11 : 23|8@0+ (1,0) [0|0] "" Vector__XXX
 SG_ SDCR_infoBootCrc m20 : 24|32@1+ (1,0) [0|0] "" Vector__XXX
 SG_ SDCR_infoUsageId m11 : 31|16@0+ (1,0) [0|0] "" Vector__XXX
 SG_ SDCR_infoHardwareId m10 : 32|16@1+ (1,0) [0|0] "" Vector__XXX
 SG_ SDCR_infoSubUsageId m11 : 40|16@1+ (1,0) [0|0] "" Vector__XXX
 SG_ SDCR_infoComponentId m10 : 55|16@0+ (1,0) [0|0] "" Vector__XXX

BO_ 1600 PM_udsResponse: 12 Vector__XXX
 SG_ PM_udsResponseData : 7|64@0+ (1,0) [0|0] "" Vector__XXX

BO_ 1601 VCLEFT_rcmUdsRequest: 12 Vector__XXX
 SG_ VCLEFT_rcmUdsRequestData : 7|64@0+ (1,0) [0|0] "" Vector__XXX

BO_ 1604 UDS_pmfRequest: 12 Vector__XXX
 SG_ UDS_pmfRequestData : 7|64@0+ (1,0) [0|0] "" Vector__XXX

BO_ 1610 TAS_debugStates: 8 Vector__XXX
 SG_ TAS_debugStatesIndex M : 0|3@1+ (1,0) [0|0] "" Vector__XXX
 SG_ TAS_airlineTestStateDebug m2 : 8|4@1+ (1,0) [0|0] "" Vector__XXX
 SG_ TAS_inflateSpringsStateDebug m3 : 8|3@1+ (1,0) [0|0] "" Vector__XXX
 SG_ TAS_inletPressureCheckDebug m5 : 8|4@1+ (1,0) [0|0] "" Vector__XXX
 SG_ TAS_launchModeStateDebug m1 : 8|3@1+ (1,0) [0|0] "" Vector__XXX
 SG_ TAS_pressurizeHVPackStateDebug m4 : 8|4@1+ (1,0) [0|0] "" Vector__XXX

BO_ 1611 UDS_tasRequest: 12 Vector__XXX
 SG_ UDS_tasRequestData : 7|64@0+ (1,0) [0|0] "" Vector__XXX

BO_ 1615 PM_bootID: 12 Vector__XXX
 SG_ PM_componentID : 7|16@0+ (1,0) [0|0] "" Vector__XXX
 SG_ PM_pcbaID : 23|8@0+ (1,0) [0|0] "" Vector__XXX
 SG_ PM_assemblyID : 31|8@0+ (1,0) [0|0] "" Vector__XXX
 SG_ PM_usageID : 39|16@0+ (1,0) [0|0] "" Vector__XXX
 SG_ PM_firmwareType : 63|8@0+ (1,0) [0|0] "" Vector__XXX

BO_ 1617 RCM_udsResponse: 12 Vector__XXX
 SG_ RCM_udsResponseData : 7|64@0+ (1,0) [0|0] "" Vector__XXX

BO_ 1620 PMF_udsResponse: 12 Vector__XXX
 SG_ PMF_udsResponseData : 7|64@0+ (1,0) [0|0] "" Vector__XXX

BO_ 1622 DIF_info: 8 Vector__XXX
 SG_ DIF_infoIndex M : 0|8@1+ (1,0) [0|0] "" Vector__XXX
 SG_ DIF_appGitHash m17 : 8|56@1+ (1,0) [0|0] "" Vector__XXX
 SG_ DIF_bootGitHash m18 : 8|56@1+ (1,0) [0|0] "" Vector__XXX
 SG_ DIF_buildType m10 : 8|3@1+ (1,0) [0|0] "" Vector__XXX
 SG_ DIF_infoBootLdUdsProtocolVersion m20 : 8|8@1+ (1,0) [0|0] "" Vector__XXX
 SG_ DIF_motorType m12 : 8|6@1+ (1,0) [0|0] "" Vector__XXX
 SG_ DIF_oilPumpBuildType m16 : 8|3@1+ (1,0) [0|0] "" Vector__XXX
 SG_ DIF_oilPumpPcbaId m33 : 8|8@1+ (1,0) [0|0] "" Vector__XXX
 SG_ DIF_platformTyp m19 : 8|8@1+ (1,0) [0|0] "" Vector__XXX
 SG_ DIF_refRotorFlux m35 : 8|16@1+ (0.0001,0) [0|0] "" Vector__XXX
 SG_ DIF_speedWearTotal m36 : 8|8@1+ (0.4,0) [0|0] "" Vector__XXX
 SG_ DIF_subcomponentGitHash m31 : 8|56@1+ (1,0) [0|0] "" Vector__XXX
 SG_ DIF_buildConfigurationId m10 : 16|16@1+ (1,0) [0|0] "" Vector__XXX
 SG_ DIF_oilPumpAppCrc m16 : 16|32@1+ (1,0) [0|0] "" Vector__XXX
 SG_ DIF_oilPumpAssemblyId m33 : 16|8@1+ (1,0) [0|0] "" Vector__XXX
 SG_ DIF_pcbaId m11 : 16|8@1+ (1,0) [0|0] "" Vector__XXX
 SG_ DIF_siliconType m12 : 16|1@1+ (1,0) [0|0] "" Vector__XXX
 SG_ DIF_assemblyId m11 : 24|8@1+ (1,0) [0|0] "" Vector__XXX
 SG_ DIF_mechSafeStateType m12 : 24|2@1+ (1,0) [0|0] "" Vector__XXX
 SG_ DIF_oilPumpUsageId m33 : 24|16@1+ (1,0) [0|0] "" Vector__XXX
 SG_ DIF_refRotorOffset m35 : 24|12@1- (0.1,0) [0|0] "" Vector__XXX
 SG_ DIF_torqueWearTotal m36 : 24|8@1+ (0.02,0) [0|0] "" Vector__XXX
 SG_ DIF_applicationCrc m13 : 32|32@1+ (1,0) [0|0] "" Vector__XXX
 SG_ DIF_bootloaderCrc m20 : 32|32@1+ (1,0) [0|0] "" Vector__XXX
 SG_ DIF_hardwareId m10 : 32|8@1+ (1,0) [0|0] "" Vector__XXX
 SG_ DIF_usageId m11 : 32|16@1+ (1,0) [0|0] "" Vector__XXX
 SG_ DIF_FPGA_version m16 : 48|8@1+ (1,0) [0|0] "" Vector__XXX
 SG_ DIF_componentId m10 : 48|16@1+ (1,0) [0|0] "" Vector__XXX
 SG_ DIF_subUsageId m11 : 48|16@1+ (1,0) [0|0] "" Vector__XXX

BO_ 1623 DI_info: 8 Vector__XXX
 SG_ DI_infoIndex M : 0|8@1+ (1,0) [0|0] "" Vector__XXX
 SG_ DI_J1979lifePositiveKineticEnergy m40 : 8|12@1+ (20,0) [0|0] "" Vector__XXX
 SG_ DI_J1979lifeTotalDistanceTraveled m44 : 8|20@1+ (1,0) [0|0] "" Vector__XXX
 SG_ DI_J1979lifeTotalPropulsionSystemActive m42 : 8|21@1+ (0.05,0) [0|0] "" Vector__XXX
 SG_ DI_J1979recentPositiveKineticEnergy m41 : 8|12@1+ (20,0) [0|0] "" Vector__XXX
 SG_ DI_J1979recentTotalPropulsionSystemActive m43 : 8|10@1+ (0.05,0) [0|0] "" Vector__XXX
 SG_ DI_appGitHash m17 : 8|56@1+ (1,0) [0|0] "" Vector__XXX
 SG_ DI_bootGitHash m18 : 8|56@1+ (1,0) [0|0] "" Vector__XXX
 SG_ DI_buildType m10 : 8|3@1+ (1,0) [0|0] "" Vector__XXX
 SG_ DI_infoBootLdUdsProtocolVersion m20 : 8|8@1+ (1,0) [0|0] "" Vector__XXX
 SG_ DI_platformTyp m19 : 8|8@1+ (1,0) [0|0] "" Vector__XXX
 SG_ DI_buildConfigurationId m10 : 16|16@1+ (1,0) [0|0] "" Vector__XXX
 SG_ DI_pcbaId m11 : 16|8@1+ (1,0) [0|0] "" Vector__XXX
 SG_ DI_J1979recentIdlePropulsionSystemActive m43 : 18|10@1+ (0.05,0) [0|0] "" Vector__XXX
 SG_ DI_J1979lifeMotorAOutputElectricalEnergy m40 : 20|14@1+ (5,0) [0|0] "" Vector__XXX
 SG_ DI_J1979recentMotorAOutputElectricalEnergy m41 : 20|14@1+ (0.2,0) [0|0] "" Vector__XXX
 SG_ DI_assemblyId m11 : 24|8@1+ (1,0) [0|0] "" Vector__XXX
 SG_ DI_J1979recentCityPropulsionSystemActive m43 : 28|10@1+ (0.05,0) [0|0] "" Vector__XXX
 SG_ DI_J1979recentTotalDistanceTraveled m44 : 28|14@1+ (1,0) [0|0] "" Vector__XXX
 SG_ DI_J1979lifeIdlePropulsionSystemActive m42 : 32|21@1+ (0.05,0) [0|0] "" Vector__XXX
 SG_ DI_applicationCrc m13 : 32|32@1+ (1,0) [0|0] "" Vector__XXX
 SG_ DI_bootloaderCrc m20 : 32|32@1+ (1,0) [0|0] "" Vector__XXX
 SG_ DI_hardwareId m10 : 32|8@1+ (1,0) [0|0] "" Vector__XXX
 SG_ DI_usageId m11 : 32|16@1+ (1,0) [0|0] "" Vector__XXX
 SG_ DI_J1979lifeMotorBOutputElectricalEnergy m40 : 34|14@1+ (5,0) [0|0] "" Vector__XXX
 SG_ DI_J1979recentMotorBOutputElectricalEnergy m41 : 34|14@1+ (0.2,0) [0|0] "" Vector__XXX
 SG_ DI_J1979lifePropulsionSystemActiveEvents m43 : 38|16@1+ (1,0) [0|0] "" Vector__XXX
 SG_ DI_J1979lifeCityPropulsionSystemActive m44 : 42|21@1+ (0.05,0) [0|0] "" Vector__XXX
 SG_ DI_J1979lifeMotorCOutputElectricalEnergy m40 : 48|14@1+ (5,0) [0|0] "" Vector__XXX
 SG_ DI_J1979recentMotorCOutputElectricalEnergy m41 : 48|14@1+ (0.2,0) [0|0] "" Vector__XXX
 SG_ DI_componentId m10 : 48|16@1+ (1,0) [0|0] "" Vector__XXX
 SG_ DI_subUsageId m11 : 48|16@1+ (1,0) [0|0] "" Vector__XXX
 SG_ DI_J1979internalFreezeConditionActive m42 : 53|1@1+ (1,0) [0|0] "" Vector__XXX
 SG_ DI_J1979recentPropulsionSystemActiveEvents m43 : 54|10@1+ (1,0) [0|0] "" Vector__XXX

BO_ 1624 ICR_udsResponse: 12 Vector__XXX
 SG_ ICR_udsResponseData : 7|64@0+ (1,0) [0|0] "" Vector__XXX

BO_ 1627 TAS_udsResponse: 12 Vector__XXX
 SG_ TAS_udsResponseData : 7|64@0+ (1,0) [0|0] "" Vector__XXX

BO_ 1633 UDS_vcbattRequest: 12 Vector__XXX
 SG_ UDS_vcbattRequestData : 7|64@0+ (1,0) [0|0] "" Vector__XXX

BO_ 1634 UDS_plgRequest: 12 Vector__XXX
 SG_ UDS_plgRequestData : 7|64@0+ (1,0) [0|0] "" Vector__XXX

BO_ 1635 PLG_udsResponse: 12 Vector__XXX
 SG_ PLG_udsResponseData : 7|64@0+ (1,0) [0|0] "" Vector__XXX

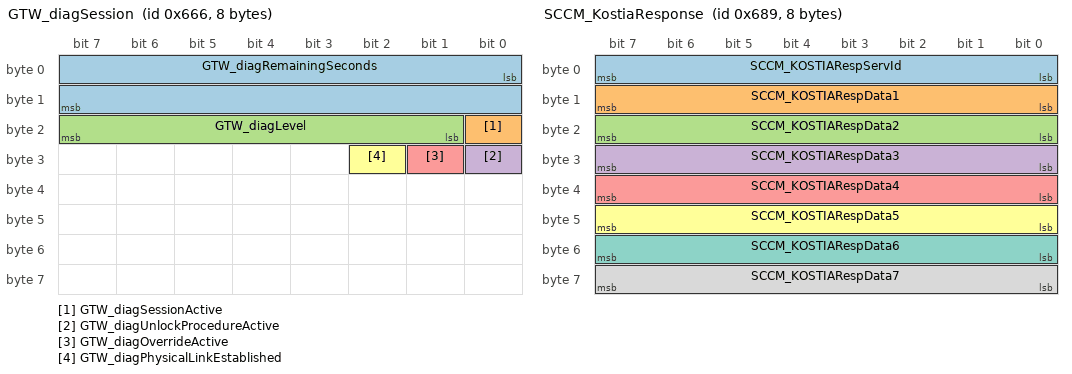
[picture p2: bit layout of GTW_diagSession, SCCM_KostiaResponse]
BO_ 1638 GTW_diagSession: 8 Vector__XXX
 SG_ GTW_diagRemainingSeconds : 0|16@1+ (1,0) [0|0] "" Vector__XXX
 SG_ GTW_diagSessionActive : 16|1@1+ (1,0) [0|0] "" Vector__XXX
 SG_ GTW_diagLevel : 17|7@1+ (1,0) [0|0] "" Vector__XXX
 SG_ GTW_diagUnlockProcedureActive : 24|1@1+ (1,0) [0|0] "" Vector__XXX
 SG_ GTW_diagOverrideActive : 25|1@1+ (1,0) [0|0] "" Vector__XXX
 SG_ GTW_diagPhysicalLinkEstablished : 26|1@1+ (1,0) [0|0] "" Vector__XXX

BO_ 1641 UDS_KOSTIAsccmRequest: 12 Vector__XXX
 SG_ UDS_KOSTIAsccmRequestData : 7|64@0+ (1,0) [0|0] "" Vector__XXX

BO_ 1650 HCML_info: 8 Vector__XXX
 SG_ VC_hcmlInfoIndex M : 0|4@1+ (1,0) [0|0] "" Vector__XXX
 SG_ VC_hcmlBoost_OV m7 : 4|1@1+ (1,0) [0|0] "" Vector__XXX
 SG_ VC_hcmlFault_DRL_THERMAL m4 : 4|1@1+ (1,0) [0|0] "" Vector__XXX
 SG_ VC_hcmlFault_HB_THERMAL m2 : 4|1@1+ (1,0) [0|0] "" Vector__XXX
 SG_ VC_hcmlFault_LB_THERMAL m3 : 4|1@1+ (1,0) [0|0] "" Vector__XXX
 SG_ VC_hcmlFault_SM_THERMAL m5 : 4|1@1+ (1,0) [0|0] "" Vector__XXX
 SG_ VC_hcmlVoltage_HB m6 : 4|10@1+ (0.1,0) [0|0] "" Vector__XXX
 SG_ VC_hcmlBoost_BOOTUV m7 : 5|1@1+ (1,0) [0|0] "" Vector__XXX
 SG_ VC_hcmlFault_DRL_VBCKUVLO m4 : 5|1@1+ (1,0) [0|0] "" Vector__XXX
 SG_ VC_hcmlFault_HB_VBCKUVLO m2 : 5|1@1+ (1,0) [0|0] "" Vector__XXX
 SG_ VC_hcmlFault_LB_VBCKUVLO m3 : 5|1@1+ (1,0) [0|0] "" Vector__XXX
 SG_ VC_hcmlFault_SM_VBCKUVLO m5 : 5|1@1+ (1,0) [0|0] "" Vector__XXX
 SG_ VC_hcmlBoost_ILIM m7 : 6|1@1+ (1,0) [0|0] "" Vector__XXX
 SG_ VC_hcmlFault_DRL_SHORT m4 : 6|1@1+ (1,0) [0|0] "" Vector__XXX
 SG_ VC_hcmlFault_HB_SHORT m2 : 6|1@1+ (1,0) [0|0] "" Vector__XXX
 SG_ VC_hcmlFault_LB_SHORT m3 : 6|1@1+ (1,0) [0|0] "" Vector__XXX
 SG_ VC_hcmlFault_SM_SHORT m5 : 6|1@1+ (1,0) [0|0] "" Vector__XXX
 SG_ VC_hcmlBoost_ISPUV m7 : 7|1@1+ (1,0) [0|0] "" Vector__XXX
 SG_ VC_hcmlFault_DRL_COMPOV m4 : 7|1@1+ (1,0) [0|0] "" Vector__XXX
 SG_ VC_hcmlFault_HB_COMPOV m2 : 7|1@1+ (1,0) [0|0] "" Vector__XXX
 SG_ VC_hcmlFault_LB_COMPOV m3 : 7|1@1+ (1,0) [0|0] "" Vector__XXX
 SG_ VC_hcmlFault_SM_COMPOV m5 : 7|1@1+ (1,0) [0|0] "" Vector__XXX
 SG_ VC_hcmlFault_DRL_HSILIM m4 : 8|1@1+ (1,0) [0|0] "" Vector__XXX
 SG_ VC_hcmlFault_HB_HSILIM m2 : 8|1@1+ (1,0) [0|0] "" Vector__XXX
 SG_ VC_hcmlFault_LB_HSILIM m3 : 8|1@1+ (1,0) [0|0] "" Vector__XXX
 SG_ VC_hcmlFault_SM_HSILIM m5 : 8|1@1+ (1,0) [0|0] "" Vector__XXX
 SG_ VC_hcmlLowBeamHighBeamDeratingFactor m8 : 8|8@1+ (0.5,0) [0|0] "" Vector__XXX
 SG_ VC_infoHCMLAssemblyId m1 : 8|16@1+ (1,0) [0|0] "" Vector__XXX
 SG_ VC_infoHCMLBuildConfigId m0 : 8|16@1+ (1,0) [0|0] "" Vector__XXX
 SG_ VC_hcmlFault_DRL_LSILIM m4 : 9|1@1+ (1,0) [0|0] "" Vector__XXX
 SG_ VC_hcmlFault_HB_LSILIM m2 : 9|1@1+ (1,0) [0|0] "" Vector__XXX
 SG_ VC_hcmlFault_LB_LSILIM m3 : 9|1@1+ (1,0) [0|0] "" Vector__XXX
 SG_ VC_hcmlFault_SM_LSILIM m5 : 9|1@1+ (1,0) [0|0] "" Vector__XXX
 SG_ VC_hcmlFault_DRL_BOOTUV m4 : 10|1@1+ (1,0) [0|0] "" Vector__XXX
 SG_ VC_hcmlFault_HB_BOOTUV m2 : 10|1@1+ (1,0) [0|0] "" Vector__XXX
 SG_ VC_hcmlFault_LB_BOOTUV m3 : 10|1@1+ (1,0) [0|0] "" Vector__XXX
 SG_ VC_hcmlFault_SM_BOOTUV m5 : 10|1@1+ (1,0) [0|0] "" Vector__XXX
 SG_ VC_hcmlFault_DRL_TOFFMIN m4 : 11|1@1+ (1,0) [0|0] "" Vector__XXX
 SG_ VC_hcmlFault_HB_TOFFMIN m2 : 11|1@1+ (1,0) [0|0] "" Vector__XXX
 SG_ VC_hcmlFault_LB_TOFFMIN m3 : 11|1@1+ (1,0) [0|0] "" Vector__XXX
 SG_ VC_hcmlFault_SM_TOFFMIN m5 : 11|1@1+ (1,0) [0|0] "" Vector__XXX
 SG_ VC_hcmlFault_DRL_LEDUV m4 : 12|1@1+ (1,0) [0|0] "" Vector__XXX
 SG_ VC_hcmlFault_HB_LEDUV m2 : 12|1@1+ (1,0) [0|0] "" Vector__XXX
 SG_ VC_hcmlFault_LB_LEDUV m3 : 12|1@1+ (1,0) [0|0] "" Vector__XXX
 SG_ VC_hcmlFault_SM_LEDUV m5 : 12|1@1+ (1,0) [0|0] "" Vector__XXX
 SG_ VC_hcmlFault_DRL_LEDOV m4 : 13|1@1+ (1,0) [0|0] "" Vector__XXX
 SG_ VC_hcmlFault_HB_LEDOV m2 : 13|1@1+ (1,0) [0|0] "" Vector__XXX
 SG_ VC_hcmlFault_LB_LEDOV m3 : 13|1@1+ (1,0) [0|0] "" Vector__XXX
 SG_ VC_hcmlFault_SM_LEDOV m5 : 13|1@1+ (1,0) [0|0] "" Vector__XXX
 SG_ VC_hcmlFault_TURN_THERMAL m4 : 14|1@1+ (1,0) [0|0] "" Vector__XXX
 SG_ VC_hcmlVoltage_LB m6 : 14|10@1+ (0.1,0) [0|0] "" Vector__XXX
 SG_ VC_hcmlFault_TURN_VBCKUVLO m4 : 15|1@1+ (1,0) [0|0] "" Vector__XXX
 SG_ VC_hcmlDRLSideMarkerTurnDeratingFactor m8 : 16|8@1+ (0.5,0) [0|0] "" Vector__XXX
 SG_ VC_hcmlFault_TURN_SHORT m4 : 16|1@1+ (1,0) [0|0] "" Vector__XXX
 SG_ VC_hcml_ic400_EEPROMWriteCount m2 : 16|16@1+ (1,0) [0|0] "" Vector__XXX
 SG_ VC_hcml_ic500_EEPROMWriteCount m3 : 16|16@1+ (1,0) [0|0] "" Vector__XXX
 SG_ VC_hcml_ic700_EEPROMWriteCount m5 : 16|16@1+ (1,0) [0|0] "" Vector__XXX
 SG_ VC_hcmlFault_TURN_COMPOV m4 : 17|1@1+ (1,0) [0|0] "" Vector__XXX
 SG_ VC_hcmlFault_TURN_HSILIM m4 : 18|1@1+ (1,0) [0|0] "" Vector__XXX
 SG_ VC_hcmlFault_TURN_LSILIM m4 : 19|1@1+ (1,0) [0|0] "" Vector__XXX
 SG_ VC_hcmlFault_TURN_BOOTUV m4 : 20|1@1+ (1,0) [0|0] "" Vector__XXX
 SG_ VC_hcmlFault_TURN_TOFFMIN m4 : 21|1@1+ (1,0) [0|0] "" Vector__XXX
 SG_ VC_hcmlFault_TURN_LEDUV m4 : 22|1@1+ (1,0) [0|0] "" Vector__XXX
 SG_ VC_hcmlFault_TURN_LEDOV m4 : 23|1@1+ (1,0) [0|0] "" Vector__XXX
 SG_ VC_hcmlUartGroupsFullErrorCounter m8 : 24|8@1+ (1,0) [0|0] "" Vector__XXX
 SG_ VC_hcmlVoltage_DRL m6 : 24|10@1+ (0.1,0) [0|0] "" Vector__XXX
 SG_ VC_hcml_ic600_EEPROMWriteCount m4 : 24|16@1+ (1,0) [0|0] "" Vector__XXX
 SG_ VC_infoHCMLPcbaId m1 : 24|16@1+ (1,0) [0|0] "" Vector__XXX
 SG_ VC_leftHeadlampLMMVariant m0 : 24|2@1+ (1,0) [0|0] "" Vector__XXX
 SG_ VC_hcmlUartValidatedGroupsFullErrorCounter m8 : 32|8@1+ (1,0) [0|0] "" Vector__XXX
 SG_ VC_hcmlVoltage_TURN m6 : 34|10@1+ (0.1,0) [0|0] "" Vector__XXX
 SG_ VC_hcmlUartDmaQueueFullErrorCounter m8 : 40|8@1+ (1,0) [0|0] "" Vector__XXX
 SG_ VC_infoHCMLUsageId m1 : 40|16@1+ (1,0) [0|0] "" Vector__XXX
 SG_ VC_hcmlVoltage_SM m6 : 44|10@1+ (0.1,0) [0|0] "" Vector__XXX
 SG_ VC_hcmlUartQueueResetCounter m8 : 48|8@1+ (1,0) [0|0] "" Vector__XXX
 SG_ VC_hcmlVoltage_boostRail m6 : 54|10@1+ (0.1,0) [0|0] "" Vector__XXX

BO_ 1651 VEH_isoTpToEvse: 8 Vector__XXX
 SG_ VEH_isoTpToEvseData : 0|64@1+ (1,0) [0|0] "" Vector__XXX

BO_ 1655 VC_LVBMS_statusHigh: 8 Vector__XXX
 SG_ VC_lvbmsStatusHighIndex M : 0|3@1+ (1,0) [0|0] "" Vector__XXX
 SG_ VC_LVBMS_MOSCommand m4 : 3|1@1+ (1,0) [0|0] "" Vector__XXX
 SG_ VC_LVBMS_packCurrent m0 : 3|22@1+ (0.001,-2000) [0|0] "" Vector__XXX
 SG_ VC_LVBMS_voltageTarget m3 : 3|16@1+ (0.001,0) [0|0] "" Vector__XXX
 SG_ VC_LVBMS_ClearErrorCntrCommand m4 : 4|1@1+ (1,0) [0|0] "" Vector__XXX
 SG_ VC_LVBMS_ClearHistoricFaultCommand m4 : 5|1@1+ (1,0) [0|0] "" Vector__XXX
 SG_ VC_LVBMS_ResetLVBMSCommand m4 : 6|1@1+ (1,0) [0|0] "" Vector__XXX
 SG_ VC_LVBMS_EnterHibernationCommand m4 : 7|1@1+ (1,0) [0|0] "" Vector__XXX
 SG_ VC_LVBMS_ECPAState m4 : 8|2@1+ (1,0) [0|0] "" Vector__XXX
 SG_ VC_LVBMS_sumCellVoltage m1 : 8|16@1+ (0.001,0) [0|0] "" Vector__XXX
 SG_ VC_totalLVLoadCurrent m2 : 8|14@1- (0.1,0) [0|0] "" Vector__XXX
 SG_ VC_LVBMS_MOSState m4 : 10|2@1+ (1,0) [0|0] "" Vector__XXX
 SG_ VC_LVBMS_VehicleState m4 : 12|2@1+ (1,0) [0|0] "" Vector__XXX
 SG_ VC_LVBMS_LINWakeDisabled m4 : 14|1@1+ (1,0) [0|0] "" Vector__XXX
 SG_ VC_LVBMS_chargeType m4 : 16|3@1+ (1,0) [0|0] "" Vector__XXX
 SG_ VC_LVBMS_cellAndArcProtEnabled m4 : 19|1@1+ (1,0) [0|0] "" Vector__XXX
 SG_ VC_LVBMS_currentTarget m3 : 19|18@1+ (0.001,-122) [0|0] "" Vector__XXX
 SG_ VC_LVPackChargeCurrentLimit m2 : 22|12@1+ (0.1,0) [0|0] "" Vector__XXX
 SG_ VC_LVBMS_avgBrickVoltage m4 : 24|13@1+ (0.001,0) [0|0] "" Vector__XXX
 SG_ VC_LVBMS_maxBrickVoltage m1 : 24|13@1+ (0.001,0) [0|0] "" Vector__XXX
 SG_ VC_LVBMS_packVoltage m0 : 25|16@1+ (0.001,0) [0|0] "" Vector__XXX
 SG_ VC_LVPackCurrent m2 : 34|14@1- (0.1,0) [0|0] "" Vector__XXX
 SG_ VC_LVBMS_maxAllowedChargeCurrent m3 : 37|13@1+ (0.1,0) [0|0] "" Vector__XXX
 SG_ VC_LVBMS_maxBrickVoltageIndex m1 : 40|8@1+ (1,0) [0|0] "" Vector__XXX
 SG_ VC_LVBMS_minBrickVoltage m4 : 40|13@1+ (0.001,0) [0|0] "" Vector__XXX
 SG_ VC_LVBMS_packTemperature m0 : 41|9@1+ (0.5,-50) [0|0] "" Vector__XXX
 SG_ VC_LVBMS_estimatedPackOcv m2 : 48|16@1+ (0.001,0) [0|0] "" Vector__XXX
 SG_ VC_LVBMS_MOSTemperature m0 : 50|12@1+ (0.5,-50) [0|0] "" Vector__XXX
 SG_ VC_LVBMS_maxAllowedDischargeCurrent m3 : 50|13@1+ (0.1,0) [0|0] "" Vector__XXX
 SG_ VC_LVBMS_minBrickVoltageIndex m4 : 56|8@1+ (1,0) [0|0] "" Vector__XXX

BO_ 1659 SDCR_bootID: 12 Vector__XXX
 SG_ SDCR_bootComponentId : 7|16@0+ (1,0) [0|0] "" Vector__XXX
 SG_ SDCR_bootPcbaId : 23|8@0+ (1,0) [0|0] "" Vector__XXX
 SG_ SDCR_bootAssemblyId : 31|8@0+ (1,0) [0|0] "" Vector__XXX
 SG_ SDCR_bootUsageId : 39|16@0+ (1,0) [0|0] "" Vector__XXX
 SG_ SDCR_bootFirmwareType : 63|8@0+ (1,0) [0|0] "" Vector__XXX

BO_ 1662 EVSE_isoTpToVeh: 8 Vector__XXX
 SG_ EVSE_isoTpToVehData : 0|64@1+ (1,0) [0|0] "" Vector__XXX

BO_ 1664 UDS_sccmRequest: 12 Vector__XXX
 SG_ UDS_sccmRequestData : 7|64@0+ (1,0) [0|0] "" Vector__XXX

BO_ 1666 HVP_hvpFaults: 8 Vector__XXX
 SG_ HVP_overTemperatureFault : 0|1@1+ (1,0) [0|0] "" Vector__XXX
 SG_ HVP_overVoltageFault : 1|1@1+ (1,0) [0|0] "" Vector__XXX
 SG_ HVP_underVoltageFault : 2|1@1+ (1,0) [0|0] "" Vector__XXX
 SG_ HVP_primaryBmbMiaFault : 3|1@1+ (1,0) [0|0] "" Vector__XXX
 SG_ HVP_bmsMiaFault : 4|1@1+ (1,0) [0|0] "" Vector__XXX
 SG_ HVP_cpMiaFault : 5|1@1+ (1,0) [0|0] "" Vector__XXX
 SG_ HVP_pcsMiaFault : 6|1@1+ (1,0) [0|0] "" Vector__XXX
 SG_ HVP_cpFault : 7|1@1+ (1,0) [0|0] "" Vector__XXX
 SG_ HVP_shuntHwMiaFault : 8|1@1+ (1,0) [0|0] "" Vector__XXX
 SG_ HVP_shuntHwAndBmsMiaFault : 9|1@1+ (1,0) [0|0] "" Vector__XXX
 SG_ HVP_pyroMiaFault : 10|1@1+ (1,0) [0|0] "" Vector__XXX
 SG_ HVP_pyroMiaWarning : 11|1@1+ (1,0) [0|0] "" Vector__XXX
 SG_ HVP_packContactorHwFault : 12|1@1+ (1,0) [0|0] "" Vector__XXX
 SG_ HVP_fcContactorHwFault : 13|1@1+ (1,0) [0|0] "" Vector__XXX
 SG_ HVP_supply12vFault : 14|1@1+ (1,0) [0|0] "" Vector__XXX
 SG_ HVP_packVoltageMismatchFault : 15|1@1+ (1,0) [0|0] "" Vector__XXX
 SG_ HVP_crashEvent : 16|1@1+ (1,0) [0|0] "" Vector__XXX
 SG_ HVP_ensMiaFault : 17|1@1+ (1,0) [0|0] "" Vector__XXX
 SG_ HVP_packPositiveCtrArcFault : 18|1@1+ (1,0) [0|0] "" Vector__XXX
 SG_ HVP_packNegativeCtrArcFault : 19|1@1+ (1,0) [0|0] "" Vector__XXX
 SG_ HVP_battery12vDisconnected : 20|1@1+ (1,0) [0|0] "" Vector__XXX
 SG_ HVP_gpoRequestActive : 21|1@1+ (1,0) [0|0] "" Vector__XXX
 SG_ HVP_fastVshFailureFault : 22|1@1+ (1,0) [0|0] "" Vector__XXX
 SG_ HVP_missingConfigBlock : 23|1@1+ (1,0) [0|0] "" Vector__XXX
 SG_ HVP_missingPartNumber : 24|1@1+ (1,0) [0|0] "" Vector__XXX
 SG_ HVP_unsupportedBmbAsicType : 25|1@1+ (1,0) [0|0] "" Vector__XXX
 SG_ HVP_hvilFault : 26|1@1+ (1,0) [0|0] "" Vector__XXX
 SG_ HVP_hvilStatus : 30|2@1+ (1,0) [0|0] "" Vector__XXX
 SG_ HVP_configMajorVersion : 32|8@1+ (1,0) [0|0] "" Vector__XXX
 SG_ HVP_configMinorVersion : 40|8@1+ (1,0) [0|0] "" Vector__XXX
 SG_ HVP_bmbCommunicationFault : 48|1@1+ (1,0) [0|0] "" Vector__XXX
 SG_ HVP_bmbBmbDataIntegrityLossFault : 49|1@1+ (1,0) [0|0] "" Vector__XXX
 SG_ HVP_shuntOverTemperature : 51|1@1+ (1,0) [0|0] "" Vector__XXX
 SG_ HVP_hvpFaultsCounter : 52|4@1+ (1,0) [0|0] "" Vector__XXX
 SG_ HVP_hvpFaultsChecksum : 56|8@1+ (1,0) [0|0] "" Vector__XXX

BO_ 1668 UDS_gtwRequest: 12 Vector__XXX
 SG_ UDS_gtwRequestData : 7|64@0+ (1,0) [0|0] "" Vector__XXX

BO_ 1669 GTW_udsResponse: 12 Vector__XXX
 SG_ GTW_udsResponseData : 7|64@0+ (1,0) [0|0] "" Vector__XXX

BO_ 1673 SCCM_KostiaResponse: 8 Vector__XXX
 SG_ SCCM_KOSTIARespServId : 0|8@1+ (1,0) [0|0] "" Vector__XXX
 SG_ SCCM_KOSTIARespData1 : 8|8@1+ (1,0) [0|0] "" Vector__XXX
 SG_ SCCM_KOSTIARespData2 : 16|8@1+ (1,0) [0|0] "" Vector__XXX
 SG_ SCCM_KOSTIARespData3 : 24|8@1+ (1,0) [0|0] "" Vector__XXX
 SG_ SCCM_KOSTIARespData4 : 32|8@1+ (1,0) [0|0] "" Vector__XXX
 SG_ SCCM_KOSTIARespData5 : 40|8@1+ (1,0) [0|0] "" Vector__XXX
 SG_ SCCM_KOSTIARespData6 : 48|8@1+ (1,0) [0|0] "" Vector__XXX
 SG_ SCCM_KOSTIARespData7 : 56|8@1+ (1,0) [0|0] "" Vector__XXX

BO_ 1680 SCCM_udsResponse: 12 Vector__XXX
 SG_ SCCM_functionalResponseData_0 : 7|8@0+ (1,0) [0|0] "" Vector__XXX
 SG_ SCCM_functionalResponseData_1 : 15|8@0+ (1,0) [0|0] "" Vector__XXX
 SG_ SCCM_functionalResponseData_2 : 23|8@0+ (1,0) [0|0] "" Vector__XXX
 SG_ SCCM_functionalResponseData_3 : 31|8@0+ (1,0) [0|0] "" Vector__XXX
 SG_ SCCM_functionalResponseData_4 : 39|8@0+ (1,0) [0|0] "" Vector__XXX
 SG_ SCCM_functionalResponseData_5 : 47|8@0+ (1,0) [0|0] "" Vector__XXX
 SG_ SCCM_functionalResponseData_6 : 55|8@0+ (1,0) [0|0] "" Vector__XXX
 SG_ SCCM_functionalResponseData_7 : 63|8@0+ (1,0) [0|0] "" Vector__XXX

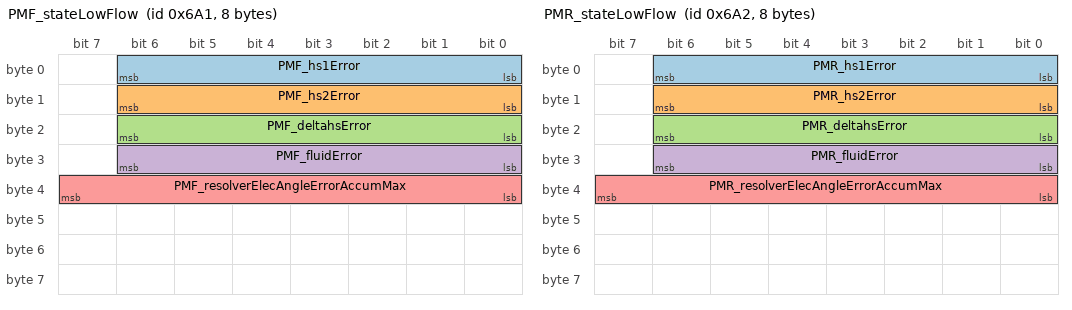
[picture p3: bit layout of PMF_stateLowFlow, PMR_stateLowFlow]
BO_ 1697 PMF_stateLowFlow: 8 Vector__XXX
 SG_ PMF_hs1Error : 0|7@1+ (0.01,0) [0|0] "" Vector__XXX
 SG_ PMF_hs2Error : 8|7@1+ (0.01,0) [0|0] "" Vector__XXX
 SG_ PMF_deltahsError : 16|7@1+ (0.01,0) [0|0] "" Vector__XXX
 SG_ PMF_fluidError : 24|7@1+ (0.01,0) [0|0] "" Vector__XXX
 SG_ PMF_resolverElecAngleErrorAccumMax : 32|8@1+ (0.00196078431372549,0) [0|0] "" Vector__XXX

BO_ 1698 PMR_stateLowFlow: 8 Vector__XXX
 SG_ PMR_hs1Error : 0|7@1+ (0.01,0) [0|0] "" Vector__XXX
 SG_ PMR_hs2Error : 8|7@1+ (0.01,0) [0|0] "" Vector__XXX
 SG_ PMR_deltahsError : 16|7@1+ (0.01,0) [0|0] "" Vector__XXX
 SG_ PMR_fluidError : 24|7@1+ (0.01,0) [0|0] "" Vector__XXX
 SG_ PMR_resolverElecAngleErrorAccumMax : 32|8@1+ (0.00196078431372549,0) [0|0] "" Vector__XXX

BO_ 1723 UDS_sdcrRequest: 12 Vector__XXX
 SG_ UDS_sdcrRequestData : 7|64@0+ (1,0) [0|0] "" Vector__XXX

BO_ 1734 UDS_ptcRequest: 12 Vector__XXX
 SG_ UDS_ptcRequestData : 7|64@0+ (1,0) [0|0] "" Vector__XXX

BO_ 1736 EPBL_statsOutput: 8 Vector__XXX
 SG_ EPBL_statsOutputIndex M : 0|2@1+ (1,0) [0|0] "" Vector__XXX
 SG_ EPBL_staticApplyCounts m0 : 2|20@1+ (1,0) [0|0] "" Vector__XXX
 SG_ EPBL_dynamicApplyCounts m1 : 8|32@1+ (1,0) [0|0] "" Vector__XXX
 SG_ EPBL_staticApplyCountsCold m0 : 24|20@1+ (1,0) [0|0] "" Vector__XXX
 SG_ EPBL_staticApplyCountsVeryCold m0 : 44|20@1+ (1,0) [0|0] "" Vector__XXX

BO_ 1748 PMR_info: 8 Vector__XXX
 SG_ PMR_infoIndex M : 0|8@1+ (1,0) [0|0] "" Vector__XXX
 SG_ PMR_appGitHash m17 : 8|56@1+ (1,0) [0|0] "" Vector__XXX
 SG_ PMR_bootGitHash m18 : 8|56@1+ (1,0) [0|0] "" Vector__XXX
 SG_ PMR_buildType m10 : 8|8@1+ (1,0) [0|0] "" Vector__XXX
 SG_ PMR_diNodeBuildType m21 : 8|8@1+ (1,0) [0|0] "" Vector__XXX
 SG_ PMR_platformTyp m19 : 8|8@1+ (1,0) [0|0] "" Vector__XXX
 SG_ PMR_udsProtocolVersion m20 : 8|8@1+ (1,0) [0|0] "" Vector__XXX
 SG_ PMR_buildConfigurationId m10 : 16|16@1+ (1,0) [0|0] "" Vector__XXX
 SG_ PMR_diNodeBuildConfigurationId m21 : 16|16@1+ (1,0) [0|0] "" Vector__XXX
 SG_ PMR_pcbaId m11 : 16|8@1+ (1,0) [0|0] "" Vector__XXX
 SG_ PMR_assemblyId m11 : 24|8@1+ (1,0) [0|0] "" Vector__XXX
 SG_ PMR_applicationCrc m13 : 32|32@1+ (1,0) [0|0] "" Vector__XXX
 SG_ PMR_bootloaderCrc m20 : 32|32@1+ (1,0) [0|0] "" Vector__XXX
 SG_ PMR_diNodeApplicationCrc m21 : 32|32@1+ (1,0) [0|0] "" Vector__XXX
 SG_ PMR_hardwareId m10 : 32|8@1+ (1,0) [0|0] "" Vector__XXX
 SG_ PMR_usageId m11 : 32|16@1+ (1,0) [0|0] "" Vector__XXX
 SG_ PMR_componentId m10 : 48|16@1+ (1,0) [0|0] "" Vector__XXX
 SG_ PMR_subUsageId m11 : 48|16@1+ (1,0) [0|0] "" Vector__XXX

BO_ 1750 PTC_udsResponse: 12 Vector__XXX
 SG_ PTC_udsResponseData : 7|64@0+ (1,0) [0|0] "" Vector__XXX

BO_ 1766 PNCD_IsoTpPipeToCp: 8 Vector__XXX
 SG_ PNCD_isoTpToCpData : 0|64@1+ (1,0) [0|0] "" Vector__XXX

BO_ 1767 CP_IsoTpPipeToPncd: 8 Vector__XXX
 SG_ CP_isoTpToPncdData : 0|64@1+ (1,0) [0|0] "" Vector__XXX

BO_ 1768 EPBR_statsOutput: 8 Vector__XXX
 SG_ EPBR_statsOutputIndex M : 0|2@1+ (1,0) [0|0] "" Vector__XXX
 SG_ EPBR_staticApplyCounts m0 : 2|20@1+ (1,0) [0|0] "" Vector__XXX
 SG_ EPBR_dynamicApplyCounts m1 : 8|32@1+ (1,0) [0|0] "" Vector__XXX
 SG_ EPBR_staticApplyCountsCold m0 : 24|20@1+ (1,0) [0|0] "" Vector__XXX
 SG_ EPBR_staticApplyCountsVeryCold m0 : 44|20@1+ (1,0) [0|0] "" Vector__XXX

BO_ 1787 SDCR_udsResponse: 12 Vector__XXX
 SG_ SDCR_udsResponseData : 7|64@0+ (1,0) [0|0] "" Vector__XXX

BO_ 1793 VCFRONT_debugThermal10Hz: 8 Vector__XXX
 SG_ VCFRONT_debugThermal10HzIndex M : 0|3@1+ (1,0) [0|0] "" Vector__XXX
 SG_ VCFRONT_activeLouverMotorKt m5 : 3|10@1+ (0.5,0) [0|0] "" Vector__XXX
 SG_ VCFRONT_chillerExvCount m6 : 3|10@1- (4,0) [0|0] "" Vector__XXX
 SG_ VCFRONT_coolantValveAtTarget m2 : 3|1@1+ (1,0) [0|0] "" Vector__XXX
 SG_ VCFRONT_exvMotorIsEnabled m4 : 3|1@1+ (1,0) [0|0] "" Vector__XXX
 SG_ VCFRONT_coolantValveMotorCounts m2 : 4|11@1+ (1,-1000) [0|0] "" Vector__XXX
 SG_ VCFRONT_exvMotorIsMoving m4 : 4|1@1+ (1,0) [0|0] "" Vector__XXX
 SG_ VCFRONT_exvMotorDirection m4 : 5|1@1+ (1,0) [0|0] "" Vector__XXX
 SG_ VCFRONT_exvMotorWasHardReset m4 : 6|1@1+ (1,0) [0|0] "" Vector__XXX
 SG_ VCFRONT_exvMotorThermalWarn m4 : 7|1@1+ (1,0) [0|0] "" Vector__XXX
 SG_ VCFRONT_exvMotorThermalShutdown m4 : 8|1@1+ (1,0) [0|0] "" Vector__XXX
 SG_ VCFRONT_pumpBatteryOutputDuty m0 : 8|7@1+ (1,0) [0|0] "" Vector__XXX
 SG_ VCFRONT_pumpPowertrainOutputDuty m1 : 8|7@1+ (1,0) [0|0] "" Vector__XXX
 SG_ VCFRONT_radiatorFanOutputDuty m3 : 8|7@1+ (1,0) [0|0] "" Vector__XXX
 SG_ VCFRONT_exvMotorIsCoilOpenX m4 : 9|1@1+ (1,0) [0|0] "" Vector__XXX
 SG_ VCFRONT_exvMotorIsCoilOpenY m4 : 10|1@1+ (1,0) [0|0] "" Vector__XXX
 SG_ VCFRONT_exvMotorIsCoilShortXPGnd m4 : 11|1@1+ (1,0) [0|0] "" Vector__XXX
 SG_ VCFRONT_exvMotorIsCoilShortXPVbb m4 : 12|1@1+ (1,0) [0|0] "" Vector__XXX
 SG_ VCFRONT_evapExvCount m6 : 13|10@1- (4,0) [0|0] "" Vector__XXX
 SG_ VCFRONT_exvMotorIsCoilShortXNGnd m4 : 13|1@1+ (1,0) [0|0] "" Vector__XXX
 SG_ VCFRONT_exvMotorIsCoilShortXNVbb m4 : 14|1@1+ (1,0) [0|0] "" Vector__XXX
 SG_ VCFRONT_coolantValveUnderTravel m2 : 15|1@1+ (1,0) [0|0] "" Vector__XXX
 SG_ VCFRONT_exvMotorIsCoilShortYPGnd m4 : 15|1@1+ (1,0) [0|0] "" Vector__XXX
 SG_ VCFRONT_activeLouverMotorSpeed m5 : 16|16@1+ (0.1,0.1) [0|0] "" Vector__XXX
 SG_ VCFRONT_coolantValveOverTravel m2 : 16|1@1+ (1,0) [0|0] "" Vector__XXX
 SG_ VCFRONT_exvMotorIsCoilShortYPVbb m4 : 16|1@1+ (1,0) [0|0] "" Vector__XXX
 SG_ VCFRONT_pumpBatteryITerm m0 : 16|8@1+ (0.005,-0.6) [0|0] "" Vector__XXX
 SG_ VCFRONT_pumpPowertrainITerm m1 : 16|8@1+ (0.005,-0.6) [0|0] "" Vector__XXX
 SG_ VCFRONT_radiatorFanITerm m3 : 16|8@1+ (0.025,-1.5) [0|0] "" Vector__XXX
 SG_ VCFRONT_coolantValveNoTravel m2 : 17|1@1+ (1,0) [0|0] "" Vector__XXX
 SG_ VCFRONT_exvMotorIsCoilShortYNGnd m4 : 17|1@1+ (1,0) [0|0] "" Vector__XXX
 SG_ VCFRONT_coolantValveStall m2 : 18|1@1+ (1,0) [0|0] "" Vector__XXX
 SG_ VCFRONT_exvMotorIsCoilShortYNVbb m4 : 18|1@1+ (1,0) [0|0] "" Vector__XXX
 SG_ VCFRONT_coolantFlowBatMax m2 : 19|9@1+ (0.1,0) [0|0] "" Vector__XXX
 SG_ VCFRONT_exvMotorHasCommError m4 : 19|1@1+ (1,0) [0|0] "" Vector__XXX
 SG_ VCFRONT_solenoidEvapPowerApplied m4 : 20|1@1+ (1,0) [0|0] "" Vector__XXX
 SG_ VCFRONT_pumpBatteryFault m0 : 24|1@1+ (1,0) [0|0] "" Vector__XXX
 SG_ VCFRONT_pumpPowertrainFault m1 : 24|1@1+ (1,0) [0|0] "" Vector__XXX
 SG_ VCFRONT_radiatorFanFault m3 : 24|1@1+ (1,0) [0|0] "" Vector__XXX
 SG_ VCFRONT_recircExvCount m6 : 24|10@1- (4,0) [0|0] "" Vector__XXX
 SG_ VCFRONT_activeLouverAutoDetCur1 m3 : 25|7@1+ (5,0) [0|0] "" Vector__XXX
 SG_ VCFRONT_coolantNoFlowReqBat m2 : 28|1@1+ (1,0) [0|0] "" Vector__XXX
 SG_ VCFRONT_coolantNoFlowFaultBat m2 : 29|1@1+ (1,0) [0|0] "" Vector__XXX
 SG_ VCFRONT_coolantFlowPTMax m2 : 30|9@1+ (0.1,0) [0|0] "" Vector__XXX
 SG_ VCFRONT_activeLouverAutoDetCur2 m3 : 32|7@1+ (5,0) [0|0] "" Vector__XXX
 SG_ VCFRONT_activeLouverMotorCurrent m5 : 32|10@1- (5,0) [0|0] "" Vector__XXX
 SG_ VCFRONT_lccExvCount m6 : 34|10@1- (4,0) [0|0] "" Vector__XXX
 SG_ VCFRONT_coolantNoFlowReqPT m2 : 39|1@1+ (1,0) [0|0] "" Vector__XXX
 SG_ VCFRONT_activeLouverAutoDetCur3 m3 : 40|7@1+ (5,0) [0|0] "" Vector__XXX
 SG_ VCFRONT_coolantNoFlowFaultPT m2 : 40|1@1+ (1,0) [0|0] "" Vector__XXX
 SG_ VCFRONT_ccLeftExvCount m6 : 44|10@1- (4,0) [0|0] "" Vector__XXX
 SG_ VCFRONT_ccRightExvCount m6 : 54|10@1- (4,0) [0|0] "" Vector__XXX

BO_ 1795 VCRIGHT_debugThermal10Hz: 8 Vector__XXX
 SG_ VCRIGHT_debugThermal10HzIndex M : 0|4@1+ (1,0) [0|0] "" Vector__XXX
 SG_ VCRIGHT_hvacLHBleedCalibrated m4 : 4|1@1+ (1,0) [0|0] "" Vector__XXX
 SG_ VCRIGHT_wattsDemandEvapFeedback m0 : 4|9@1- (20,0) [0|0] "" Vector__XXX
 SG_ VCRIGHT_hvacRHBleedCalibrated m4 : 5|1@1+ (1,0) [0|0] "" Vector__XXX
 SG_ VCRIGHT_hvacLHVaneCalibrated m4 : 6|1@1+ (1,0) [0|0] "" Vector__XXX
 SG_ VCRIGHT_hvacRHVaneCalibrated m4 : 7|1@1+ (1,0) [0|0] "" Vector__XXX
 SG_ VCRIGHT_LHVaneTargetIntermediate m9 : 8|8@1+ (0.4,0) [0|0] "" Vector__XXX
 SG_ VCRIGHT_PTCcenterPowerLeft m5 : 8|6@1+ (30,0) [0|0] "" Vector__XXX
 SG_ VCRIGHT_PTCcenterStoneTempLeft m6 : 8|8@1+ (2,-70) [0|0] "" Vector__XXX
 SG_ VCRIGHT_PTCouterStoneTempLeft m7 : 8|8@1+ (2,-70) [0|0] "" Vector__XXX
 SG_ VCRIGHT_PTCouterStoneTempRight m8 : 8|8@1+ (2,-70) [0|0] "" Vector__XXX
 SG_ VCRIGHT_hvacPanelFloorSplitRow1 m2 : 8|8@1+ (0.4,0) [0|0] "" Vector__XXX
 SG_ VCRIGHT_hvacUpperModeCalibrated m4 : 8|1@1+ (1,0) [0|0] "" Vector__XXX
 SG_ VCRIGHT_setTempAdjustmentLeft m3 : 8|7@1+ (0.1,0) [0|0] "" Vector__XXX
 SG_ VCRIGHT_tempEvapAdjustmentLeft m1 : 8|7@1+ (0.1,0) [0|0] "" Vector__XXX
 SG_ VCRIGHT_hvacLowerModeCalibrated m4 : 9|1@1+ (1,0) [0|0] "" Vector__XXX
 SG_ VCRIGHT_hvacIntakeCalibrated m4 : 10|1@1+ (1,0) [0|0] "" Vector__XXX
 SG_ VCRIGHT_hvacActuatorsCalibrated m4 : 12|1@1+ (1,0) [0|0] "" Vector__XXX
 SG_ VCRIGHT_wattsDemandEvapFeedfwd m0 : 13|9@1+ (20,0) [0|0] "" Vector__XXX
 SG_ VCRIGHT_PTCcenterStoneTempRight m6 : 16|8@1+ (2,-70) [0|0] "" Vector__XXX
 SG_ VCRIGHT_PTCouterPowerLeft m5 : 16|6@1+ (30,0) [0|0] "" Vector__XXX
 SG_ VCRIGHT_PTCouterRodTempLeft m7 : 16|8@1+ (2,-70) [0|0] "" Vector__XXX
 SG_ VCRIGHT_PTCouterRodTempRight m8 : 16|8@1+ (2,-70) [0|0] "" Vector__XXX
 SG_ VCRIGHT_RHVaneTargetIntermediate m9 : 16|8@1+ (0.4,0) [0|0] "" Vector__XXX
 SG_ VCRIGHT_hvacDefrostPercent m2 : 16|8@1+ (0.4,0) [0|0] "" Vector__XXX
 SG_ VCRIGHT_setTempAdjustmentRight m3 : 16|7@1+ (0.1,0) [0|0] "" Vector__XXX
 SG_ VCRIGHT_tempEvapAdjustmentRight m1 : 16|7@1+ (0.1,0) [0|0] "" Vector__XXX
 SG_ VCRIGHT_wattsHeaterLeftFeedback m0 : 22|9@1- (20,0) [0|0] "" Vector__XXX
 SG_ VCRIGHT_driverPresentBuckled m1 : 23|1@1+ (1,0) [0|0] "" Vector__XXX
 SG_ VCRIGHT_LHBleedTargetIntermediate m9 : 24|8@1+ (0.4,0) [0|0] "" Vector__XXX
 SG_ VCRIGHT_PTCinnerPowerLeft m5 : 24|6@1+ (30,0) [0|0] "" Vector__XXX
 SG_ VCRIGHT_PTCinnerStoneTempLeft m6 : 24|8@1+ (2,-70) [0|0] "" Vector__XXX
 SG_ VCRIGHT_PTCouterAirTempLeft m7 : 24|8@1+ (2,-70) [0|0] "" Vector__XXX
 SG_ VCRIGHT_PTCouterAirTempRight m8 : 24|8@1+ (2,-70) [0|0] "" Vector__XXX
 SG_ VCRIGHT_hvacLHVaneVelocity m3 : 24|8@1- (0.8,0) [0|0] "" Vector__XXX
 SG_ VCRIGHT_hvacRow2Percent m2 : 24|8@1+ (0.4,0) [0|0] "" Vector__XXX
 SG_ VCRIGHT_passengerPresentBuckled m1 : 24|1@1+ (1,0) [0|0] "" Vector__XXX
 SG_ VCRIGHT_frontSeatLeftHeatDutyFiltered m1 : 25|5@1+ (1,0) [0|0] "" Vector__XXX
 SG_ VCRIGHT_wattsHeaterLeftFeedfwd m0 : 31|9@1+ (20,0) [0|0] "" Vector__XXX
 SG_ VCRIGHT_PTCcenterPowerRight m5 : 32|6@1+ (30,0) [0|0] "" Vector__XXX
 SG_ VCRIGHT_PTCcenterRodTempLeft m7 : 32|8@1+ (2,-70) [0|0] "" Vector__XXX
 SG_ VCRIGHT_PTCcenterRodTempRight m8 : 32|8@1+ (2,-70) [0|0] "" Vector__XXX
 SG_ VCRIGHT_PTCinnerStoneTempRight m6 : 32|8@1+ (2,-70) [0|0] "" Vector__XXX
 SG_ VCRIGHT_RHBleedTargetIntermediate m9 : 32|8@1+ (0.4,0) [0|0] "" Vector__XXX
 SG_ VCRIGHT_frontSeatRightHeatDutyFiltered m1 : 32|5@1+ (1,0) [0|0] "" Vector__XXX
 SG_ VCRIGHT_hvacPanelFloorSplitRow2 m2 : 32|8@1+ (0.4,0) [0|0] "" Vector__XXX
 SG_ VCRIGHT_hvacRHVaneVelocity m3 : 32|8@1- (0.8,0) [0|0] "" Vector__XXX
 SG_ VCRIGHT_PTCinnerRodTempLeft m7 : 40|8@1+ (2,-70) [0|0] "" Vector__XXX
 SG_ VCRIGHT_PTCinnerRodTempRight m8 : 40|8@1+ (2,-70) [0|0] "" Vector__XXX
 SG_ VCRIGHT_PTCouterPowerRight m5 : 40|6@1+ (30,0) [0|0] "" Vector__XXX
 SG_ VCRIGHT_hvacFreshMassCounter m2 : 40|12@1+ (10,0) [0|0] "" Vector__XXX
 SG_ VCRIGHT_hvacVehicleSpeed m3 : 40|5@1+ (5,0) [0|0] "" Vector__XXX
 SG_ VCRIGHT_wattsHeaterRightFeedback m0 : 40|9@1- (20,0) [0|0] "" Vector__XXX
 SG_ VCRIGHT_hvacMassflowCompensated m3 : 47|8@1+ (1.5,0) [0|0] "" Vector__XXX
 SG_ VCRIGHT_PTCcenterAirTempLeft m7 : 48|8@1+ (2,-70) [0|0] "" Vector__XXX
 SG_ VCRIGHT_PTCcenterAirTempRight m8 : 48|8@1+ (2,-70) [0|0] "" Vector__XXX
 SG_ VCRIGHT_PTCinnerPowerRight m5 : 48|6@1+ (30,0) [0|0] "" Vector__XXX
 SG_ VCRIGHT_wattsHeaterRightFeedfwd m0 : 49|9@1+ (20,0) [0|0] "" Vector__XXX
 SG_ VCRIGHT_hvacRecircMassCounter m2 : 52|12@1+ (10,0) [0|0] "" Vector__XXX
 SG_ VCRIGHT_PTCinnerAirTempLeft m7 : 56|8@1+ (2,-70) [0|0] "" Vector__XXX
 SG_ VCRIGHT_PTCinnerAirTempRight m8 : 56|8@1+ (2,-70) [0|0] "" Vector__XXX

BO_ 1796 XCP_pmrRequest: 12 Vector__XXX
 SG_ XCP_pmrRequestData : 7|64@0+ (1,0) [0|0] "" Vector__XXX

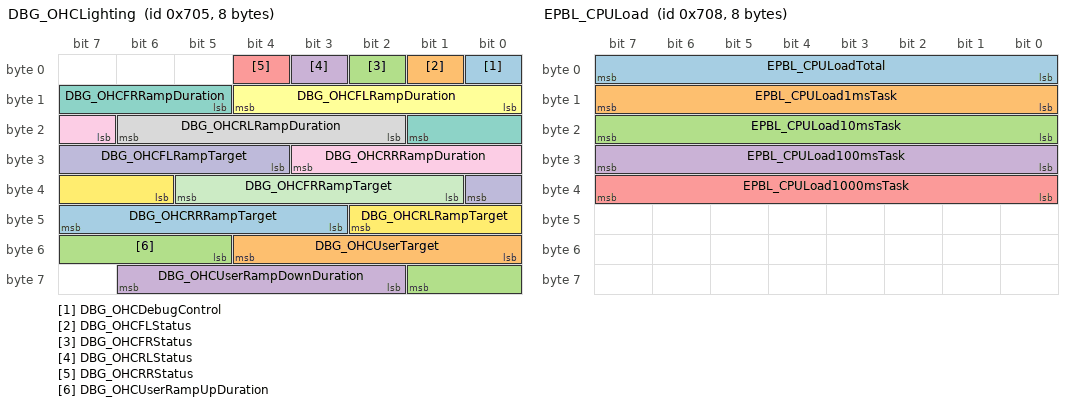
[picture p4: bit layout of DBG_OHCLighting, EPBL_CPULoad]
BO_ 1797 DBG_OHCLighting: 8 Vector__XXX
 SG_ DBG_OHCDebugControl : 0|1@1+ (1,0) [0|0] "" Vector__XXX
 SG_ DBG_OHCFLStatus : 1|1@1+ (1,0) [0|0] "" Vector__XXX
 SG_ DBG_OHCFRStatus : 2|1@1+ (1,0) [0|0] "" Vector__XXX
 SG_ DBG_OHCRLStatus : 3|1@1+ (1,0) [0|0] "" Vector__XXX
 SG_ DBG_OHCRRStatus : 4|1@1+ (1,0) [0|0] "" Vector__XXX
 SG_ DBG_OHCFLRampDuration : 8|5@1+ (0.25,0.25) [0|0] "" Vector__XXX
 SG_ DBG_OHCFRRampDuration : 13|5@1+ (0.25,0.25) [0|0] "" Vector__XXX
 SG_ DBG_OHCRLRampDuration : 18|5@1+ (0.25,0.25) [0|0] "" Vector__XXX
 SG_ DBG_OHCRRRampDuration : 23|5@1+ (0.25,0.25) [0|0] "" Vector__XXX
 SG_ DBG_OHCFLRampTarget : 28|5@1+ (5,0) [0|0] "" Vector__XXX
 SG_ DBG_OHCFRRampTarget : 33|5@1+ (5,0) [0|0] "" Vector__XXX
 SG_ DBG_OHCRLRampTarget : 38|5@1+ (5,0) [0|0] "" Vector__XXX
 SG_ DBG_OHCRRRampTarget : 43|5@1+ (5,0) [0|0] "" Vector__XXX
 SG_ DBG_OHCUserTarget : 48|5@1+ (5,0) [0|0] "" Vector__XXX
 SG_ DBG_OHCUserRampUpDuration : 53|5@1+ (0.25,0.25) [0|0] "" Vector__XXX
 SG_ DBG_OHCUserRampDownDuration : 58|5@1+ (0.25,0.25) [0|0] "" Vector__XXX

BO_ 1798 XCP_dirRequest: 12 Vector__XXX
 SG_ XCP_dirRequestData : 7|64@0+ (1,0) [0|0] "" Vector__XXX

BO_ 1799 DBG_intrusionSensor: 8 Vector__XXX
 SG_ DBG_IS_USS_Operation : 0|3@1+ (1,0) [0|0] "" Vector__XXX
 SG_ DBG_IS_Air_Conditioned : 3|1@1+ (1,0) [0|0] "" Vector__XXX
 SG_ DBG_IS_Heater : 4|1@1+ (1,0) [0|0] "" Vector__XXX
 SG_ DBG_IS_Window : 5|1@1+ (1,0) [0|0] "" Vector__XXX
 SG_ DBG_IS_Reserved_01 : 6|1@1+ (1,0) [0|0] "" Vector__XXX
 SG_ DBG_IS_Suspensions : 7|1@1+ (1,0) [0|0] "" Vector__XXX
 SG_ DBG_IS_Vehicles_Settings : 8|4@1+ (1,0) [0|0] "" Vector__XXX
 SG_ DBG_IS_Reserved_02 : 12|1@1+ (1,0) [0|0] "" Vector__XXX
 SG_ DBG_IS_Reserved_03 : 13|1@1+ (1,0) [0|0] "" Vector__XXX
 SG_ DBG_IS_Reserved_04 : 14|1@1+ (1,0) [0|0] "" Vector__XXX
 SG_ DBG_IS_Reserved_05 : 15|1@1+ (1,0) [0|0] "" Vector__XXX
 SG_ DBG_IS_Siren_Alarm : 16|1@1+ (1,0) [0|0] "" Vector__XXX
 SG_ DBG_IS_Siren_Beep_Type : 17|2@1+ (1,0) [0|0] "" Vector__XXX
 SG_ DBG_IS_Siren_Beep_Duration : 19|2@1+ (1,0) [0|0] "" Vector__XXX
 SG_ DBG_IS_Siren_Tone : 21|1@1+ (1,0) [0|0] "" Vector__XXX
 SG_ DBG_IS_Siren_Alarm_Cycles : 22|1@1+ (1,0) [0|0] "" Vector__XXX
 SG_ DBG_IS_Reserved_06 : 23|1@1+ (1,0) [0|0] "" Vector__XXX

BO_ 1800 EPBL_CPULoad: 8 Vector__XXX
 SG_ EPBL_CPULoadTotal : 0|8@1+ (1,0) [0|0] "" Vector__XXX
 SG_ EPBL_CPULoad1msTask : 8|8@1+ (1,0) [0|0] "" Vector__XXX
 SG_ EPBL_CPULoad10msTask : 16|8@1+ (1,0) [0|0] "" Vector__XXX
 SG_ EPBL_CPULoad100msTask : 24|8@1+ (1,0) [0|0] "" Vector__XXX
 SG_ EPBL_CPULoad1000msTask : 32|8@1+ (1,0) [0|0] "" Vector__XXX

BO_ 1801 VCFRONT_logging0point1Hz: 8 Vector__XXX
 SG_ VCFRONT_logging0point1HzIndex M : 0|6@1+ (1,0) [0|0] "" Vector__XXX
 SG_ VCFRONT_rightFrontFogLightCurrent m0 : 6|9@1+ (0.002,0) [0|0] "" Vector__XXX
 SG_ VC_hcmlFactoryOfOrigin m26 : 6|2@1+ (1,0) [0|0] "" Vector__XXX
 SG_ VC_hcmrFactoryOfOrigin m27 : 6|2@1+ (1,0) [0|0] "" Vector__XXX
 SG_ VC_leftHeadlampAimedVerticalPosition m4 : 6|10@1+ (1,0) [0|0] "" Vector__XXX
 SG_ VC_leftHeadlampCurrentVerticalPosition m3 : 6|10@1+ (1,0) [0|0] "" Vector__XXX
 SG_ VC_leftHeadlampMigrationState m20 : 6|2@1+ (1,0) [0|0] "" Vector__XXX
 SG_ VCFRONT_HCML_lowBeamSpotTemp m1 : 8|8@1- (1,67) [0|0] "" Vector__XXX
 SG_ VCFRONT_HCMR_lowBeamSpotTemp m2 : 8|8@1- (1,67) [0|0] "" Vector__XXX
 SG_ VCFRONT_PdFailureConfidence m23 : 8|7@1+ (1,0) [0|0] "" Vector__XXX
 SG_ VCFRONT_cclEXVCountClosOvDrv m14 : 8|15@1+ (500,0) [0|0] "" Vector__XXX
 SG_ VCFRONT_cclEXVCountFirstOpen m13 : 8|15@1+ (100,0) [0|0] "" Vector__XXX
 SG_ VCFRONT_cclEXVCountTotalDist m19 : 8|20@1+ (15000,0) [0|0] "" Vector__XXX
 SG_ VCFRONT_ccrEXVCountClosOvDrv m16 : 8|15@1+ (500,0) [0|0] "" Vector__XXX
 SG_ VCFRONT_ccrEXVCountFirstOpen m15 : 8|15@1+ (100,0) [0|0] "" Vector__XXX
 SG_ VCFRONT_chillerEXVCountClosOvDrv m6 : 8|15@1+ (500,0) [0|0] "" Vector__XXX
 SG_ VCFRONT_chillerEXVCountFirstOpen m5 : 8|15@1+ (100,0) [0|0] "" Vector__XXX
 SG_ VCFRONT_chillerEXVCountTotalDist m17 : 8|20@1+ (15000,0) [0|0] "" Vector__XXX
 SG_ VCFRONT_chillerEXVType m25 : 8|3@1+ (1,0) [0|0] "" Vector__XXX
 SG_ VCFRONT_compOnOffCycles m28 : 8|16@1+ (10,0) [0|0] "" Vector__XXX
 SG_ VCFRONT_evapEXVCountClosOvDrv m8 : 8|15@1+ (500,0) [0|0] "" Vector__XXX
 SG_ VCFRONT_evapEXVCountFirstOpen m7 : 8|15@1+ (100,0) [0|0] "" Vector__XXX
 SG_ VCFRONT_hazardLightRequestDebug m22 : 8|4@1+ (1,0) [0|0] "" Vector__XXX
 SG_ VCFRONT_lccEXVCountClosOvDrv m12 : 8|15@1+ (500,0) [0|0] "" Vector__XXX
 SG_ VCFRONT_lccEXVCountFirstOpen m11 : 8|15@1+ (100,0) [0|0] "" Vector__XXX
 SG_ VCFRONT_leftHeadlampPowerBitResetCounter m21 : 8|8@1+ (1,0) [0|0] "" Vector__XXX
 SG_ VCFRONT_recircEXVCountClosOvDrv m10 : 8|15@1+ (500,0) [0|0] "" Vector__XXX
 SG_ VCFRONT_recircEXVCountFirstOpen m9 : 8|15@1+ (100,0) [0|0] "" Vector__XXX
 SG_ VCFRONT_recircEXVCountTotalDist m18 : 8|20@1+ (15000,0) [0|0] "" Vector__XXX
 SG_ VCFRONT_recircExvFailureConfidence m24 : 8|7@1+ (1,0) [0|0] "" Vector__XXX
 SG_ VC_hcmlHellaPartNumberStatus m26 : 8|1@1+ (1,0) [0|0] "" Vector__XXX
 SG_ VC_hcmrHellaPartNumberStatus m27 : 8|1@1+ (1,0) [0|0] "" Vector__XXX
 SG_ VC_rightHeadlampMigrationState m20 : 8|2@1+ (1,0) [0|0] "" Vector__XXX
 SG_ VC_hcmlHellaPartNumber m26 : 9|32@1+ (1,0) [0|0] "" Vector__XXX
 SG_ VC_hcmrHellaPartNumber m27 : 9|32@1+ (1,0) [0|0] "" Vector__XXX
 SG_ VC_leftHeadlampUsableRange m20 : 10|10@1+ (1,0) [0|0] "" Vector__XXX
 SG_ VCFRONT_evapEXVType m25 : 11|3@1+ (1,0) [0|0] "" Vector__XXX
 SG_ VCFRONT_leftHeadlampLBSpotInstantFaultCounter m22 : 12|4@1+ (1,0) [0|0] "" Vector__XXX
 SG_ VCFRONT_PsFailureConfidence m23 : 15|7@1+ (1,0) [0|0] "" Vector__XXX
 SG_ VCFRONT_compressorFailureConfidence m24 : 15|7@1+ (1,0) [0|0] "" Vector__XXX
 SG_ VCFRONT_HCML_highBeamTemp m1 : 16|8@1- (1,67) [0|0] "" Vector__XXX
 SG_ VCFRONT_HCMR_highBeamTemp m2 : 16|8@1- (1,67) [0|0] "" Vector__XXX
 SG_ VCFRONT_leftHeadlampCrcFaultCounter m21 : 16|8@1+ (1,0) [0|0] "" Vector__XXX
 SG_ VCFRONT_leftHeadlampLBSpotDebouncedFaultCounter m22 : 16|3@1+ (1,0) [0|0] "" Vector__XXX
 SG_ VCFRONT_recircEXVType m25 : 16|3@1+ (1,0) [0|0] "" Vector__XXX
 SG_ VCFRONT_rightFrontFogLightCurrentSenseState m0 : 16|3@1+ (1,0) [0|0] "" Vector__XXX
 SG_ VC_leftHeadlampCurrentHorizontalPosition m3 : 16|10@1+ (1,0) [0|0] "" Vector__XXX
 SG_ VC_rightHeadlampAimedVerticalPosition m4 : 16|10@1+ (1,0) [0|0] "" Vector__XXX
 SG_ VCFRONT_lccEXVType m25 : 19|3@1+ (1,0) [0|0] "" Vector__XXX
 SG_ VCFRONT_leftHeadlampLBWideInstantFaultCounter m22 : 19|4@1+ (1,0) [0|0] "" Vector__XXX
 SG_ VCFRONT_rightSideRepeaterLightCurrent m0 : 19|7@1+ (0.002,0) [0|0] "" Vector__XXX
 SG_ VC_rightHeadlampUsableRange m20 : 20|10@1+ (1,0) [0|0] "" Vector__XXX
 SG_ VCFRONT_PlFailureConfidence m23 : 22|7@1+ (1,0) [0|0] "" Vector__XXX
 SG_ VCFRONT_cclExvFailureConfidence m24 : 22|7@1+ (1,0) [0|0] "" Vector__XXX
 SG_ VCFRONT_HCML_turnTemp m1 : 24|8@1- (1,67) [0|0] "" Vector__XXX
 SG_ VCFRONT_HCMR_turnTemp m2 : 24|8@1- (1,67) [0|0] "" Vector__XXX
 SG_ VCFRONT_activeLouverType m6 : 24|2@1+ (1,0) [0|0] "" Vector__XXX
 SG_ VCFRONT_cclEXVCountDirecChan m13 : 24|13@1+ (2000,0) [0|0] "" Vector__XXX
 SG_ VCFRONT_cclEXVType m25 : 24|3@1+ (1,0) [0|0] "" Vector__XXX
 SG_ VCFRONT_ccrEXVCountDirecChan m15 : 24|13@1+ (2000,0) [0|0] "" Vector__XXX
 SG_ VCFRONT_chillerEXVCountDirecChan m5 : 24|13@1+ (2000,0) [0|0] "" Vector__XXX
 SG_ VCFRONT_compHoursOn m28 : 24|17@1+ (1,0) [0|0] "" Vector__XXX
 SG_ VCFRONT_evapEXVCountDirecChan m7 : 24|13@1+ (2000,0) [0|0] "" Vector__XXX
 SG_ VCFRONT_lccEXVCountDirecChan m11 : 24|13@1+ (2000,0) [0|0] "" Vector__XXX
 SG_ VCFRONT_leftHeadlampCommFaultCounter m21 : 24|8@1+ (1,0) [0|0] "" Vector__XXX
 SG_ VCFRONT_leftHeadlampLBWideDebouncedFaultCounter m22 : 24|3@1+ (1,0) [0|0] "" Vector__XXX
 SG_ VCFRONT_minutesSinceAccDeviceConnectedWhileIdle m12 : 24|16@1+ (1,0) [0|0] "" Vector__XXX
 SG_ VCFRONT_recircEXVCountDirecChan m9 : 24|13@1+ (2000,0) [0|0] "" Vector__XXX
 SG_ VCFRONT_rightSideRepeaterLightCurrentSenseState m0 : 26|3@1+ (1,0) [0|0] "" Vector__XXX
 SG_ VC_leftHeadlampAimedHorizontalPosition m4 : 26|10@1+ (1,0) [0|0] "" Vector__XXX
 SG_ VC_rightHeadlampCurrentVerticalPosition m3 : 26|10@1+ (1,0) [0|0] "" Vector__XXX
 SG_ VCFRONT_ccrEXVType m25 : 27|3@1+ (1,0) [0|0] "" Vector__XXX
 SG_ VCFRONT_rightHeadlampLBSpotInstantFaultCounter m22 : 27|4@1+ (1,0) [0|0] "" Vector__XXX
 SG_ VCFRONT_ccrEXVCountTotalDist m19 : 28|20@1+ (15000,0) [0|0] "" Vector__XXX
 SG_ VCFRONT_evapEXVCountTotalDist m17 : 28|20@1+ (15000,0) [0|0] "" Vector__XXX
 SG_ VCFRONT_lccEXVCountTotalDist m18 : 28|20@1+ (15000,0) [0|0] "" Vector__XXX
 SG_ VCFRONT_TdFailureConfidence m23 : 29|7@1+ (1,0) [0|0] "" Vector__XXX
 SG_ VCFRONT_ccrExvFailureConfidence m24 : 29|7@1+ (1,0) [0|0] "" Vector__XXX
 SG_ VCFRONT_leftFrontFogLightCurrent m0 : 29|9@1+ (0.002,0) [0|0] "" Vector__XXX
 SG_ VCFRONT_HCML_bladeTemp m1 : 32|8@1- (1,67) [0|0] "" Vector__XXX
 SG_ VCFRONT_HCMR_bladeTemp m2 : 32|8@1- (1,67) [0|0] "" Vector__XXX
 SG_ VCFRONT_coolantValveOdometer m25 : 32|13@1+ (2000,0) [0|0] "" Vector__XXX
 SG_ VCFRONT_rightHeadlampLBSpotDebouncedFaultCounter m22 : 32|3@1+ (1,0) [0|0] "" Vector__XXX
 SG_ VCFRONT_rightHeadlampPowerBitResetCounter m21 : 32|8@1+ (1,0) [0|0] "" Vector__XXX
 SG_ VC_leftHeadlampPositionState m20 : 32|3@1+ (1,0) [0|0] "" Vector__XXX
 SG_ VCFRONT_rightHeadlampLBWideInstantFaultCounter m22 : 35|4@1+ (1,0) [0|0] "" Vector__XXX
 SG_ VC_leftHeadlampPositionSubState m20 : 35|4@1+ (1,0) [0|0] "" Vector__XXX
 SG_ VCFRONT_TsFailureConfidence m23 : 36|7@1+ (1,0) [0|0] "" Vector__XXX
 SG_ VCFRONT_lccExvFailureConfidence m24 : 36|7@1+ (1,0) [0|0] "" Vector__XXX
 SG_ VC_rightHeadlampAimedHorizontalPosition m4 : 36|10@1+ (1,0) [0|0] "" Vector__XXX
 SG_ VC_rightHeadlampCurrentHorizontalPosition m3 : 36|10@1+ (1,0) [0|0] "" Vector__XXX
 SG_ VCFRONT_cclEXVCountOpenOvDrv m13 : 37|17@1+ (80,0) [0|0] "" Vector__XXX
 SG_ VCFRONT_ccrEXVCountOpenOvDrv m15 : 37|17@1+ (80,0) [0|0] "" Vector__XXX
 SG_ VCFRONT_chillerEXVCountOpenOvDrv m5 : 37|17@1+ (80,0) [0|0] "" Vector__XXX
 SG_ VCFRONT_evapEXVCountOpenOvDrv m7 : 37|17@1+ (80,0) [0|0] "" Vector__XXX
 SG_ VCFRONT_lccEXVCountOpenOvDrv m11 : 37|17@1+ (80,0) [0|0] "" Vector__XXX
 SG_ VCFRONT_recircEXVCountOpenOvDrv m9 : 37|17@1+ (80,0) [0|0] "" Vector__XXX
 SG_ VCFRONT_leftFrontFogLightCurrentSenseState m0 : 38|3@1+ (1,0) [0|0] "" Vector__XXX
 SG_ VCFRONT_HCML_diffuseTemp m1 : 40|8@1- (1,67) [0|0] "" Vector__XXX
 SG_ VCFRONT_HCMR_diffuseTemp m2 : 40|8@1- (1,67) [0|0] "" Vector__XXX
 SG_ VCFRONT_rightHeadlampCrcFaultCounter m21 : 40|8@1+ (1,0) [0|0] "" Vector__XXX
 SG_ VCFRONT_rightHeadlampLBWideDebouncedFaultCounter m22 : 40|3@1+ (1,0) [0|0] "" Vector__XXX
 SG_ VC_rightHeadlampPositionState m20 : 40|3@1+ (1,0) [0|0] "" Vector__XXX
 SG_ VCFRONT_compRotationCount m28 : 41|18@1+ (10000,0) [0|0] "" Vector__XXX
 SG_ VCFRONT_leftSideRepeaterLightCurrent m0 : 41|7@1+ (0.002,0) [0|0] "" Vector__XXX
 SG_ VC_hcmlCurrentBinMappingType m26 : 41|2@1+ (1,0) [0|0] "" Vector__XXX
 SG_ VC_hcmrCurrentBinMappingType m27 : 41|2@1+ (1,0) [0|0] "" Vector__XXX
 SG_ VCFRONT_TlFailureConfidence m23 : 43|7@1+ (1,0) [0|0] "" Vector__XXX
 SG_ VCFRONT_leftHeadlampBoostTemperatureBound m22 : 43|3@1+ (1,0) [0|0] "" Vector__XXX
 SG_ VCFRONT_sovFailureConfidence m24 : 43|7@1+ (1,0) [0|0] "" Vector__XXX
 SG_ VC_hcmlCurrentBin0Value m26 : 43|3@1+ (1,0) [0|0] "" Vector__XXX
 SG_ VC_hcmrCurrentBin0Value m27 : 43|3@1+ (1,0) [0|0] "" Vector__XXX
 SG_ VC_rightHeadlampPositionSubState m20 : 43|4@1+ (1,0) [0|0] "" Vector__XXX
 SG_ VCFRONT_calibratedPitchEstimate m4 : 46|10@1- (0.0002,0) [0|0] "" Vector__XXX
 SG_ VC_hcmlCurrentBin1Value m26 : 46|3@1+ (1,0) [0|0] "" Vector__XXX
 SG_ VC_hcmrCurrentBin1Value m27 : 46|3@1+ (1,0) [0|0] "" Vector__XXX
 SG_ VCFRONT_compLiquidDetectionTime m2 : 48|7@1+ (5,0) [0|0] "" Vector__XXX
 SG_ VCFRONT_headlampRegionAndTrafficSide m3 : 48|3@1+ (1,0) [0|0] "" Vector__XXX
 SG_ VCFRONT_leftSideRepeaterLightCurrentSenseState m0 : 48|3@1+ (1,0) [0|0] "" Vector__XXX
 SG_ VCFRONT_rightHeadlampBoostTemperatureBound m22 : 48|3@1+ (1,0) [0|0] "" Vector__XXX
 SG_ VCFRONT_rightHeadlampCommFaultCounter m21 : 48|8@1+ (1,0) [0|0] "" Vector__XXX
 SG_ VCFRONT_solverIterAvgAllModels m17 : 48|6@1+ (2,0) [0|0] "" Vector__XXX
 SG_ VCFRONT_solverIterAvgFeedforward m19 : 48|6@1+ (2,0) [0|0] "" Vector__XXX
 SG_ VCFRONT_solverIterAvgTotalLoad m18 : 48|6@1+ (2,0) [0|0] "" Vector__XXX
 SG_ VC_leftHeadlampECUTemperature m1 : 48|8@1- (1,60) [0|0] "" Vector__XXX
 SG_ VC_hcmlCurrentBin2Value m26 : 49|3@1+ (1,0) [0|0] "" Vector__XXX
 SG_ VC_hcmrCurrentBin2Value m27 : 49|3@1+ (1,0) [0|0] "" Vector__XXX
 SG_ VCFRONT_chillerExvFailureConfidence m23 : 50|7@1+ (1,0) [0|0] "" Vector__XXX
 SG_ VCFRONT_maxAmbientSourceCapacity m24 : 50|7@1+ (100,0) [0|0] "" Vector__XXX
 SG_ VCFRONT_sideMarkerLightCurrent m0 : 51|9@1+ (0.002,0) [0|0] "" Vector__XXX
 SG_ VC_leftHeadlampAimingState m3 : 51|3@1+ (1,0) [0|0] "" Vector__XXX
 SG_ VC_hcmlCurrentBin3Value m26 : 52|3@1+ (1,0) [0|0] "" Vector__XXX
 SG_ VC_hcmrCurrentBin3Value m27 : 52|3@1+ (1,0) [0|0] "" Vector__XXX
 SG_ VCFRONT_battHeatingPowerActual m2 : 56|7@1+ (100,0) [0|0] "" Vector__XXX
 SG_ VCFRONT_solverIterMaxAllModels m17 : 56|6@1+ (2,0) [0|0] "" Vector__XXX
 SG_ VCFRONT_solverIterMaxFeedforward m19 : 56|6@1+ (2,0) [0|0] "" Vector__XXX
 SG_ VCFRONT_solverIterMaxTotalLoad m18 : 56|6@1+ (2,0) [0|0] "" Vector__XXX
 SG_ VCFRONT_tempRefrigDischargeColdSoak m5 : 56|6@1+ (1,-40) [0|0] "" Vector__XXX
 SG_ VC_rightHeadlampAimingState m3 : 56|3@1+ (1,0) [0|0] "" Vector__XXX
 SG_ VC_rightHeadlampECUTemperature m1 : 56|8@1- (1,60) [0|0] "" Vector__XXX
 SG_ VCFRONT_airInRefrigerantFailureConfidence m24 : 57|7@1+ (1,0) [0|0] "" Vector__XXX
 SG_ VCFRONT_evapExvFailureConfidence m23 : 57|7@1+ (1,0) [0|0] "" Vector__XXX
 SG_ VCFRONT_sideMarkerLightCurrentSenseState m0 : 60|3@1+ (1,0) [0|0] "" Vector__XXX

BO_ 1802 VCLEFT_logging0point1Hz: 8 Vector__XXX
 SG_ VCLEFT_logging0point1HzIndex M : 0|1@1+ (1,0) [0|0] "" Vector__XXX
 SG_ VCLEFT_leftTailLightCurrent m0 : 2|9@1+ (0.002,0) [0|0] "" Vector__XXX
 SG_ VCLEFT_leftTailLightCurrentSenseState m0 : 11|3@1+ (1,0) [0|0] "" Vector__XXX
 SG_ VCLEFT_leftRearTurnLightCurrent m0 : 14|9@1+ (0.002,0) [0|0] "" Vector__XXX
 SG_ VCLEFT_leftRearTurnLightCurrentSenseState m0 : 24|3@1+ (1,0) [0|0] "" Vector__XXX
 SG_ VCLEFT_leftBrakeLightCurrent m0 : 28|9@1+ (0.005,0) [0|0] "" Vector__XXX
 SG_ VCLEFT_leftBrakeLightCurrentSenseState m0 : 37|3@1+ (1,0) [0|0] "" Vector__XXX

BO_ 1803 VCRIGHT_logging0point1Hz: 8 Vector__XXX
 SG_ VCRIGHT_logging0point1HzIndex M : 0|4@1+ (1,0) [0|0] "" Vector__XXX
 SG_ VCRIGHT_foggingMonitorRuntime m9 : 4|12@1+ (10,0) [0|0] "" Vector__XXX
 SG_ VCRIGHT_leftLiftgateTailLightCurrent m0 : 4|7@1+ (0.002,0) [0|0] "" Vector__XXX
 SG_ VCRIGHT_licensePlateLightCurrent m1 : 4|9@1+ (0.002,0) [0|0] "" Vector__XXX
 SG_ VCRIGHT_ambientTempLimp m6 : 8|8@1+ (0.5,-40) [0|0] "" Vector__XXX
 SG_ VCRIGHT_evapCondensateMass m7 : 8|8@1+ (2,0) [0|0] "" Vector__XXX
 SG_ VCRIGHT_evapLoadInFresh m8 : 8|8@1+ (35,0) [0|0] "" Vector__XXX
 SG_ VCRIGHT_hvacLHBleedEndStop m3 : 8|8@1+ (0.02,0) [0|0] "" Vector__XXX
 SG_ VCRIGHT_hvacLHBleedZeroStop m4 : 8|8@1+ (0.02,0) [0|0] "" Vector__XXX
 SG_ VCRIGHT_cabinAirFilterLifeRemaining m2 : 10|7@1+ (1,0) [0|0] "" Vector__XXX
 SG_ VCRIGHT_licensePlateLightCurrentSenseState m1 : 13|3@1+ (1,0) [0|0] "" Vector__XXX
 SG_ VCRIGHT_rightRearTurnLightCurrent m0 : 13|9@1+ (0.002,0) [0|0] "" Vector__XXX
 SG_ VCRIGHT_cabinProbeTempLimp m6 : 16|8@1+ (0.5,-40) [0|0] "" Vector__XXX
 SG_ VCRIGHT_evapLoadInRecirc m8 : 16|8@1+ (35,0) [0|0] "" Vector__XXX
 SG_ VCRIGHT_hvacRHBleedEndStop m3 : 16|8@1+ (0.02,0) [0|0] "" Vector__XXX
 SG_ VCRIGHT_hvacRHBleedZeroStop m4 : 16|8@1+ (0.02,0) [0|0] "" Vector__XXX
 SG_ VCRIGHT_reverseLightCurrent m1 : 16|9@1+ (0.002,0) [0|0] "" Vector__XXX
 SG_ VCRIGHT_HEPAAirFilterLifeRemaining m2 : 17|7@1+ (1,0) [0|0] "" Vector__XXX
 SG_ VCRIGHT_rightRearTurnLightCurrentSenseState m0 : 22|3@1+ (1,0) [0|0] "" Vector__XXX
 SG_ VCRIGHT_hvacLHVaneEndStop m3 : 24|8@1+ (0.02,0) [0|0] "" Vector__XXX
 SG_ VCRIGHT_hvacLHVaneZeroStop m4 : 24|8@1+ (0.02,0) [0|0] "" Vector__XXX
 SG_ VCRIGHT_leftPTCCompromisedRod m2 : 24|3@1+ (1,0) [0|0] "" Vector__XXX
 SG_ VCRIGHT_tempIncarCabinDeep m8 : 24|8@1+ (0.5,-40) [0|0] "" Vector__XXX
 SG_ VCRIGHT_thsTempLimp m6 : 24|8@1+ (0.5,-40) [0|0] "" Vector__XXX
 SG_ VCRIGHT_leftLiftgateTailLightCurrentSenseState m0 : 25|3@1+ (1,0) [0|0] "" Vector__XXX
 SG_ VCRIGHT_reverseLightCurrentSenseState m1 : 25|3@1+ (1,0) [0|0] "" Vector__XXX
 SG_ VCRIGHT_rightPTCCompromisedRod m2 : 27|3@1+ (1,0) [0|0] "" Vector__XXX
 SG_ VCRIGHT_rightBrakeLightCurrent m0 : 28|9@1+ (0.005,0) [0|0] "" Vector__XXX
 SG_ VCRIGHT_rightTrunkLightCurrent m1 : 28|9@1+ (0.002,0) [0|0] "" Vector__XXX
 SG_ VCRIGHT_cabinTempBreathLevelF10minHeating m8 : 32|8@1+ (0.5,-40) [0|0] "" Vector__XXX
 SG_ VCRIGHT_hepaFilterHealthScore m2 : 32|7@1+ (1,0) [0|0] "" Vector__XXX
 SG_ VCRIGHT_hvacRHVaneEndStop m3 : 32|8@1+ (0.02,0) [0|0] "" Vector__XXX
 SG_ VCRIGHT_hvacRHVaneZeroStop m4 : 32|8@1+ (0.02,0) [0|0] "" Vector__XXX
 SG_ VCRIGHT_thsCabinWaterMassLimp m6 : 32|8@1+ (0.5,0) [0|0] "" Vector__XXX
 SG_ VCRIGHT_rightBrakeLightCurrentSenseState m0 : 37|3@1+ (1,0) [0|0] "" Vector__XXX
 SG_ VCRIGHT_rightTrunkLightCurrentSenseState m1 : 37|3@1+ (1,0) [0|0] "" Vector__XXX
 SG_ VCRIGHT_cabinFilterHealthScore m2 : 40|7@1+ (1,0) [0|0] "" Vector__XXX
 SG_ VCRIGHT_cabinTempBreathLevelF10minCooling m8 : 40|8@1+ (0.5,-40) [0|0] "" Vector__XXX
 SG_ VCRIGHT_hvacUpperModeEndStop m3 : 40|8@1+ (0.02,0) [0|0] "" Vector__XXX
 SG_ VCRIGHT_hvacUpperModeZeroStop m4 : 40|8@1+ (0.02,0) [0|0] "" Vector__XXX
 SG_ VCRIGHT_rearFogLightCurrent m1 : 40|9@1+ (0.002,0) [0|0] "" Vector__XXX
 SG_ VCRIGHT_rightTailLightCurrent m0 : 40|9@1+ (0.002,0) [0|0] "" Vector__XXX
 SG_ VCRIGHT_thsSolarIrradianceLimp m6 : 40|8@1+ (5,0) [0|0] "" Vector__XXX
 SG_ VCRIGHT_cabinTempBreathLevelFOff m2 : 47|8@1+ (0.5,-40) [0|0] "" Vector__XXX
 SG_ VCRIGHT_cabinTempBreathLevelF5minHeating m8 : 48|8@1+ (0.5,-40) [0|0] "" Vector__XXX
 SG_ VCRIGHT_hvacLowerModeEndStop m3 : 48|8@1+ (0.02,0) [0|0] "" Vector__XXX
 SG_ VCRIGHT_hvacLowerModeZeroStop m4 : 48|8@1+ (0.02,0) [0|0] "" Vector__XXX
 SG_ VCRIGHT_silentWakeRecordCount m6 : 48|5@1+ (1,0) [0|0] "" Vector__XXX
 SG_ VCRIGHT_rearFogLightCurrentSenseState m1 : 49|3@1+ (1,0) [0|0] "" Vector__XXX
 SG_ VCRIGHT_rightTailLightCurrentSenseState m0 : 49|3@1+ (1,0) [0|0] "" Vector__XXX
 SG_ VCRIGHT_exteriorNightLightCurrent m0 : 52|9@1+ (0.002,0) [0|0] "" Vector__XXX
 SG_ VCRIGHT_leftTrunkLightCurrent m1 : 52|9@1+ (0.002,0) [0|0] "" Vector__XXX
 SG_ VCRIGHT_airDistributionModeAdjustmentFactor m2 : 55|9@1+ (0.001,1) [0|0] "" Vector__XXX
 SG_ VCRIGHT_cabinTempBreathLevelF5minCooling m8 : 56|8@1+ (0.5,-40) [0|0] "" Vector__XXX
 SG_ VCRIGHT_hvacIntakeEndStop m3 : 56|8@1+ (0.02,0) [0|0] "" Vector__XXX
 SG_ VCRIGHT_hvacIntakeZeroStop m4 : 56|8@1+ (0.02,0) [0|0] "" Vector__XXX
 SG_ VCRIGHT_interiorCameraLedCurrent m6 : 56|8@1+ (8,0) [0|0] "" Vector__XXX
 SG_ VCRIGHT_exteriorNightLightCurrentSenseState m0 : 61|3@1+ (1,0) [0|0] "" Vector__XXX
 SG_ VCRIGHT_leftTrunkLightCurrentSenseState m1 : 61|3@1+ (1,0) [0|0] "" Vector__XXX

BO_ 1810 BMS_packTemperatureMeasurements: 8 Vector__XXX
 SG_ BMS_packTemperatureMultiplexer M : 0|8@1+ (1,0) [0|0] "" Vector__XXX
 SG_ BMS_packTemperatureStatus1 m0 : 8|2@1+ (1,0) [0|0] "" Vector__XXX
 SG_ BMS_packTemperatureStatus10 m3 : 8|2@1+ (1,0) [0|0] "" Vector__XXX
 SG_ BMS_packTemperatureStatus13 m4 : 8|2@1+ (1,0) [0|0] "" Vector__XXX
 SG_ BMS_packTemperatureStatus16 m5 : 8|2@1+ (1,0) [0|0] "" Vector__XXX
 SG_ BMS_packTemperatureStatus4 m1 : 8|2@1+ (1,0) [0|0] "" Vector__XXX
 SG_ BMS_packTemperatureStatus7 m2 : 8|2@1+ (1,0) [0|0] "" Vector__XXX
 SG_ BMS_packTemperatureStatus11 m3 : 10|2@1+ (1,0) [0|0] "" Vector__XXX
 SG_ BMS_packTemperatureStatus14 m4 : 10|2@1+ (1,0) [0|0] "" Vector__XXX
 SG_ BMS_packTemperatureStatus17 m5 : 10|2@1+ (1,0) [0|0] "" Vector__XXX
 SG_ BMS_packTemperatureStatus2 m0 : 10|2@1+ (1,0) [0|0] "" Vector__XXX
 SG_ BMS_packTemperatureStatus5 m1 : 10|2@1+ (1,0) [0|0] "" Vector__XXX
 SG_ BMS_packTemperatureStatus8 m2 : 10|2@1+ (1,0) [0|0] "" Vector__XXX
 SG_ BMS_packTemperatureStatus12 m3 : 12|2@1+ (1,0) [0|0] "" Vector__XXX
 SG_ BMS_packTemperatureStatus15 m4 : 12|2@1+ (1,0) [0|0] "" Vector__XXX
 SG_ BMS_packTemperatureStatus18 m5 : 12|2@1+ (1,0) [0|0] "" Vector__XXX
 SG_ BMS_packTemperatureStatus3 m0 : 12|2@1+ (1,0) [0|0] "" Vector__XXX
 SG_ BMS_packTemperatureStatus6 m1 : 12|2@1+ (1,0) [0|0] "" Vector__XXX
 SG_ BMS_packTemperatureStatus9 m2 : 12|2@1+ (1,0) [0|0] "" Vector__XXX
 SG_ BMS_packTemperatureCounter : 14|2@1+ (1,0) [0|0] "" Vector__XXX
 SG_ BMS_packTemperature1 m0 : 16|16@1- (0.01,0) [0|0] "" Vector__XXX
 SG_ BMS_packTemperature10 m3 : 16|16@1- (0.01,0) [0|0] "" Vector__XXX
 SG_ BMS_packTemperature13 m4 : 16|16@1- (0.01,0) [0|0] "" Vector__XXX
 SG_ BMS_packTemperature16 m5 : 16|16@1- (0.01,0) [0|0] "" Vector__XXX
 SG_ BMS_packTemperature4 m1 : 16|16@1- (0.01,0) [0|0] "" Vector__XXX
 SG_ BMS_packTemperature7 m2 : 16|16@1- (0.01,0) [0|0] "" Vector__XXX
 SG_ BMS_packTemperature11 m3 : 32|16@1- (0.01,0) [0|0] "" Vector__XXX
 SG_ BMS_packTemperature14 m4 : 32|16@1- (0.01,0) [0|0] "" Vector__XXX
 SG_ BMS_packTemperature17 m5 : 32|16@1- (0.01,0) [0|0] "" Vector__XXX
 SG_ BMS_packTemperature2 m0 : 32|16@1- (0.01,0) [0|0] "" Vector__XXX
 SG_ BMS_packTemperature5 m1 : 32|16@1- (0.01,0) [0|0] "" Vector__XXX
 SG_ BMS_packTemperature8 m2 : 32|16@1- (0.01,0) [0|0] "" Vector__XXX
 SG_ BMS_packTemperature12 m3 : 48|16@1- (0.01,0) [0|0] "" Vector__XXX
 SG_ BMS_packTemperature15 m4 : 48|16@1- (0.01,0) [0|0] "" Vector__XXX
 SG_ BMS_packTemperature18 m5 : 48|16@1- (0.01,0) [0|0] "" Vector__XXX
 SG_ BMS_packTemperature3 m0 : 48|16@1- (0.01,0) [0|0] "" Vector__XXX
 SG_ BMS_packTemperature6 m1 : 48|16@1- (0.01,0) [0|0] "" Vector__XXX
 SG_ BMS_packTemperature9 m2 : 48|16@1- (0.01,0) [0|0] "" Vector__XXX

BO_ 1812 PMR_xcpResponse: 12 Vector__XXX
 SG_ PMR_xcpResponseData : 7|64@0+ (1,0) [0|0] "" Vector__XXX

BO_ 1814 DIR_xcpResponse: 12 Vector__XXX
 SG_ DIR_xcpResponseData : 7|64@0+ (1,0) [0|0] "" Vector__XXX

BO_ 1815 RCM_imuOffsets: 8 Vector__XXX
 SG_ RCM_imuOffsetsIndex M : 0|2@1+ (1,0) [0|0] "" Vector__XXX
 SG_ RCM_CGXdistance m2 : 8|16@1+ (1,-32768) [0|0] "" Vector__XXX
 SG_ RCM_longitudinalAccelOffset m1 : 8|16@1- (0.00125,0) [0|0] "" Vector__XXX
 SG_ RCM_yawRateOffset m0 : 8|16@1- (0.0001,0) [0|0] "" Vector__XXX
 SG_ RCM_CGYdistance m2 : 24|16@1+ (1,-32768) [0|0] "" Vector__XXX
 SG_ RCM_lateralAccelOffset m1 : 24|16@1- (0.00125,0) [0|0] "" Vector__XXX
 SG_ RCM_pitchRateOffset m0 : 24|16@1- (0.0001,0) [0|0] "" Vector__XXX
 SG_ RCM_CGZdistance m2 : 40|16@1+ (1,-32768) [0|0] "" Vector__XXX
 SG_ RCM_rollRateOffset m0 : 40|16@1- (0.0001,0) [0|0] "" Vector__XXX
 SG_ RCM_verticalAccelOffset m1 : 40|16@1- (0.00125,0) [0|0] "" Vector__XXX

BO_ 1816 VC_LVBMS_statusLow: 8 Vector__XXX
 SG_ VC_lvbmsStatusLowIndex M : 0|3@1+ (1,0) [0|0] "" Vector__XXX
 SG_ VC_LVBMS_AhCharged m2 : 8|32@1+ (0.001,0) [0|0] "" Vector__XXX
 SG_ VC_LVBMS_AhDischarged m3 : 8|32@1+ (0.001,0) [0|0] "" Vector__XXX
 SG_ VC_LVBMS_AvgSleepCurrent m1 : 8|16@1+ (0.01,-200) [0|0] "" Vector__XXX
 SG_ VC_LVBMS_SOC m0 : 8|7@1+ (1,0) [0|0] "" Vector__XXX
 SG_ VC_LVBMS_sumCellVoltageFiltered m4 : 8|16@1+ (0.001,0) [0|0] "" Vector__XXX
 SG_ VC_LVBMS_SOE m0 : 16|7@1+ (1,0) [0|0] "" Vector__XXX
 SG_ VC_LVBMS_SOH m0 : 24|7@1+ (1,0) [0|0] "" Vector__XXX
 SG_ VC_LVBMS_TimeSlept m1 : 24|24@1+ (1,0) [0|0] "" Vector__XXX
 SG_ VC_LVBMS_maxCellSOC m4 : 24|7@1+ (1,0) [0|0] "" Vector__XXX
 SG_ VC_LVBMS_CellOVLevel1 m0 : 31|1@1+ (1,0) [0|0] "" Vector__XXX
 SG_ VC_LVBMS_CellOVLevel2 m0 : 32|1@1+ (1,0) [0|0] "" Vector__XXX
 SG_ VC_LVBMS_minCellSOC m4 : 32|7@1+ (1,0) [0|0] "" Vector__XXX
 SG_ VC_LVBMS_CellOVLevel3 m0 : 33|1@1+ (1,0) [0|0] "" Vector__XXX
 SG_ VC_LVBMS_CellUVLevel1 m0 : 34|1@1+ (1,0) [0|0] "" Vector__XXX
 SG_ VC_LVBMS_CellUVLevel2 m0 : 35|1@1+ (1,0) [0|0] "" Vector__XXX
 SG_ VC_LVBMS_ModuleOTLevel1 m0 : 36|1@1+ (1,0) [0|0] "" Vector__XXX
 SG_ VC_LVBMS_PackOVLevel1 m0 : 37|1@1+ (1,0) [0|0] "" Vector__XXX
 SG_ VC_LVBMS_PackOVLevel2 m0 : 38|1@1+ (1,0) [0|0] "" Vector__XXX
 SG_ VC_LVBMS_DischrgOCLevel1 m0 : 39|1@1+ (1,0) [0|0] "" Vector__XXX
 SG_ VC_LVBMS_staticSOCCorrection m4 : 39|1@1+ (1,0) [0|0] "" Vector__XXX
 SG_ VC_LVBMS_DischrgOCLevel2 m0 : 40|1@1+ (1,0) [0|0] "" Vector__XXX
 SG_ VC_LVBMS_MaxSleepCurrent m3 : 40|16@1+ (0.01,-200) [0|0] "" Vector__XXX
 SG_ VC_LVBMS_MinSleepCurrent m2 : 40|16@1+ (0.01,-200) [0|0] "" Vector__XXX
 SG_ VC_LVBMS_dynamicSOCCorrection m4 : 40|1@1+ (1,0) [0|0] "" Vector__XXX
 SG_ VC_LVBMS_ChrgOCLevel1 m0 : 41|1@1+ (1,0) [0|0] "" Vector__XXX
 SG_ VC_LVBMS_usableEnergyAvailable m4 : 41|12@1+ (1,0) [0|0] "" Vector__XXX
 SG_ VC_LVBMS_ChrgOCLevel2 m0 : 42|1@1+ (1,0) [0|0] "" Vector__XXX
 SG_ VC_LVBMS_MOSFETOTLevel1 m0 : 43|1@1+ (1,0) [0|0] "" Vector__XXX
 SG_ VC_LVBMS_KBValueLostFault m0 : 44|1@1+ (1,0) [0|0] "" Vector__XXX
 SG_ VC_LVBMS_BalanceCircuitFault m0 : 45|1@1+ (1,0) [0|0] "" Vector__XXX
 SG_ VC_LVBMS_MOSStateFault m0 : 46|1@1+ (1,0) [0|0] "" Vector__XXX
 SG_ VC_LVBMS_NTCTempDiffWarnLevel1 m0 : 47|1@1+ (1,0) [0|0] "" Vector__XXX
 SG_ VC_LVBMS_DeepDischargeFlag m0 : 48|1@1+ (1,0) [0|0] "" Vector__XXX
 SG_ VC_LVBMS_SOP m1 : 48|8@1+ (20,0) [0|0] "" Vector__XXX
 SG_ VC_LVBMS_SamplingError m0 : 49|1@1+ (1,0) [0|0] "" Vector__XXX
 SG_ VC_LVBMS_MosfetStuckCloseError m0 : 50|1@1+ (1,0) [0|0] "" Vector__XXX
 SG_ VC_LVBMS_MosfetStuckOpenError m0 : 51|1@1+ (1,0) [0|0] "" Vector__XXX

BO_ 1817 VCSEC_debug100ms: 8 Vector__XXX
 SG_ VCSEC_debug100msIndex M : 0|5@1+ (1,0) [0|0] "" Vector__XXX
 SG_ VCSEC_BLE0WatchAppState m20 : 5|2@1+ (1,0) [0|0] "" Vector__XXX
 SG_ VCSEC_algoHighThreshRear m1 : 5|1@1+ (1,0) [0|0] "" Vector__XXX
 SG_ VCSEC_algoNNPresentModelClassRaw m14 : 5|1@1+ (1,0) [0|0] "" Vector__XXX
 SG_ VCSEC_lastSPComm_peripheral_BLE0 m19 : 5|2@1+ (1,0) [0|0] "" Vector__XXX
 SG_ VCSEC_walkAwayLockKeyState m0 : 5|2@1+ (1,0) [0|0] "" Vector__XXX
 SG_ VCSEC_algoNNPresentModelClassFilt m14 : 6|1@1+ (1,0) [0|0] "" Vector__XXX
 SG_ VCSEC_BLE0WatchNearBackgroundNotiLimit m20 : 7|1@1+ (1,0) [0|0] "" Vector__XXX
 SG_ VCSEC_algoNNPresentEnsembleClassRaw m14 : 7|1@1+ (1,0) [0|0] "" Vector__XXX
 SG_ VCSEC_BLE0MTUExchangeSplit m21 : 8|8@1+ (10,0) [0|0] "" Vector__XXX
 SG_ VCSEC_BLE0WatchExceededBgNotiLimit m20 : 8|1@1+ (1,0) [0|0] "" Vector__XXX
 SG_ VCSEC_BLE1MTUExchangeSplit m22 : 8|8@1+ (10,0) [0|0] "" Vector__XXX
 SG_ VCSEC_BLE2MTUExchangeSplit m23 : 8|8@1+ (10,0) [0|0] "" Vector__XXX
 SG_ VCSEC_UHFRSSI m2 : 8|8@1- (1,0) [0|0] "" Vector__XXX
 SG_ VCSEC_algoNNPresentEnsembleClassFilt m14 : 8|1@1+ (1,0) [0|0] "" Vector__XXX
 SG_ VCSEC_centerAdvertRSSI m3 : 8|8@1- (1,0) [0|0] "" Vector__XXX
 SG_ VCSEC_device0Offset m1 : 8|6@1- (0.5,0) [0|0] "" Vector__XXX
 SG_ VCSEC_lastSPComm_peripheral_BLE1 m19 : 8|2@1+ (1,0) [0|0] "" Vector__XXX
 SG_ VCSEC_lastToVCSECTagReceivedBLE0 m13 : 8|7@1+ (1,0) [0|0] "" Vector__XXX
 SG_ VCSEC_routingCompleteCounter m12 : 8|4@1+ (1,0) [0|0] "" Vector__XXX
 SG_ VCSEC_thresholdOffsetVersion m0 : 8|3@1+ (1,0) [0|0] "" Vector__XXX
 SG_ VCSEC_BLE0WatchBatteryLevel m20 : 9|6@1+ (2,0) [0|0] "" Vector__XXX
 SG_ VCSEC_algoNNPresentClassifierRawProb0 m14 : 9|7@1+ (0.01,0) [0|0] "" Vector__XXX
 SG_ VCSEC_lastSPComm_peripheral_BLE2 m19 : 10|2@1+ (1,0) [0|0] "" Vector__XXX
 SG_ VCSEC_walkAwayLockState m0 : 11|3@1+ (1,0) [0|0] "" Vector__XXX
 SG_ VCSEC_lastSPComm_peripheral_TPMS0 m19 : 12|2@1+ (1,0) [0|0] "" Vector__XXX
 SG_ VCSEC_routablesProcessed m12 : 12|4@1+ (1,0) [0|0] "" Vector__XXX
 SG_ VCSEC_lastSPComm_peripheral_TPMS1 m19 : 14|2@1+ (1,0) [0|0] "" Vector__XXX
 SG_ VCSEC_lastToVCSECTagReceivedBLE1 m13 : 15|7@1+ (1,0) [0|0] "" Vector__XXX
 SG_ VCSEC_BLE0ServiceDiscoverySplit m21 : 16|8@1+ (10,0) [0|0] "" Vector__XXX
 SG_ VCSEC_BLE1ServiceDiscoverySplit m22 : 16|8@1+ (10,0) [0|0] "" Vector__XXX
 SG_ VCSEC_BLE1WatchAppState m20 : 16|2@1+ (1,0) [0|0] "" Vector__XXX
 SG_ VCSEC_BLE2ServiceDiscoverySplit m23 : 16|8@1+ (10,0) [0|0] "" Vector__XXX
 SG_ VCSEC_UHFMeasureofSuccess m2 : 16|6@1+ (1,0) [0|0] "" Vector__XXX
 SG_ VCSEC_algoNNPresentClassifierRawProb1 m14 : 16|7@1+ (0.01,0) [0|0] "" Vector__XXX
 SG_ VCSEC_device1Offset m1 : 16|6@1- (0.5,0) [0|0] "" Vector__XXX
 SG_ VCSEC_lastSPComm_peripheral_TPMS2 m19 : 16|2@1+ (1,0) [0|0] "" Vector__XXX
 SG_ VCSEC_leftAdvertRSSI m3 : 16|8@1- (1,0) [0|0] "" Vector__XXX
 SG_ VCSEC_routingAddressesFreeCounter m12 : 16|4@1+ (1,0) [0|0] "" Vector__XXX
 SG_ VCSEC_rssi0WLEntry m0 : 16|5@1+ (1,0) [0|0] "" Vector__XXX
 SG_ VCSEC_BLE1WatchNearBackgroundNotiLimit m20 : 18|1@1+ (1,0) [0|0] "" Vector__XXX
 SG_ VCSEC_lastSPComm_peripheral_TPMS3 m19 : 18|2@1+ (1,0) [0|0] "" Vector__XXX
 SG_ VCSEC_BLE1WatchExceededBgNotiLimit m20 : 19|1@1+ (1,0) [0|0] "" Vector__XXX
 SG_ VCSEC_lastSPComm_central_BLE0 m19 : 20|2@1+ (1,0) [0|0] "" Vector__XXX
 SG_ VCSEC_routingCantFindAddressCounter m12 : 20|4@1+ (1,0) [0|0] "" Vector__XXX
 SG_ VCSEC_endpointLayout m0 : 21|2@1+ (1,0) [0|0] "" Vector__XXX
 SG_ VCSEC_UHFBasestationInitialized m2 : 22|1@1+ (1,0) [0|0] "" Vector__XXX
 SG_ VCSEC_lastSPComm_central_BLE1 m19 : 22|2@1+ (1,0) [0|0] "" Vector__XXX
 SG_ VCSEC_lastToVCSECTagReceivedBLE2 m13 : 22|7@1+ (1,0) [0|0] "" Vector__XXX
 SG_ VCSEC_BLE0SignUpSplit m21 : 24|8@1+ (10,0) [0|0] "" Vector__XXX
 SG_ VCSEC_BLE1SignUpSplit m22 : 24|8@1+ (10,0) [0|0] "" Vector__XXX
 SG_ VCSEC_BLE1WatchBatteryLevel m20 : 24|6@1+ (2,0) [0|0] "" Vector__XXX
 SG_ VCSEC_BLE2SignUpSplit m23 : 24|8@1+ (10,0) [0|0] "" Vector__XXX
 SG_ VCSEC_UHFradioState m2 : 24|3@1+ (1,0) [0|0] "" Vector__XXX
 SG_ VCSEC_algoNNPresentClassifierRawProb2 m14 : 24|7@1+ (0.01,0) [0|0] "" Vector__XXX
 SG_ VCSEC_device2Offset m1 : 24|6@1- (0.5,0) [0|0] "" Vector__XXX
 SG_ VCSEC_lastSPComm_central_BLE2 m19 : 24|2@1+ (1,0) [0|0] "" Vector__XXX
 SG_ VCSEC_rightAdvertRSSI m3 : 24|8@1- (1,0) [0|0] "" Vector__XXX
 SG_ VCSEC_routingOutofAddressCounter m12 : 24|4@1+ (1,0) [0|0] "" Vector__XXX
 SG_ VCSEC_rssi1WLEntry m0 : 24|5@1+ (1,0) [0|0] "" Vector__XXX
 SG_ VCSEC_lastSPComm_central_TPMS0 m19 : 26|2@1+ (1,0) [0|0] "" Vector__XXX
 SG_ VCSEC_UHFSleep m2 : 27|1@1+ (1,0) [0|0] "" Vector__XXX
 SG_ VCSEC_UHFDevUHFState m2 : 28|6@1+ (1,0) [0|0] "" Vector__XXX
 SG_ VCSEC_lastSPComm_central_TPMS1 m19 : 28|2@1+ (1,0) [0|0] "" Vector__XXX
 SG_ VCSEC_routingChannelBusyCounter m12 : 28|4@1+ (1,0) [0|0] "" Vector__XXX
 SG_ VCSEC_lastToVCSECTagReceivedRemote m13 : 29|7@1+ (1,0) [0|0] "" Vector__XXX
 SG_ VCSEC_BLE2WatchAppState m20 : 30|2@1+ (1,0) [0|0] "" Vector__XXX
 SG_ VCSEC_lastSPComm_central_TPMS2 m19 : 30|2@1+ (1,0) [0|0] "" Vector__XXX
 SG_ VCSEC_BLE0AuthResponseSplit m21 : 32|8@1+ (10,0) [0|0] "" Vector__XXX
 SG_ VCSEC_BLE1AuthResponseSplit m22 : 32|8@1+ (10,0) [0|0] "" Vector__XXX
 SG_ VCSEC_BLE2AuthResponseSplit m23 : 32|8@1+ (10,0) [0|0] "" Vector__XXX
 SG_ VCSEC_BLE2WatchNearBackgroundNotiLimit m20 : 32|1@1+ (1,0) [0|0] "" Vector__XXX
 SG_ VCSEC_algoNNPresentClassifierFiltProb0 m14 : 32|7@1+ (0.01,0) [0|0] "" Vector__XXX
 SG_ VCSEC_flowControlSentCounter m12 : 32|4@1+ (1,0) [0|0] "" Vector__XXX
 SG_ VCSEC_lastSPComm_central_TPMS3 m19 : 32|2@1+ (1,0) [0|0] "" Vector__XXX
 SG_ VCSEC_rearAdvertRSSI m3 : 32|8@1- (1,0) [0|0] "" Vector__XXX
 SG_ VCSEC_rssi2WLEntry m0 : 32|5@1+ (1,0) [0|0] "" Vector__XXX
 SG_ VCSEC_BLE2WatchExceededBgNotiLimit m20 : 33|1@1+ (1,0) [0|0] "" Vector__XXX
 SG_ VCSEC_BLE2WatchBatteryLevel m20 : 34|6@1+ (2,0) [0|0] "" Vector__XXX
 SG_ VCSEC_UHFRecalibrationState m2 : 34|3@1+ (1,0) [0|0] "" Vector__XXX
 SG_ VCSEC_infoRequestSlotsCounter m12 : 36|4@1+ (1,0) [0|0] "" Vector__XXX
 SG_ VCSEC_lastFromVCSECTagSentBLE0 m13 : 36|7@1+ (1,0) [0|0] "" Vector__XXX
 SG_ VCSEC_UHFRecalibrated m2 : 37|1@1+ (1,0) [0|0] "" Vector__XXX
 SG_ VCSEC_walkUpUnlockState m0 : 37|3@1+ (1,0) [0|0] "" Vector__XXX
 SG_ VCSEC_UHFRecalibrationFailure m2 : 38|1@1+ (1,0) [0|0] "" Vector__XXX
 SG_ VCSEC_UHFFaultReceiverReset m2 : 39|1@1+ (1,0) [0|0] "" Vector__XXX
 SG_ VCSEC_BLE0PhoneBatteryState m20 : 40|2@1+ (1,0) [0|0] "" Vector__XXX
 SG_ VCSEC_UHFFaultResponseTimeout m2 : 40|1@1+ (1,0) [0|0] "" Vector__XXX
 SG_ VCSEC_algoHighThreshLeft m0 : 40|1@1+ (1,0) [0|0] "" Vector__XXX
 SG_ VCSEC_algoNNPresentClassifierFiltProb1 m14 : 40|7@1+ (0.01,0) [0|0] "" Vector__XXX
 SG_ VCSEC_incomingMessageOutOfAddressCounter m12 : 40|4@1+ (1,0) [0|0] "" Vector__XXX
 SG_ VCSEC_UHFFaultSPITimeout m2 : 41|1@1+ (1,0) [0|0] "" Vector__XXX
 SG_ VCSEC_algoHighThreshRight m0 : 41|1@1+ (1,0) [0|0] "" Vector__XXX
 SG_ VCSEC_BLE0PhoneBatteryLevel m20 : 42|6@1+ (2,0) [0|0] "" Vector__XXX
 SG_ VCSEC_UHFFaultRadioBadState m2 : 42|1@1+ (1,0) [0|0] "" Vector__XXX
 SG_ VCSEC_algoHighThreshCenter m0 : 42|1@1+ (1,0) [0|0] "" Vector__XXX
 SG_ VCSEC_UHFFaultPLLNotLocked m2 : 43|1@1+ (1,0) [0|0] "" Vector__XXX
 SG_ VCSEC_lastFromVCSECTagSentBLE1 m13 : 43|7@1+ (1,0) [0|0] "" Vector__XXX
 SG_ VCSEC_pollingReason m0 : 43|4@1+ (1,0) [0|0] "" Vector__XXX
 SG_ VCSEC_UHFFaultCalibrationFail m2 : 44|1@1+ (1,0) [0|0] "" Vector__XXX
 SG_ VCSEC_incomingMessageChannelBusyCounter m12 : 44|4@1+ (1,0) [0|0] "" Vector__XXX
 SG_ VCSEC_UHFNumberEndpointResets m2 : 45|16@1+ (1,0) [0|0] "" Vector__XXX
 SG_ VCSEC_BLE1PhoneBatteryState m20 : 48|2@1+ (1,0) [0|0] "" Vector__XXX
 SG_ VCSEC_algoNNPresentClassifierFiltProb2 m14 : 48|7@1+ (0.01,0) [0|0] "" Vector__XXX
 SG_ VCSEC_incomingMessageSigStartFailCounter m12 : 48|4@1+ (1,0) [0|0] "" Vector__XXX
 SG_ VCSEC_numberOfPubKeysOnWhitelist m0 : 48|5@1+ (1,0) [0|0] "" Vector__XXX
 SG_ VCSEC_BLE1PhoneBatteryLevel m20 : 50|6@1+ (2,0) [0|0] "" Vector__XXX
 SG_ VCSEC_lastFromVCSECTagSentBLE2 m13 : 50|7@1+ (1,0) [0|0] "" Vector__XXX
 SG_ VCSEC_routableNotDispatched m12 : 52|1@1+ (1,0) [0|0] "" Vector__XXX
 SG_ VCSEC_BLE0LastMessageRoutable m12 : 53|1@1+ (1,0) [0|0] "" Vector__XXX
 SG_ VCSEC_thermalDetectState m0 : 53|2@1+ (1,0) [0|0] "" Vector__XXX
 SG_ VCSEC_BLE1LastMessageRoutable m12 : 54|1@1+ (1,0) [0|0] "" Vector__XXX
 SG_ VCSEC_BLE2LastMessageRoutable m12 : 55|1@1+ (1,0) [0|0] "" Vector__XXX
 SG_ VCSEC_chargeHandleMitigationActive m0 : 55|1@1+ (1,0) [0|0] "" Vector__XXX
 SG_ VCSEC_BLE2PhoneBatteryState m20 : 56|2@1+ (1,0) [0|0] "" Vector__XXX
 SG_ VCSEC_algoNNPresentRevision m14 : 56|8@1+ (1,0) [0|0] "" Vector__XXX
 SG_ VCSEC_lastFromVCSECTagSentRemote m13 : 57|7@1+ (1,0) [0|0] "" Vector__XXX
 SG_ VCSEC_BLE2PhoneBatteryLevel m20 : 58|6@1+ (2,0) [0|0] "" Vector__XXX
 SG_ VCSEC_UHFInterruptState m2 : 61|1@1+ (1,0) [0|0] "" Vector__XXX

BO_ 1822 GB_chgLogData: 8 Vector__XXX
 SG_ GB_chgLogDataSelect M : 0|4@1+ (1,0) [0|0] "" Vector__XXX
 SG_ GB_BMS_ID_Tmt m8 : 4|2@1+ (1,0) [0|0] "" Vector__XXX
 SG_ GB_Chg_Stop_Rsn_Setpoint m6 : 4|2@1+ (1,0) [0|0] "" Vector__XXX
 SG_ GB_BMS_CHG_Param_Tmt m8 : 6|2@1+ (1,0) [0|0] "" Vector__XXX
 SG_ GB_Chg_Stop_Rsn_Manual m6 : 6|2@1+ (1,0) [0|0] "" Vector__XXX
 SG_ GB_BMS_CHG_Ready_Tmt m8 : 8|2@1+ (1,0) [0|0] "" Vector__XXX
 SG_ GB_Chg_Stop_Rsn_Error m6 : 8|2@1+ (1,0) [0|0] "" Vector__XXX
 SG_ GB_EVSE_outputCurrent_value m11 : 8|16@1- (1,0) [0|0] "" Vector__XXX
 SG_ GB_FC_maxCurrentLimit m9 : 8|16@1+ (0.1,-400) [0|0] "" Vector__XXX
 SG_ GB_Local_Area_Number m2 : 8|24@1+ (1,0) [0|0] "" Vector__XXX
 SG_ GB_Max_Output_V m3 : 8|14@1+ (0.1,0) [0|0] "" Vector__XXX
 SG_ GB_Protocol_Ver m0 : 8|24@1+ (1,0) [0|0] "" Vector__XXX
 SG_ GB_Recognition_Result m1 : 8|8@1+ (1,0) [0|0] "" Vector__XXX
 SG_ GB_Total_Chg_Time m7 : 8|16@1+ (1,0) [0|0] "" Vector__XXX
 SG_ GB_Vout m5 : 8|16@1+ (0.1,0) [0|0] "" Vector__XXX
 SG_ GB_ready m4 : 8|8@1+ (1,0) [0|0] "" Vector__XXX
 SG_ GB_BMS_CHG_Status_Tmt m8 : 10|2@1+ (1,0) [0|0] "" Vector__XXX
 SG_ GB_Chg_Stop_Rsn_BST m6 : 10|2@1+ (1,0) [0|0] "" Vector__XXX
 SG_ GB_BMS_CHG_Demand_Tmt m8 : 12|2@1+ (1,0) [0|0] "" Vector__XXX
 SG_ GB_Chg_Stop_Rsn_OT_FLT m6 : 12|2@1+ (1,0) [0|0] "" Vector__XXX
 SG_ GB_BMS_CHG_Stop_Tmt m8 : 14|2@1+ (1,0) [0|0] "" Vector__XXX
 SG_ GB_Chg_Stop_Rsn_Conn_FLT m6 : 14|2@1+ (1,0) [0|0] "" Vector__XXX
 SG_ GB_BMS_CHG_Statistic_Tmt m8 : 16|2@1+ (1,0) [0|0] "" Vector__XXX
 SG_ GB_Charger_Number m1 : 16|32@1+ (1,0) [0|0] "" Vector__XXX
 SG_ GB_Chg_Stop_Rsn_EVSE_OT_FLT m6 : 16|2@1+ (1,0) [0|0] "" Vector__XXX
 SG_ GB_BMS_CHG_Others m8 : 18|6@1+ (1,0) [0|0] "" Vector__XXX
 SG_ GB_Chg_Stop_Rsn_Bad_Req_FLT m6 : 18|2@1+ (1,0) [0|0] "" Vector__XXX
 SG_ GB_Chg_Stop_Rsn_E_Stop_FLT m6 : 20|2@1+ (1,0) [0|0] "" Vector__XXX
 SG_ GB_Chg_Stop_Rsn_Other_FLT m6 : 22|2@1+ (1,0) [0|0] "" Vector__XXX
 SG_ GB_Chg_Stop_Rsn_I_Match_ERR m6 : 24|2@1+ (1,0) [0|0] "" Vector__XXX
 SG_ GB_EVSE_maxCurrentLimit_value m11 : 24|16@1- (1,0) [0|0] "" Vector__XXX
 SG_ GB_EVSE_teslaGbProtocolVersion m9 : 24|8@1+ (1,0) [0|0] "" Vector__XXX
 SG_ GB_Iout m5 : 24|16@1+ (0.1,-400) [0|0] "" Vector__XXX
 SG_ GB_Min_Output_V m3 : 24|14@1+ (0.1,0) [0|0] "" Vector__XXX
 SG_ GB_Total_Chg_Energy m7 : 24|16@1+ (0.1,0) [0|0] "" Vector__XXX
 SG_ GB_Chg_Stop_Rsn_V_ERR m6 : 26|2@1+ (1,0) [0|0] "" Vector__XXX
 SG_ GB_Max_Output_I m3 : 38|13@1+ (0.1,-400) [0|0] "" Vector__XXX
 SG_ GB_Chg_Time m5 : 40|16@1+ (1,0) [0|0] "" Vector__XXX
 SG_ GB_EVSE_outputCurrent_exp m11 : 40|3@1- (1,0) [0|0] "" Vector__XXX
 SG_ GB_EVSE_maxCurrentLimit_exp m11 : 43|3@1- (1,0) [0|0] "" Vector__XXX
 SG_ GB_Min_Output_I m3 : 51|13@1+ (0.1,-400) [0|0] "" Vector__XXX
 SG_ GB_Chg_Permission m5 : 56|2@1+ (1,0) [0|0] "" Vector__XXX

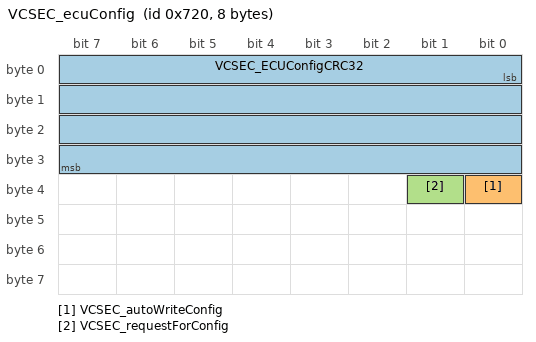
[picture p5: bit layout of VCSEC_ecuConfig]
BO_ 1824 VCSEC_ecuConfig: 8 Vector__XXX
 SG_ VCSEC_ECUConfigCRC32 : 0|32@1+ (1,0) [0|0] "" Vector__XXX
 SG_ VCSEC_autoWriteConfig : 32|1@1+ (1,0) [0|0] "" Vector__XXX
 SG_ VCSEC_requestForConfig : 33|1@1+ (1,0) [0|0] "" Vector__XXX

VAL_ 1480 EPBL_alertID 0 "ALERT_DO_NOT_USE_ZERO" 1 "a001_DriverDoorOpen" 2 "a002_DoorOpen" 3 "a003_TrunkOpen" 4 "a004_FrunkOpen" 5 "a005_HeadlightsOnDoorOpen" 6 "a006_RemoteServiceAlert" 7 "a007_SoftPackConfigMismatch" 8 "a008_TouchScreenError" 9 "a009_SquashfsError" 10 "a010_MapsMissing" 11 "a011_IncorrectMap" 12 "a012_NotOnPrivateProperty" 13 "a013_TPMSHardWarning" 14 "a014_TPMSSoftWarning" 15 "a015_TPMSOverPressureWarning" 16 "a016_TPMSTemperatureWarning" 17 "a017_TPMSSystemFault" 18 "a018_SlipStartOn" 19 "a019_ParkBrakeFault" 20 "a020_SteeringReduced" 21 "a021_RearSeatbeltUnbuckled" 22 "a022_ApeFusesEtc" 23 "a023_CellInternetCheckFailed" 24 "a024_WifiInternetCheckFailed" 25 "a025_WifiOnlineCheckFailed" 26 "a026_ModemResetLoopDetected" 27 "a027_AutoSteerMIA" 28 "a028_FrontTrunkPopupClosed" 29 "a029_ModemMIA" 30 "a030_ModemVMCrash" 31 "a031_BrakeFluidLow" 32 "a032_CellModemRecoveryResets" 33 "a033_ApTrialExpired" 34 "a034_WakeupProblem" 35 "a035_AudioWatchdogKernelError" 36 "a036_AudioWatchdogHfpError" 37 "a037_AudioWatchdogXrunStormError" 38 "a038_AudioWatchdogA2bI2cLockupError" 39 "a039_AudioA2bNeedRediscovery" 40 "a040_HomelinkTransmit" 41 "a041_AudioDmesgXrun" 42 "a042_AudioDmesgRtThrottling" 43 "a043_InvalidMapDataOverride" 44 "a044_AudioDmesgDspException" 45 "a045_ECallNeedsService" 46 "a046_BackupCameraStreamError" 47 "a047_CellRoamingDisallowed" 48 "a048_AudioPremiumAmpCheckFailed" 49 "a049_BrakeShiftRequired" 50 "a050_BackupCameraIPUTimeout" 51 "a051_BackupCameraFrameTimeout" 52 "a052_KernelPanicReported" 53 "a053_QtCarExitError" 54 "a054_AudioBoostPowerBad" 55 "a055_ManualECallDisabled" 56 "a056_ManualECallButtonDisconnected" 57 "a057_CellAntennaDisconnected" 58 "a058_GPSAntennaDisconnected" 59 "a059_ECallSpeakerDisconnected" 60 "a060_ECallMicDisconnected" 61 "a061_SIMTestFailed" 62 "a062_ENSTestFailed" 63 "a063_CellularTestFailed" 64 "a064_ModemFirmwareTestFailed" 65 "a065_WiFiRecoveryReset" 66 "a066_GpuHangDetected" 67 "a067_WarnOnI915" 68 "a068_VideoUnexpectedExit" 69 "a069_VideoUDPTimeout" 70 "a070_VideoPipelineWarning" 71 "a071_VideoPipelineError" 72 "a072_ECallAnalogMicFailed" 73 "a073_ECallDigitalMicFailed" 74 "a074_EMMCHangDetected" 75 "a075_BackupCameraInitError" 76 "a076_NumFalseManualECalls" 77 "a077_AudioA2bMicChannelSwap" 78 "a078_DashcamUsbDriveUnmountable" 79 "a079_DashcamUsbDriveFull" 80 "a080_DashcamUsbDriveSlow" 81 "a081_CellModemSearchExpired" 82 "a082_NumModemRebootStuckInECall" 83 "a083_ECallProxyWatchdogTriggered" 84 "a084_SerializerError" 85 "a085_DeserializerError" 86 "a086_TouchEnumerationError" 87 "a087_BmpReset" 88 "a088_CellRemovableSimMissing" 89 "a089_RadioSoftResetError" 90 "a090_RadioPingFailError" 91 "a091_VehicleLinkStall" 92 "a092_updateStarted" 93 "a093_updateEnded" 94 "a094_ModemPowerOnFailure" 95 "a095_CidStorageRunningLow" 96 "a096_VideodPipelineIssueDetected" 97 "a097_AudiodRestarted" 98 "a098_DiskCheckFailure" 99 "a099_eMMCStatusError" 100 "a100_eMMCFTLError" 101 "a101_wifiStackProblem" 102 "a102_A2bDiscoveryFailed" 103 "a103_UsbHubNotEnumerating" 104 "a104_DashcamUsbDriveMissing" 105 "a105_firmwareReinstallRequested" 106 "a106_rebootBackstopTriggered" 107 "a107_DashcamUsbDriveTooBigForVfatFsck" 108 "a108_DashcamUsbDriveGettingFull" 109 "a109_DashcamUsbDriveTooSmall" 110 "a110_DashcamUsbDriveCorrupt" 111 "a111_DashcamUsbDriveWrongPort" 112 "a112_badUSBDevice" 113 "a113_DashcamHasOnboardSentryClips" ;
VAL_ 1480 EPBL_alertState 0 "CLEARED" 1 "SET" ;
VAL_ 1480 EPBL_a031_uds_bytes_0 0 "0" 1 "1" 2 "2" 3 "3" 4 "4" 5 "5" 6 "6" 7 "7" 8 "8" 9 "9" 10 "10" 11 "11" 12 "12" 13 "13" 14 "14" 15 "15" 16 "16" 17 "17" 18 "18" 19 "19" 20 "20" 21 "21" 22 "22" 23 "23" 24 "24" 25 "25" 26 "26" 27 "27" 28 "28" 29 "29" 30 "30" 31 "31" ;
VAL_ 1480 EPBL_a096_VEH_status 0 "DISABLED" 1 "ENABLED" 2 "TEMPORARY_FAILURE" 3 "SNA" ;
VAL_ 1480 EPBL_a101_VEH_state 0 "STANDBY" 1 "DRIVE" 2 "SUPPORT" 3 "CHARGE" 4 "FEIM" 5 "CLEAR_FAULT" 6 "FAULT" 7 "WELD" 8 "TEST" 9 "SNA" 10 "DIAG" ;
VAL_ 1480 EPBL_a109_PARTY_status 0 "DISABLED" 1 "ENABLED" 2 "TEMPORARY_FAILURE" 3 "SNA" ;
VAL_ 1480 EPBL_a114_PARTY_status 0 "DISABLED" 1 "ENABLED" 2 "TEMPORARY_FAILURE" 3 "SNA" ;
VAL_ 1480 EPBL_a185_summonFaultReason 0 "NONE" 1 "DI_MIA" 2 "DAS_MIA" 3 "ESP_MIA" 4 "EPBM_MIA" 5 "DI_FAULT" 6 "DI_APC_FAULT" 7 "DAS_FAULT" 8 "ESP_FAULT" 9 "VEH_CAN_FAULT" 10 "EAC_NOT_ALLOWED" 11 "EPBM_REQUEST" 12 "SPEED" 13 "EXTERNAL" 14 "PARK_MIA" 15 "PM_MIA" 16 "PM_REQUEST" 17 "OOC" 18 "MISMATCH" 19 "EPB_FAULT" 20 "DI_STATE_INVALID" 21 "PASSIVE_REQUEST" 22 "EPBREMOTE_MIA" 23 "REMOTE_SUMMON_FAULTED" 24 "LOCAL_UNIT_FAULTED" 25 "REMOTE_UNIT_FAULTED" 26 "START_IN_UNAVAILABLE" 27 "INVALID_REMOTE_STATE" 28 "REMOTE_DID_NOT_START" ;
VAL_ 1480 EPBL_a243_brakeMasterCylPress 1023 "SNA" ;
VAL_ 1480 EPBL_a250_esmSpeedClass 0 "STOPPED" 1 "SYSTEM_APPLY_OK" 2 "USER_APPLY_OK" 3 "FAST" 4 "UNKNOWN" ;
VAL_ 1480 EPBL_a301_setSpeed 4095 "SNA" ;
VAL_ 1480 EPBL_a362_brakeMasterCylPress 1023 "SNA" ;
VAL_ 1480 EPBL_a363_brakeMasterCylPress 1023 "SNA" ;
VAL_ 1480 EPBL_a089_PARTY_status 0 "DISABLED" 1 "ENABLED" 2 "TEMPORARY_FAILURE" 3 "SNA" ;
VAL_ 1480 EPBL_a090_VEH_state 0 "STANDBY" 1 "DRIVE" 2 "SUPPORT" 3 "CHARGE" 4 "FEIM" 5 "CLEAR_FAULT" 6 "FAULT" 7 "WELD" 8 "TEST" 9 "SNA" 10 "DIAG" ;
VAL_ 1480 EPBL_a095_PT_status 0 "DISABLED" 1 "ENABLED" 2 "TEMPORARY_FAILURE" 3 "SNA" ;
VAL_ 1480 EPBL_a096_CH_status 0 "DISABLED" 1 "ENABLED" 2 "TEMPORARY_FAILURE" 3 "SNA" ;
VAL_ 1480 EPBL_a097_VEH_state 0 "STANDBY" 1 "DRIVE" 2 "SUPPORT" 3 "CHARGE" 4 "FEIM" 5 "CLEAR_FAULT" 6 "FAULT" 7 "WELD" 8 "TEST" 9 "SNA" 10 "DIAG" ;
VAL_ 1480 EPBL_a111_VEH_status 0 "DISABLED" 1 "ENABLED" 2 "TEMPORARY_FAILURE" 3 "SNA" ;
VAL_ 1480 EPBL_a112_VEH_status 0 "DISABLED" 1 "ENABLED" 2 "TEMPORARY_FAILURE" 3 "SNA" ;
VAL_ 1480 EPBL_a120_VEH_systemStatus 0 "UNKNOWN" 1 "RELEASED" 2 "PARKED" 3 "DYNAMIC" 4 "PARKING" 5 "RELEASING" 6 "FAULT" 7 "FAULT_SECURE" 8 "MISMATCH" ;
VAL_ 1480 EPBL_a243_brakeMasterCylPressQF 0 "NOT_INITIALIZED" 1 "NORMAL" 2 "FAULTED" 3 "FAULTED2" ;
VAL_ 1480 EPBL_a086_VEH_status 0 "DISABLED" 1 "ENABLED" 2 "TEMPORARY_FAILURE" 3 "SNA" ;
VAL_ 1480 EPBL_a089_VEH_status 0 "DISABLED" 1 "ENABLED" 2 "TEMPORARY_FAILURE" 3 "SNA" ;
VAL_ 1480 EPBL_a091_VEH_state 0 "STANDBY" 1 "DRIVE" 2 "SUPPORT" 3 "CHARGE" 4 "FEIM" 5 "CLEAR_FAULT" 6 "FAULT" 7 "WELD" 8 "TEST" 9 "SNA" 10 "DIAG" ;
VAL_ 1480 EPBL_a098_VEH_status 0 "DISABLED" 1 "ENABLED" 2 "TEMPORARY_FAILURE" 3 "SNA" ;
VAL_ 1480 EPBL_a103_VEH_status 0 "DISABLED" 1 "ENABLED" 2 "TEMPORARY_FAILURE" 3 "SNA" ;
VAL_ 1480 EPBL_a104_LIPC_status 0 "DISABLED" 1 "ENABLED" 2 "TEMPORARY_FAILURE" 3 "SNA" ;
VAL_ 1480 EPBL_a107_VEH_status 0 "DISABLED" 1 "ENABLED" 2 "TEMPORARY_FAILURE" 3 "SNA" ;
VAL_ 1480 EPBL_a243_drivetrainType 0 "RWD" 1 "AWD" ;
VAL_ 1480 EPBL_a087_VEH_status 0 "DISABLED" 1 "ENABLED" 2 "TEMPORARY_FAILURE" 3 "SNA" ;
VAL_ 1480 EPBL_a088_VEH_status 0 "DISABLED" 1 "ENABLED" 2 "TEMPORARY_FAILURE" 3 "SNA" ;
VAL_ 1480 EPBL_a118_VEH_status 0 "DISABLED" 1 "ENABLED" 2 "TEMPORARY_FAILURE" 3 "SNA" ;
VAL_ 1480 EPBL_a120_PARTY_systemStatus 0 "UNKNOWN" 1 "RELEASED" 2 "PARKED" 3 "DYNAMIC" 4 "PARKING" 5 "RELEASING" 6 "FAULT" 7 "FAULT_SECURE" 8 "MISMATCH" ;
VAL_ 1480 EPBL_a089_BDY_status 0 "DISABLED" 1 "ENABLED" 2 "TEMPORARY_FAILURE" 3 "SNA" ;
VAL_ 1480 EPBL_a103_PT_status 0 "DISABLED" 1 "ENABLED" 2 "TEMPORARY_FAILURE" 3 "SNA" ;
VAL_ 1480 EPBL_a108_VEH_status 0 "DISABLED" 1 "ENABLED" 2 "TEMPORARY_FAILURE" 3 "SNA" ;
VAL_ 1480 EPBL_a109_VEH_status 0 "DISABLED" 1 "ENABLED" 2 "TEMPORARY_FAILURE" 3 "SNA" ;
VAL_ 1480 EPBL_a242_hvState 0 "DOWN" 1 "COMING_UP" 2 "GOING_DOWN" 3 "UP_FOR_DRIVE" 4 "UP_FOR_CHARGE" 5 "UP_FOR_DC_CHARGE" 6 "UP" ;
VAL_ 1480 EPBL_a087_PARTY_status 0 "DISABLED" 1 "ENABLED" 2 "TEMPORARY_FAILURE" 3 "SNA" ;
VAL_ 1480 EPBL_a088_PARTY_status 0 "DISABLED" 1 "ENABLED" 2 "TEMPORARY_FAILURE" 3 "SNA" ;
VAL_ 1480 EPBL_a089_CH_status 0 "DISABLED" 1 "ENABLED" 2 "TEMPORARY_FAILURE" 3 "SNA" ;
VAL_ 1480 EPBL_a086_VEH_systemStatus 0 "UNKNOWN" 1 "RELEASED" 2 "PARKED" 3 "DYNAMIC" 4 "PARKING" 5 "RELEASING" 6 "FAULT" 7 "FAULT_SECURE" 8 "MISMATCH" ;
VAL_ 1480 EPBL_a098_PARTY_status 0 "DISABLED" 1 "ENABLED" 2 "TEMPORARY_FAILURE" 3 "SNA" ;
VAL_ 1480 EPBL_a108_PARTY_status 0 "DISABLED" 1 "ENABLED" 2 "TEMPORARY_FAILURE" 3 "SNA" ;
VAL_ 1480 EPBL_a114_VEH_status 0 "DISABLED" 1 "ENABLED" 2 "TEMPORARY_FAILURE" 3 "SNA" ;
VAL_ 1480 EPBL_a243_vehicleSpeed 8191 "SNA" ;
VAL_ 1480 EPBL_a107_PT_status 0 "DISABLED" 1 "ENABLED" 2 "TEMPORARY_FAILURE" 3 "SNA" ;
VAL_ 1480 EPBL_a243_tempAmbient 0 "SNA" ;
VAL_ 1480 EPBL_a241_vehiclePowerState 0 "OFF" 1 "CONDITIONING" 2 "ACCESSORY" 3 "DRIVE" ;
VAL_ 1480 EPBL_a242_vehiclePowerState 0 "OFF" 1 "CONDITIONING" 2 "ACCESSORY" 3 "DRIVE" ;
VAL_ 1480 EPBL_a250_esmOperationTrigger 0 "PBUTTON_PRESSED_STOPPED" 1 "PBUTTON_PRESSED_OKTOPARK" 2 "PBUTTON_PRESSED_FAST" 3 "PBUTTON_PRESSED_UNKNOWN" 4 "PBUTTON_RELEASED" 5 "ACTIVE_PARK_REQUEST" 6 "DI_UNPARK" 7 "TOUCHSCREEN" 8 "WINCHMODE_EXIT" 9 "WINCHMODE_ENTER" 10 "WINCHMODE_UNAVAILABLE" 11 "SERVICE" 12 "DIAG_CLOSE" 13 "DIAG_OPEN" 14 "DIAG_EXIT" 15 "USER_CONFIRMED" 16 "USER_CANCEL" 17 "SPEED_STOPPED" 18 "SPEED_OKAYTOPARK" 19 "SPEED_FAST" 20 "TIMEOUT" 21 "SAVESTATE_ON_BOOT" 22 "REAPPLY" 23 "SUMMON_COMPLETE" 24 "FAULT" 25 "SUMMON_FAULT" 26 "DISQUALIFIED" 27 "EPBM_DISQUALIFIED" 28 "ACCELERATION" 29 "SYSTEM_APPLY" 30 "DRIVER_IS_LEAVING" 31 "AUTOPARK_END" ;
VAL_ 1480 EPBL_a112_PARTY_status 0 "DISABLED" 1 "ENABLED" 2 "TEMPORARY_FAILURE" 3 "SNA" ;
VAL_ 1480 EPBL_a118_VEH_systemStatus 0 "UNKNOWN" 1 "RELEASED" 2 "PARKED" 3 "DYNAMIC" 4 "PARKING" 5 "RELEASING" 6 "FAULT" 7 "FAULT_SECURE" 8 "MISMATCH" ;
VAL_ 1480 EPBL_a120_PARTY_status 0 "DISABLED" 1 "ENABLED" 2 "TEMPORARY_FAILURE" 3 "SNA" ;
VAL_ 1480 EPBL_a181_trailerDetected 0 "NOT_DETECTED" 1 "DETECTED" ;
VAL_ 1480 EPBL_a243_wiperSpeed 0 "SNA" 1 "OFF" 2 "1" 3 "2" 4 "3" 5 "4" 6 "5" 7 "LOW" 8 "HIGH" ;
VAL_ 1480 EPBL_a109_BDY_status 0 "DISABLED" 1 "ENABLED" 2 "TEMPORARY_FAILURE" 3 "SNA" ;
VAL_ 1480 EPBL_a111_PARTY_status 0 "DISABLED" 1 "ENABLED" 2 "TEMPORARY_FAILURE" 3 "SNA" ;
VAL_ 1480 EPBL_a112_CH_status 0 "DISABLED" 1 "ENABLED" 2 "TEMPORARY_FAILURE" 3 "SNA" ;
VAL_ 1480 EPBL_a243_vehiclePowerState 0 "OFF" 1 "CONDITIONING" 2 "ACCESSORY" 3 "DRIVE" ;
VAL_ 1480 EPBL_a110_CH_airbagCutoffStatus 0 "RCM_PASSENGER_AIRBAG_ENABLED" 1 "RCM_PASSENGER_AIRBAG_DISABLED" 3 "SNA" ;
VAL_ 1480 EPBL_a111_CH_status 0 "DISABLED" 1 "ENABLED" 2 "TEMPORARY_FAILURE" 3 "SNA" ;
VAL_ 1480 EPBL_a120_PT_systemStatus 0 "UNKNOWN" 1 "RELEASED" 2 "PARKED" 3 "DYNAMIC" 4 "PARKING" 5 "RELEASING" 6 "FAULT" 7 "FAULT_SECURE" 8 "MISMATCH" ;
VAL_ 1480 EPBL_a243_brakeDiscWipingActive 0 "INACTIVE" 1 "ACTIVE" ;
VAL_ 1480 EPBL_a104_CH_status 0 "DISABLED" 1 "ENABLED" 2 "TEMPORARY_FAILURE" 3 "SNA" ;
VAL_ 1480 EPBL_a104_PARTY_status 0 "DISABLED" 1 "ENABLED" 2 "TEMPORARY_FAILURE" 3 "SNA" ;
VAL_ 1480 EPBL_a263_esmSpeedClass 0 "STOPPED" 1 "SYSTEM_APPLY_OK" 2 "USER_APPLY_OK" 3 "FAST" 4 "UNKNOWN" ;
VAL_ 1480 EPBL_a114_BDY_status 0 "DISABLED" 1 "ENABLED" 2 "TEMPORARY_FAILURE" 3 "SNA" ;
VAL_ 1480 EPBL_a109_CH_status 0 "DISABLED" 1 "ENABLED" 2 "TEMPORARY_FAILURE" 3 "SNA" ;
VAL_ 1480 EPBL_a256_vehiclePowerState 0 "OFF" 1 "CONDITIONING" 2 "ACCESSORY" 3 "DRIVE" ;
VAL_ 1480 EPBL_a357_ambientTemp 4294966273 "SNA" ;
VAL_ 1480 EPBL_a358_ambientTemp 4294966273 "SNA" ;
VAL_ 1480 EPBL_a365_ambientTemp 4294966273 "SNA" ;
VAL_ 1480 EPBL_a366_ambientTemp 4294966273 "SNA" ;
VAL_ 1480 EPBL_a113_VEH_status 0 "DISABLED" 1 "ENABLED" 2 "TEMPORARY_FAILURE" 3 "SNA" ;
VAL_ 1480 EPBL_a116_VEH_status 0 "DISABLED" 1 "ENABLED" 2 "TEMPORARY_FAILURE" 3 "SNA" ;
VAL_ 1480 EPBL_a114_CH_status 0 "DISABLED" 1 "ENABLED" 2 "TEMPORARY_FAILURE" 3 "SNA" ;
VAL_ 1480 EPBL_a253_summonState 0 "INIT" 1 "IDLE" 2 "ARMED" 3 "ACTIVE" 4 "COMPLETE" 5 "FAULT" 6 "UNAVAILABLE" ;
VAL_ 1480 EPBL_a104_VEH_status 0 "DISABLED" 1 "ENABLED" 2 "TEMPORARY_FAILURE" 3 "SNA" ;
VAL_ 1480 EPBL_a117_VEH_status 0 "DISABLED" 1 "ENABLED" 2 "TEMPORARY_FAILURE" 3 "SNA" ;
VAL_ 1480 EPBL_a174_csmFaultReason 0 "NONE" 1 "EPBM_DISABLED" 2 "EPBM_FAULTED" 3 "STATE_MISMATCH" 4 "TIMEOUT_CALIBRATE" 5 "APPLY_BLOCKED" 6 "RELEASE_BLOCKED" 7 "TIMEOUT_APPLY_COMPLETE" 8 "TIMEOUT_APPLY_INRUSH" 9 "TIMEOUT_WAIT_FOR_CLAMP" 10 "TIMEOUT_RELEASE_INRUSH" 11 "TIMEOUT_RELEASE_WAIT_FOR_ENDSTOP" 12 "TIMEOUT_RELEASE_COMPLETE" 13 "TIMEOUT_EPBM_CUTOFF" 14 "TIMEOUT_NO_RAMP" 15 "TIMEOUT_EPBM_START" 16 "MOTOR_IDLE_FAULT" 17 "MOTOR_ACTIVE_FAULT" 18 "MOTOR_NOT_READY" 19 "EPBM_MIA" 20 "NVM_MISMATCH" 21 "REMOTE_MIA" ;
VAL_ 1480 EPBL_a175_csmFaultReason 0 "NONE" 1 "EPBM_DISABLED" 2 "EPBM_FAULTED" 3 "STATE_MISMATCH" 4 "TIMEOUT_CALIBRATE" 5 "APPLY_BLOCKED" 6 "RELEASE_BLOCKED" 7 "TIMEOUT_APPLY_COMPLETE" 8 "TIMEOUT_APPLY_INRUSH" 9 "TIMEOUT_WAIT_FOR_CLAMP" 10 "TIMEOUT_RELEASE_INRUSH" 11 "TIMEOUT_RELEASE_WAIT_FOR_ENDSTOP" 12 "TIMEOUT_RELEASE_COMPLETE" 13 "TIMEOUT_EPBM_CUTOFF" 14 "TIMEOUT_NO_RAMP" 15 "TIMEOUT_EPBM_START" 16 "MOTOR_IDLE_FAULT" 17 "MOTOR_ACTIVE_FAULT" 18 "MOTOR_NOT_READY" 19 "EPBM_MIA" 20 "NVM_MISMATCH" 21 "REMOTE_MIA" ;
VAL_ 1480 EPBL_a176_csmFaultReason 0 "NONE" 1 "EPBM_DISABLED" 2 "EPBM_FAULTED" 3 "STATE_MISMATCH" 4 "TIMEOUT_CALIBRATE" 5 "APPLY_BLOCKED" 6 "RELEASE_BLOCKED" 7 "TIMEOUT_APPLY_COMPLETE" 8 "TIMEOUT_APPLY_INRUSH" 9 "TIMEOUT_WAIT_FOR_CLAMP" 10 "TIMEOUT_RELEASE_INRUSH" 11 "TIMEOUT_RELEASE_WAIT_FOR_ENDSTOP" 12 "TIMEOUT_RELEASE_COMPLETE" 13 "TIMEOUT_EPBM_CUTOFF" 14 "TIMEOUT_NO_RAMP" 15 "TIMEOUT_EPBM_START" 16 "MOTOR_IDLE_FAULT" 17 "MOTOR_ACTIVE_FAULT" 18 "MOTOR_NOT_READY" 19 "EPBM_MIA" 20 "NVM_MISMATCH" 21 "REMOTE_MIA" ;
VAL_ 1480 EPBL_a177_csmFaultReason 0 "NONE" 1 "EPBM_DISABLED" 2 "EPBM_FAULTED" 3 "STATE_MISMATCH" 4 "TIMEOUT_CALIBRATE" 5 "APPLY_BLOCKED" 6 "RELEASE_BLOCKED" 7 "TIMEOUT_APPLY_COMPLETE" 8 "TIMEOUT_APPLY_INRUSH" 9 "TIMEOUT_WAIT_FOR_CLAMP" 10 "TIMEOUT_RELEASE_INRUSH" 11 "TIMEOUT_RELEASE_WAIT_FOR_ENDSTOP" 12 "TIMEOUT_RELEASE_COMPLETE" 13 "TIMEOUT_EPBM_CUTOFF" 14 "TIMEOUT_NO_RAMP" 15 "TIMEOUT_EPBM_START" 16 "MOTOR_IDLE_FAULT" 17 "MOTOR_ACTIVE_FAULT" 18 "MOTOR_NOT_READY" 19 "EPBM_MIA" 20 "NVM_MISMATCH" 21 "REMOTE_MIA" ;
VAL_ 1480 EPBL_a179_csmFaultReason 0 "NONE" 1 "EPBM_DISABLED" 2 "EPBM_FAULTED" 3 "STATE_MISMATCH" 4 "TIMEOUT_CALIBRATE" 5 "APPLY_BLOCKED" 6 "RELEASE_BLOCKED" 7 "TIMEOUT_APPLY_COMPLETE" 8 "TIMEOUT_APPLY_INRUSH" 9 "TIMEOUT_WAIT_FOR_CLAMP" 10 "TIMEOUT_RELEASE_INRUSH" 11 "TIMEOUT_RELEASE_WAIT_FOR_ENDSTOP" 12 "TIMEOUT_RELEASE_COMPLETE" 13 "TIMEOUT_EPBM_CUTOFF" 14 "TIMEOUT_NO_RAMP" 15 "TIMEOUT_EPBM_START" 16 "MOTOR_IDLE_FAULT" 17 "MOTOR_ACTIVE_FAULT" 18 "MOTOR_NOT_READY" 19 "EPBM_MIA" 20 "NVM_MISMATCH" 21 "REMOTE_MIA" ;
VAL_ 1480 EPBL_a183_esmOperationTrigger 0 "PBUTTON_PRESSED_STOPPED" 1 "PBUTTON_PRESSED_OKTOPARK" 2 "PBUTTON_PRESSED_FAST" 3 "PBUTTON_PRESSED_UNKNOWN" 4 "PBUTTON_RELEASED" 5 "ACTIVE_PARK_REQUEST" 6 "DI_UNPARK" 7 "TOUCHSCREEN" 8 "WINCHMODE_EXIT" 9 "WINCHMODE_ENTER" 10 "WINCHMODE_UNAVAILABLE" 11 "SERVICE" 12 "DIAG_CLOSE" 13 "DIAG_OPEN" 14 "DIAG_EXIT" 15 "USER_CONFIRMED" 16 "USER_CANCEL" 17 "SPEED_STOPPED" 18 "SPEED_OKAYTOPARK" 19 "SPEED_FAST" 20 "TIMEOUT" 21 "SAVESTATE_ON_BOOT" 22 "REAPPLY" 23 "SUMMON_COMPLETE" 24 "FAULT" 25 "SUMMON_FAULT" 26 "DISQUALIFIED" 27 "EPBM_DISQUALIFIED" 28 "ACCELERATION" 29 "SYSTEM_APPLY" 30 "DRIVER_IS_LEAVING" 31 "AUTOPARK_END" ;
VAL_ 1480 EPBL_a190_csmFaultReason 0 "NONE" 1 "EPBM_DISABLED" 2 "EPBM_FAULTED" 3 "STATE_MISMATCH" 4 "TIMEOUT_CALIBRATE" 5 "APPLY_BLOCKED" 6 "RELEASE_BLOCKED" 7 "TIMEOUT_APPLY_COMPLETE" 8 "TIMEOUT_APPLY_INRUSH" 9 "TIMEOUT_WAIT_FOR_CLAMP" 10 "TIMEOUT_RELEASE_INRUSH" 11 "TIMEOUT_RELEASE_WAIT_FOR_ENDSTOP" 12 "TIMEOUT_RELEASE_COMPLETE" 13 "TIMEOUT_EPBM_CUTOFF" 14 "TIMEOUT_NO_RAMP" 15 "TIMEOUT_EPBM_START" 16 "MOTOR_IDLE_FAULT" 17 "MOTOR_ACTIVE_FAULT" 18 "MOTOR_NOT_READY" 19 "EPBM_MIA" 20 "NVM_MISMATCH" 21 "REMOTE_MIA" ;
VAL_ 1480 EPBL_a191_csmFaultReason 0 "NONE" 1 "EPBM_DISABLED" 2 "EPBM_FAULTED" 3 "STATE_MISMATCH" 4 "TIMEOUT_CALIBRATE" 5 "APPLY_BLOCKED" 6 "RELEASE_BLOCKED" 7 "TIMEOUT_APPLY_COMPLETE" 8 "TIMEOUT_APPLY_INRUSH" 9 "TIMEOUT_WAIT_FOR_CLAMP" 10 "TIMEOUT_RELEASE_INRUSH" 11 "TIMEOUT_RELEASE_WAIT_FOR_ENDSTOP" 12 "TIMEOUT_RELEASE_COMPLETE" 13 "TIMEOUT_EPBM_CUTOFF" 14 "TIMEOUT_NO_RAMP" 15 "TIMEOUT_EPBM_START" 16 "MOTOR_IDLE_FAULT" 17 "MOTOR_ACTIVE_FAULT" 18 "MOTOR_NOT_READY" 19 "EPBM_MIA" 20 "NVM_MISMATCH" 21 "REMOTE_MIA" ;
VAL_ 1480 EPBL_a247_csmFaultReason 0 "NONE" 1 "EPBM_DISABLED" 2 "EPBM_FAULTED" 3 "STATE_MISMATCH" 4 "TIMEOUT_CALIBRATE" 5 "APPLY_BLOCKED" 6 "RELEASE_BLOCKED" 7 "TIMEOUT_APPLY_COMPLETE" 8 "TIMEOUT_APPLY_INRUSH" 9 "TIMEOUT_WAIT_FOR_CLAMP" 10 "TIMEOUT_RELEASE_INRUSH" 11 "TIMEOUT_RELEASE_WAIT_FOR_ENDSTOP" 12 "TIMEOUT_RELEASE_COMPLETE" 13 "TIMEOUT_EPBM_CUTOFF" 14 "TIMEOUT_NO_RAMP" 15 "TIMEOUT_EPBM_START" 16 "MOTOR_IDLE_FAULT" 17 "MOTOR_ACTIVE_FAULT" 18 "MOTOR_NOT_READY" 19 "EPBM_MIA" 20 "NVM_MISMATCH" 21 "REMOTE_MIA" ;
VAL_ 1480 EPBL_a248_csmFaultReason 0 "NONE" 1 "EPBM_DISABLED" 2 "EPBM_FAULTED" 3 "STATE_MISMATCH" 4 "TIMEOUT_CALIBRATE" 5 "APPLY_BLOCKED" 6 "RELEASE_BLOCKED" 7 "TIMEOUT_APPLY_COMPLETE" 8 "TIMEOUT_APPLY_INRUSH" 9 "TIMEOUT_WAIT_FOR_CLAMP" 10 "TIMEOUT_RELEASE_INRUSH" 11 "TIMEOUT_RELEASE_WAIT_FOR_ENDSTOP" 12 "TIMEOUT_RELEASE_COMPLETE" 13 "TIMEOUT_EPBM_CUTOFF" 14 "TIMEOUT_NO_RAMP" 15 "TIMEOUT_EPBM_START" 16 "MOTOR_IDLE_FAULT" 17 "MOTOR_ACTIVE_FAULT" 18 "MOTOR_NOT_READY" 19 "EPBM_MIA" 20 "NVM_MISMATCH" 21 "REMOTE_MIA" ;
VAL_ 1480 EPBL_a104_BDY_status 0 "DISABLED" 1 "ENABLED" 2 "TEMPORARY_FAILURE" 3 "SNA" ;
VAL_ 1480 EPBL_a182_trailerDetected 0 "NOT_DETECTED" 1 "DETECTED" ;
VAL_ 1480 EPBL_a365_trailerDetected 0 "NOT_DETECTED" 1 "DETECTED" ;
VAL_ 1480 EPBL_a366_trailerDetected 0 "NOT_DETECTED" 1 "DETECTED" ;
VAL_ 1480 EPBL_a198_learnedEpbConfig 0 "UNKNOWN" 1 "MODEL3_BASE" 2 "MODEL3_PERFORMANCE" 3 "MODELS_BASE" 4 "MODELY_BASE" 5 "MODELY_PERFORMANCE" 6 "MODELX_BASE" 7 "MODEL3_PERFORMANCE_V2" 8 "MODELY_PERFORMANCE_V2" 9 "MODELS_CERAMIC" ;
VAL_ 1480 EPBL_a198_ambientTemp 4294966273 "SNA" ;
VAL_ 1480 EPBL_a357_trailerDetected 0 "NOT_DETECTED" 1 "DETECTED" ;
VAL_ 1480 EPBL_a358_trailerDetected 0 "NOT_DETECTED" 1 "DETECTED" ;
VAL_ 1480 EPBL_a198_version 254 "LOCAL_BUILD" 255 "SNA" ;
VAL_ 1523 UI_odometer 16777215 "SNA" ;
VAL_ 1531 SDCR_alertID 0 "ALERT_DO_NOT_USE_ZERO" 1 "a001_DriverDoorOpen" 2 "a002_DoorOpen" 3 "a003_TrunkOpen" 4 "a004_FrunkOpen" 5 "a005_HeadlightsOnDoorOpen" 6 "a006_RemoteServiceAlert" 7 "a007_SoftPackConfigMismatch" 8 "a008_TouchScreenError" 9 "a009_SquashfsError" 10 "a010_MapsMissing" 11 "a011_IncorrectMap" 12 "a012_NotOnPrivateProperty" 13 "a013_TPMSHardWarning" 14 "a014_TPMSSoftWarning" 15 "a015_TPMSOverPressureWarning" 16 "a016_TPMSTemperatureWarning" 17 "a017_TPMSSystemFault" 18 "a018_SlipStartOn" 19 "a019_ParkBrakeFault" 20 "a020_SteeringReduced" 21 "a021_RearSeatbeltUnbuckled" 22 "a022_ApeFusesEtc" 23 "a023_CellInternetCheckFailed" 24 "a024_WifiInternetCheckFailed" 25 "a025_WifiOnlineCheckFailed" 26 "a026_ModemResetLoopDetected" 27 "a027_AutoSteerMIA" 28 "a028_FrontTrunkPopupClosed" 29 "a029_ModemMIA" 30 "a030_ModemVMCrash" 31 "a031_BrakeFluidLow" 32 "a032_CellModemRecoveryResets" 33 "a033_ApTrialExpired" 34 "a034_WakeupProblem" 35 "a035_AudioWatchdogKernelError" 36 "a036_AudioWatchdogHfpError" 37 "a037_AudioWatchdogXrunStormError" 38 "a038_AudioWatchdogA2bI2cLockupError" 39 "a039_AudioA2bNeedRediscovery" 40 "a040_HomelinkTransmit" 41 "a041_AudioDmesgXrun" 42 "a042_AudioDmesgRtThrottling" 43 "a043_InvalidMapDataOverride" 44 "a044_AudioDmesgDspException" 45 "a045_ECallNeedsService" 46 "a046_BackupCameraStreamError" 47 "a047_CellRoamingDisallowed" 48 "a048_AudioPremiumAmpCheckFailed" 49 "a049_BrakeShiftRequired" 50 "a050_BackupCameraIPUTimeout" 51 "a051_BackupCameraFrameTimeout" 52 "a052_KernelPanicReported" 53 "a053_QtCarExitError" 54 "a054_AudioBoostPowerBad" 55 "a055_ManualECallDisabled" 56 "a056_ManualECallButtonDisconnected" 57 "a057_CellAntennaDisconnected" 58 "a058_GPSAntennaDisconnected" 59 "a059_ECallSpeakerDisconnected" 60 "a060_ECallMicDisconnected" 61 "a061_SIMTestFailed" 62 "a062_ENSTestFailed" 63 "a063_CellularTestFailed" 64 "a064_ModemFirmwareTestFailed" 65 "a065_WiFiRecoveryReset" 66 "a066_GpuHangDetected" 67 "a067_WarnOnI915" 68 "a068_VideoUnexpectedExit" 69 "a069_VideoUDPTimeout" 70 "a070_VideoPipelineWarning" 71 "a071_VideoPipelineError" 72 "a072_ECallAnalogMicFailed" 73 "a073_ECallDigitalMicFailed" 74 "a074_EMMCHangDetected" 75 "a075_BackupCameraInitError" 76 "a076_NumFalseManualECalls" 77 "a077_AudioA2bMicChannelSwap" 78 "a078_DashcamUsbDriveUnmountable" 79 "a079_DashcamUsbDriveFull" 80 "a080_DashcamUsbDriveSlow" 81 "a081_CellModemSearchExpired" 82 "a082_NumModemRebootStuckInECall" 83 "a083_ECallProxyWatchdogTriggered" 84 "a084_SerializerError" 85 "a085_DeserializerError" 86 "a086_TouchEnumerationError" 87 "a087_BmpReset" 88 "a088_CellRemovableSimMissing" 89 "a089_RadioSoftResetError" 90 "a090_RadioPingFailError" 91 "a091_VehicleLinkStall" 92 "a092_updateStarted" 93 "a093_updateEnded" 94 "a094_ModemPowerOnFailure" 95 "a095_CidStorageRunningLow" 96 "a096_VideodPipelineIssueDetected" 97 "a097_AudiodRestarted" 98 "a098_DiskCheckFailure" 99 "a099_eMMCStatusError" 100 "a100_eMMCFTLError" 101 "a101_wifiStackProblem" 102 "a102_A2bDiscoveryFailed" 103 "a103_UsbHubNotEnumerating" 104 "a104_DashcamUsbDriveMissing" 105 "a105_firmwareReinstallRequested" 106 "a106_rebootBackstopTriggered" 107 "a107_DashcamUsbDriveTooBigForVfatFsck" 108 "a108_DashcamUsbDriveGettingFull" 109 "a109_DashcamUsbDriveTooSmall" 110 "a110_DashcamUsbDriveCorrupt" 111 "a111_DashcamUsbDriveWrongPort" 112 "a112_badUSBDevice" 113 "a113_DashcamHasOnboardSentryClips" ;
VAL_ 1531 SDCR_alertState 0 "CLEARED" 1 "SET" ;
VAL_ 1533 UMC_alertID 0 "ALERT_DO_NOT_USE_ZERO" 1 "a001_DriverDoorOpen" 2 "a002_DoorOpen" 3 "a003_TrunkOpen" 4 "a004_FrunkOpen" 5 "a005_HeadlightsOnDoorOpen" 6 "a006_RemoteServiceAlert" 7 "a007_SoftPackConfigMismatch" 8 "a008_TouchScreenError" 9 "a009_SquashfsError" 10 "a010_MapsMissing" 11 "a011_IncorrectMap" 12 "a012_NotOnPrivateProperty" 13 "a013_TPMSHardWarning" 14 "a014_TPMSSoftWarning" 15 "a015_TPMSOverPressureWarning" 16 "a016_TPMSTemperatureWarning" 17 "a017_TPMSSystemFault" 18 "a018_SlipStartOn" 19 "a019_ParkBrakeFault" 20 "a020_SteeringReduced" 21 "a021_RearSeatbeltUnbuckled" 22 "a022_ApeFusesEtc" 23 "a023_CellInternetCheckFailed" 24 "a024_WifiInternetCheckFailed" 25 "a025_WifiOnlineCheckFailed" 26 "a026_ModemResetLoopDetected" 27 "a027_AutoSteerMIA" 28 "a028_FrontTrunkPopupClosed" 29 "a029_ModemMIA" 30 "a030_ModemVMCrash" 31 "a031_BrakeFluidLow" 32 "a032_CellModemRecoveryResets" 33 "a033_ApTrialExpired" 34 "a034_WakeupProblem" 35 "a035_AudioWatchdogKernelError" 36 "a036_AudioWatchdogHfpError" 37 "a037_AudioWatchdogXrunStormError" 38 "a038_AudioWatchdogA2bI2cLockupError" 39 "a039_AudioA2bNeedRediscovery" 40 "a040_HomelinkTransmit" 41 "a041_AudioDmesgXrun" 42 "a042_AudioDmesgRtThrottling" 43 "a043_InvalidMapDataOverride" 44 "a044_AudioDmesgDspException" 45 "a045_ECallNeedsService" 46 "a046_BackupCameraStreamError" 47 "a047_CellRoamingDisallowed" 48 "a048_AudioPremiumAmpCheckFailed" 49 "a049_BrakeShiftRequired" 50 "a050_BackupCameraIPUTimeout" 51 "a051_BackupCameraFrameTimeout" 52 "a052_KernelPanicReported" 53 "a053_QtCarExitError" 54 "a054_AudioBoostPowerBad" 55 "a055_ManualECallDisabled" 56 "a056_ManualECallButtonDisconnected" 57 "a057_CellAntennaDisconnected" 58 "a058_GPSAntennaDisconnected" 59 "a059_ECallSpeakerDisconnected" 60 "a060_ECallMicDisconnected" 61 "a061_SIMTestFailed" 62 "a062_ENSTestFailed" 63 "a063_CellularTestFailed" 64 "a064_ModemFirmwareTestFailed" 65 "a065_WiFiRecoveryReset" 66 "a066_GpuHangDetected" 67 "a067_WarnOnI915" 68 "a068_VideoUnexpectedExit" 69 "a069_VideoUDPTimeout" 70 "a070_VideoPipelineWarning" 71 "a071_VideoPipelineError" 72 "a072_ECallAnalogMicFailed" 73 "a073_ECallDigitalMicFailed" 74 "a074_EMMCHangDetected" 75 "a075_BackupCameraInitError" 76 "a076_NumFalseManualECalls" 77 "a077_AudioA2bMicChannelSwap" 78 "a078_DashcamUsbDriveUnmountable" 79 "a079_DashcamUsbDriveFull" 80 "a080_DashcamUsbDriveSlow" 81 "a081_CellModemSearchExpired" 82 "a082_NumModemRebootStuckInECall" 83 "a083_ECallProxyWatchdogTriggered" 84 "a084_SerializerError" 85 "a085_DeserializerError" 86 "a086_TouchEnumerationError" 87 "a087_BmpReset" 88 "a088_CellRemovableSimMissing" 89 "a089_RadioSoftResetError" 90 "a090_RadioPingFailError" 91 "a091_VehicleLinkStall" 92 "a092_updateStarted" 93 "a093_updateEnded" 94 "a094_ModemPowerOnFailure" 95 "a095_CidStorageRunningLow" 96 "a096_VideodPipelineIssueDetected" 97 "a097_AudiodRestarted" 98 "a098_DiskCheckFailure" 99 "a099_eMMCStatusError" 100 "a100_eMMCFTLError" 101 "a101_wifiStackProblem" 102 "a102_A2bDiscoveryFailed" 103 "a103_UsbHubNotEnumerating" 104 "a104_DashcamUsbDriveMissing" 105 "a105_firmwareReinstallRequested" 106 "a106_rebootBackstopTriggered" 107 "a107_DashcamUsbDriveTooBigForVfatFsck" 108 "a108_DashcamUsbDriveGettingFull" 109 "a109_DashcamUsbDriveTooSmall" 110 "a110_DashcamUsbDriveCorrupt" 111 "a111_DashcamUsbDriveWrongPort" 112 "a112_badUSBDevice" 113 "a113_DashcamHasOnboardSentryClips" ;
VAL_ 1551 PM_infoIndex 0 "DEPRECATED_0" 1 "DEPRECATED_1" 2 "DEPRECATED_2" 3 "DEPRECATED_3" 4 "DEPRECATED_4" 5 "DEPRECATED_5" 6 "DEPRECATED_6" 7 "DEPRECATED_7" 8 "DEPRECATED_8" 9 "DEPRECATED_9" 10 "BUILD_HWID_COMPONENTID" 11 "PCBAID_ASSYID_USAGEID" 13 "APP_CRC" 14 "BOOTLOADER_SVN" 15 "BOOTLOADER_CRC" 16 "SUBCOMPONENT" 17 "APP_GITHASH" 18 "BOOTLOADER_GITHASH" 19 "VERSION_DEPRECATED" 20 "UDS_PROTOCOL_BOOTCRC" 21 "DI_BUILD_DATA" 255 "END" ;
VAL_ 1551 PM_buildType 0 "UNKNOWN_BUILD" 1 "PLATFORM_BUILD" 2 "LOCAL_BUILD" 3 "TRACEABLE_CI_BUILD" 4 "MFG_BUILD" ;
VAL_ 1551 PM_hardwareId 252 "CONFIGURABLE_HWID_PLACEHOLDER" ;
VAL_ 1597 SDCR_infoIndex 0 "DEPRECATED_0" 1 "DEPRECATED_1" 2 "DEPRECATED_2" 3 "DEPRECATED_3" 4 "DEPRECATED_4" 5 "DEPRECATED_5" 6 "DEPRECATED_6" 7 "DEPRECATED_7" 8 "DEPRECATED_8" 9 "DEPRECATED_9" 10 "BUILD_HWID_COMPONENTID" 11 "PCBAID_ASSYID_USAGEID" 13 "APP_CRC" 14 "BOOTLOADER_SVN" 15 "BOOTLOADER_CRC" 16 "SUBCOMPONENT" 17 "APP_GITHASH" 18 "BOOTLOADER_GITHASH" 19 "VERSION_DEPRECATED" 20 "UDS_PROTOCOL_BOOTCRC" 22 "VARIANTCRC" 25 "PACKAGE_PN_1_7" 26 "PACKAGE_PN_8_14" 27 "PACKAGE_PN_15_20" 29 "PACKAGE_SN_1_7" 30 "PACKAGE_SN_8_14" 31 "SUBCOMPONENT_GITHASH" 255 "END" ;
VAL_ 1597 SDCR_infoBuildType 0 "UNKNOWN_BUILD" 1 "PLATFORM_BUILD" 2 "LOCAL_BUILD" 3 "TRACEABLE_CI_BUILD" 4 "MFG_BUILD" ;
VAL_ 1597 SDCR_infoAssemblyId 1 "ASSEMBLY1" 255 "ASSEMBLY_SNA" ;
VAL_ 1622 DIF_infoIndex 0 "DEPRECATED_0" 1 "DEPRECATED_1" 2 "DEPRECATED_2" 3 "DEPRECATED_3" 4 "DEPRECATED_4" 5 "DEPRECATED_5" 6 "DEPRECATED_6" 7 "DEPRECATED_7" 8 "DEPRECATED_8" 9 "DEPRECATED_9" 10 "BUILD_HWID_COMPONENTID" 11 "PCBAID_ASSYID_USAGEID" 13 "APP_CRC" 14 "BOOTLOADER_SVN" 15 "BOOTLOADER_CRC" 16 "SUBCOMPONENT" 17 "APP_GITHASH" 18 "BOOTLOADER_GITHASH" 19 "VERSION_DEPRECATED" 20 "UDS_PROTOCOL_BOOTCRC" 23 "SUBCOMPONENT2" 31 "SUBCOMPONENT_GITHASH" 32 "SUBCOMPONENT2_GITHASH" 33 "SUBCOMPONENT_HWID" 34 "SUBCOMPONENT2_HWID" 255 "END" ;
VAL_ 1622 DIF_buildType 0 "UNKNOWN_BUILD" 1 "PLATFORM_BUILD" 2 "LOCAL_BUILD" 3 "TRACEABLE_CI_BUILD" 4 "MFG_BUILD" ;
VAL_ 1622 DIF_oilPumpBuildType 0 "UNKNOWN_BUILD" 1 "PLATFORM_BUILD" 2 "LOCAL_BUILD" 3 "TRACEABLE_CI_BUILD" 4 "MFG_BUILD" ;
VAL_ 1622 DIF_hardwareId 252 "CONFIGURABLE_HWID_PLACEHOLDER" ;
VAL_ 1622 DIF_FPGA_version 254 "LOCAL_BUILD" 255 "SNA" ;
VAL_ 1623 DI_infoIndex 0 "DEPRECATED_0" 1 "DEPRECATED_1" 2 "DEPRECATED_2" 3 "DEPRECATED_3" 4 "DEPRECATED_4" 5 "DEPRECATED_5" 6 "DEPRECATED_6" 7 "DEPRECATED_7" 8 "DEPRECATED_8" 9 "DEPRECATED_9" 10 "BUILD_HWID_COMPONENTID" 11 "PCBAID_ASSYID_USAGEID" 13 "APP_CRC" 14 "BOOTLOADER_SVN" 15 "BOOTLOADER_CRC" 16 "SUBCOMPONENT" 17 "APP_GITHASH" 18 "BOOTLOADER_GITHASH" 19 "VERSION_DEPRECATED" 20 "UDS_PROTOCOL_BOOTCRC" 23 "SUBCOMPONENT2" 31 "SUBCOMPONENT_GITHASH" 32 "SUBCOMPONENT2_GITHASH" 33 "SUBCOMPONENT_HWID" 34 "SUBCOMPONENT2_HWID" 255 "END" ;
VAL_ 1623 DI_buildType 0 "UNKNOWN_BUILD" 1 "PLATFORM_BUILD" 2 "LOCAL_BUILD" 3 "TRACEABLE_CI_BUILD" 4 "MFG_BUILD" ;
VAL_ 1623 DI_hardwareId 252 "CONFIGURABLE_HWID_PLACEHOLDER" ;
VAL_ 1638 GTW_diagLevel 0 "FACTORY" 10 "DIAG_LINK_ACTIVE" 25 "SERVICE" 50 "SERVICE_DRIVE" 80 "PARK" 100 "NORMAL_OPERATION" ;
VAL_ 1655 VC_lvbmsStatusHighIndex 0 "PACK_VITALS_1" 1 "CELL_VITALS_1" 2 "CELL_VITALS_2" 3 "TARGETS" 4 "STATE_AND_COMMANDS" 5 "PCS_INTERFACE" 6 "INVALID" ;
VAL_ 1655 VC_LVBMS_packCurrent 4194303 "SNA" ;
VAL_ 1655 VC_LVBMS_voltageTarget 32767 "SNA" ;
VAL_ 1655 VC_LVBMS_ECPAState 0 "OPEN" 1 "CLOSED" 2 "INVALID" 3 "SNA" ;
VAL_ 1655 VC_LVBMS_sumCellVoltage 65534 "INVALID" 65535 "SNA" ;
VAL_ 1655 VC_LVBMS_MOSState 0 "OPEN" 1 "CLOSED" 2 "INVALID" 3 "SNA" ;
VAL_ 1655 VC_LVBMS_VehicleState 0 "DRIVE" 1 "ACCESSORY" 2 "CONDITIONING" 3 "OFF" ;
VAL_ 1655 VC_LVBMS_LINWakeDisabled 0 "ENABLED" 1 "DISABLED" ;
VAL_ 1655 VC_LVBMS_chargeType 0 "UNDEFINED" 1 "CONSTANT_CURRENT" 2 "CONSTANT_VOLTAGE" 3 "COMPLETE" 4 "SNA" ;
VAL_ 1655 VC_LVBMS_currentTarget 32767 "SNA" ;
VAL_ 1655 VC_LVBMS_packVoltage 65535 "SNA" ;
VAL_ 1655 VC_LVBMS_maxAllowedChargeCurrent 8191 "SNA" ;
VAL_ 1655 VC_LVBMS_packTemperature 511 "SNA" ;
VAL_ 1655 VC_LVBMS_MOSTemperature 4095 "SNA" ;
VAL_ 1655 VC_LVBMS_maxAllowedDischargeCurrent 8191 "SNA" ;
VAL_ 1666 HVP_hvilStatus 0 "UNKNOWN" 1 "OK" 2 "FAULT" ;
VAL_ 1680 SCCM_functionalResponseData_0 0 "0" 1 "1" 2 "2" 3 "3" 4 "4" 5 "5" 6 "6" 7 "7" 8 "8" 9 "9" 10 "10" 11 "11" 12 "12" 13 "13" 14 "14" 15 "15" 16 "16" 17 "17" 18 "18" 19 "19" 20 "20" 21 "21" 22 "22" 23 "23" 24 "24" 25 "25" 26 "26" 27 "27" 28 "28" 29 "29" 30 "30" 31 "31" ;
VAL_ 1748 PMR_infoIndex 0 "DEPRECATED_0" 1 "DEPRECATED_1" 2 "DEPRECATED_2" 3 "DEPRECATED_3" 4 "DEPRECATED_4" 5 "DEPRECATED_5" 6 "DEPRECATED_6" 7 "DEPRECATED_7" 8 "DEPRECATED_8" 9 "DEPRECATED_9" 10 "BUILD_HWID_COMPONENTID" 11 "PCBAID_ASSYID_USAGEID" 13 "APP_CRC" 14 "BOOTLOADER_SVN" 15 "BOOTLOADER_CRC" 16 "SUBCOMPONENT" 17 "APP_GITHASH" 18 "BOOTLOADER_GITHASH" 19 "VERSION_DEPRECATED" 20 "UDS_PROTOCOL_BOOTCRC" 21 "DI_BUILD_DATA" 255 "END" ;
VAL_ 1748 PMR_buildType 0 "UNKNOWN_BUILD" 1 "PLATFORM_BUILD" 2 "LOCAL_BUILD" 3 "TRACEABLE_CI_BUILD" 4 "MFG_BUILD" ;
VAL_ 1748 PMR_hardwareId 252 "CONFIGURABLE_HWID_PLACEHOLDER" ;
VAL_ 1793 VCFRONT_debugThermal10HzIndex 0 "heaterAndEvapWatts" 1 "temps" 2 "airflow" 3 "cabinModel" 4 "actuatorStatus" 5 "END" ;
VAL_ 1795 VCRIGHT_debugThermal10HzIndex 0 "HEATER_AND_EVAP_WATTS" 1 "TEMPS" 2 "AIRFLOW" 3 "CABIN_MODEL" 4 "ACTUATOR_STATUS" 5 "END" ;
VAL_ 1795 VCRIGHT_setTempAdjustmentLeft 127 "SNA" ;
VAL_ 1795 VCRIGHT_setTempAdjustmentRight 127 "SNA" ;
VAL_ 1803 VCRIGHT_tempIncarCabinDeep 255 "SNA" ;
VAL_ 1816 VC_lvbmsStatusLowIndex 0 "STATE" 1 "THROUGHPUT_1" 2 "THROUGHPUT_2" 3 "THROUGHPUT_3" 4 "PACK_VITALS_2" 5 "FAULT_STATS" 6 "CELL_VITALS_3" 7 "CELL_VITALS_4" 8 "INVALID" ;
VAL_ 1816 VC_LVBMS_AvgSleepCurrent 65535 "SNA" ;
VAL_ 1816 VC_LVBMS_SOC 127 "SNA" ;
VAL_ 1816 VC_LVBMS_sumCellVoltageFiltered 65534 "INVALID" 65535 "SNA" ;
VAL_ 1816 VC_LVBMS_SOE 127 "SNA" ;
VAL_ 1816 VC_LVBMS_SOH 127 "SNA" ;
VAL_ 1816 VC_LVBMS_TimeSlept 16777215 "SNA" ;
VAL_ 1816 VC_LVBMS_maxCellSOC 127 "SNA" ;
VAL_ 1816 VC_LVBMS_minCellSOC 127 "SNA" ;
VAL_ 1816 VC_LVBMS_staticSOCCorrection 0 "INACTIVE" 1 "ACTIVE" ;
VAL_ 1816 VC_LVBMS_MaxSleepCurrent 65535 "SNA" ;
VAL_ 1816 VC_LVBMS_MinSleepCurrent 65535 "SNA" ;
VAL_ 1816 VC_LVBMS_dynamicSOCCorrection 0 "INACTIVE" 1 "ACTIVE" ;
VAL_ 1816 VC_LVBMS_SOP 16777215 "SNA" ;
VAL_ 1822 GB_EVSE_outputCurrent_value 4294934528 "SNA" ;
VAL_ 1822 GB_FC_maxCurrentLimit 8191 "SNA" ;
VAL_ 1822 GB_EVSE_maxCurrentLimit_value 4294934528 "SNA" ;
